VERSION ""

NS_ :

BS_:

BU_: AGSM BCM BSM CADM DMSM DTCM ECM EVCU2 GNMM HCP IPC RFHM SGW TCM
BO_ 258 BRAKE_FD_2: 64 BSM
 SG_ ABSActive : 83|1@0+ (1,0) [0|1] "-" BCM,DTCM,EVCU2,HCP,SGW,TCM
 SG_ AHH_Ready_Status : 123|3@0+ (1,0) [0|6] "" EVCU2
 SG_ Brake_MaxRegen_Ready : 359|2@0+ (1,0) [0|2] "-" EVCU2
 SG_ BrakeBoostPressure : 370|11@0+ (0.1,0) [0|200] "bar" BCM,ECM,EVCU2,IPC,SGW,TCM
 SG_ BrakeBoostStat : 439|4@0+ (1,0) [0|14] "-" EVCU2,SGW
 SG_ BrakeInterventionSts : 103|1@0+ (1,0) [0|1] "-" BCM,DTCM,ECM,EVCU2,HCP,TCM
 SG_ BrakePedalPressure : 386|11@0+ (0.1,0) [0|200] "bar" BCM,ECM,EVCU2,SGW,TCM
 SG_ Brk_Stat : 343|2@0+ (1,0) [0|2] "-" BCM,ECM,IPC,SGW
 SG_ BSM_ESASystemSts : 239|3@0+ (1,0) [0|6] "" BCM
 SG_ BSM_RequesterFunction : 190|3@0+ (1,0) [0|7] "" IPC
 SG_ CRC_BRAKE2 : 447|8@0+ (1,0) [0|255] "-" AGSM,BCM,CADM,DMSM,DTCM,ECM,EVCU2,GNMM,HCP,IPC,RFHM,SGW,TCM
 SG_ ESCActive : 84|1@0+ (1,0) [0|1] "-" BCM,DTCM,EVCU2,SGW,TCM
 SG_ ESP_Sys_Stat : 71|2@0+ (1,0) [0|3] "-" ECM,HCP,TCM
 SG_ HBAActive : 101|1@0+ (1,0) [0|1] "-" BCM
 SG_ HillHolderActive : 174|1@0+ (1,0) [0|1] "-" BCM
 SG_ ImpendingSkid : 205|1@0+ (1,0) [0|1] "-" EVCU2
 SG_ InternalError_BSM : 191|1@0+ (1,0) [0|1] "-" Vector__XXX
 SG_ LatAcceleration_BSM : 19|12@0+ (0.02,-40.96) [-40.96|40.92] "m/s^2" BCM,CADM,DTCM,ECM,EVCU2,HCP,IPC,SGW,TCM
 SG_ LatAccelerationFailSts_BSM : 68|1@0+ (1,0) [0|1] "-" BCM,CADM,DTCM,ECM,HCP,IPC,SGW
 SG_ LongAcceleration_BSM : 35|12@0+ (0.02,-40.96) [-40.96|40.92] "m/s^2" BCM,CADM,DTCM,ECM,EVCU2,HCP,IPC,SGW,TCM
 SG_ LongAccelerationFailSts_BSM : 69|1@0+ (1,0) [0|1] "-" BCM,CADM,DTCM,ECM,EVCU2,HCP,IPC,SGW
 SG_ MessageCounter_BRAKE2 : 435|4@0+ (1,0) [0|15] "-" AGSM,BCM,CADM,DMSM,DTCM,ECM,EVCU2,GNMM,HCP,IPC,RFHM,SGW,TCM
 SG_ MuSplit : 53|2@0+ (1,0) [0|2] "-" Vector__XXX
 SG_ OverSteering : 119|6@0+ (2,0) [0|124] "%" DTCM,EVCU2
 SG_ ParkingGearShiftReq_BSM : 22|3@0+ (1,0) [0|6] "" AGSM,EVCU2,TCM
 SG_ PrefillActive : 86|1@0+ (1,0) [0|1] "-" CADM
 SG_ Slope : 135|8@0+ (1,-100) [-100|154] "%" DTCM
 SG_ UnderSteering : 407|6@0+ (2,0) [0|124] "%" DTCM,EVCU2
 SG_ VehicleSpeedVSOSig : 4|13@0+ (0.0625,0) [0|511.875] "Km/h" AGSM,BCM,CADM,DMSM,DTCM,ECM,EVCU2,GNMM,HCP,IPC,RFHM,SGW,TCM
 SG_ WheelRPM_FL : 279|16@0+ (0.001953125,0) [0|127.9961] "Rev/s" BCM,EVCU2
 SG_ WheelRPM_FR : 295|16@0+ (0.001953125,0) [0|127.9961] "Rev/s" BCM,EVCU2
 SG_ YawRate_BSM : 67|12@0+ (0.08,-163.84) [-163.84|163.68] "deg/s" BCM,CADM,DTCM,SGW
 SG_ YawRateFailSts_BSM : 87|1@0+ (1,0) [0|1] "-" BCM,CADM,DTCM,SGW

BO_ 259 BRAKE_FD_3: 32 BSM
 SG_ CRC__BRAKE3 : 191|8@0+ (1,0) [0|255] "-" BCM,CADM,DTCM,ECM,EVCU2,GNMM,HCP,TCM
 SG_ LatAccelerationOffset_BSM : 127|8@0+ (0.02,-2.56) [-2.56|2.52] "m/s^2" Vector__XXX
 SG_ LHF_FastPulseCounter : 167|8@0+ (1,0) [0|255] "pulse" BCM,CADM,ECM,EVCU2,GNMM,RFHM,SGW
 SG_ LHF_Spin : 23|2@0+ (1,0) [0|3] "-" BCM,CADM,DTCM,ECM,EVCU2,HCP,SGW,TCM
 SG_ LHF_WheelSensorFailSts : 181|1@0+ (1,0) [0|1] "-" BCM,CADM,DTCM,ECM,EVCU2,SGW
 SG_ LHFWheelSpeed : 20|13@0+ (0.0625,0) [0|511.875] "Km/h" BCM,CADM,DTCM,ECM,EVCU2,GNMM,HCP,SGW,TCM
 SG_ LHR_FastPulseCounter : 151|8@0+ (1,0) [0|255] "pulse" BCM,CADM,ECM,EVCU2,GNMM,RFHM,SGW
 SG_ LHR_Spin : 86|2@0+ (1,0) [0|3] "-" BCM,CADM,DTCM,ECM,EVCU2,HCP,SGW,TCM
 SG_ LHR_WheelSensorFailSts : 87|1@0+ (1,0) [0|1] "-" BCM,CADM,DTCM,ECM,EVCU2,SGW
 SG_ LHRWheelSpeed : 4|13@0+ (0.0625,0) [0|511.875] "Km/h" BCM,CADM,DTCM,ECM,EVCU2,GNMM,HCP,SGW,TCM
 SG_ LongAccelerationOffset_BSM : 119|8@0+ (0.02,-2.56) [-2.56|2.52] "m/s^2" Vector__XXX
 SG_ LwsAngleOffset_BSM : 81|10@0+ (0.1,-51.1) [-51.1|51.1] "°" GNMM
 SG_ MessageCounter_BRAKE3 : 179|4@0+ (1,0) [0|15] "-" BCM,CADM,DTCM,ECM,EVCU2,GNMM,HCP,TCM
 SG_ RHF_FastPulseCounter : 175|8@0+ (1,0) [0|255] "pulse" BCM,CADM,ECM,EVCU2,GNMM,RFHM,SGW
 SG_ RHF_Spin : 7|2@0+ (1,0) [0|3] "-" BCM,CADM,DTCM,ECM,EVCU2,HCP,SGW,TCM
 SG_ RHF_WheelSensorFailSts : 182|1@0+ (1,0) [0|1] "-" BCM,CADM,DTCM,ECM,EVCU2,SGW
 SG_ RHFWheelSpeed : 52|13@0+ (0.0625,0) [0|511.875] "Km/h" BCM,CADM,DTCM,ECM,EVCU2,GNMM,HCP,SGW,TCM
 SG_ RHR_FastPulseCounter : 159|8@0+ (1,0) [0|255] "pulse" BCM,CADM,ECM,EVCU2,GNMM,RFHM,SGW
 SG_ RHR_Spin : 102|2@0+ (1,0) [0|3] "-" BCM,CADM,DTCM,ECM,EVCU2,HCP,SGW,TCM
 SG_ RHR_WheelSensorFailSts : 103|1@0+ (1,0) [0|1] "-" BCM,CADM,DTCM,ECM,EVCU2,SGW
 SG_ RHRWheelSpeed : 68|13@0+ (0.0625,0) [0|511.875] "Km/h" BCM,CADM,DTCM,ECM,EVCU2,GNMM,HCP,SGW,TCM

BO_ 609 BRAKE_FD_4: 32 BSM
 SG_ ASRActive : 90|1@0+ (1,0) [0|1] "-" BCM,DTCM,ECM,EVCU2,SGW,TCM
 SG_ BSM_LnchAbrtSts : 33|2@0+ (1,0) [0|2] "-" ECM,IPC,TCM
 SG_ BSM_LnchCtrl_SftBtn_SelectSts : 0|1@0+ (1,0) [0|1] "-" SGW
 SG_ BSM_LnchMode : 55|3@0+ (1,0) [0|6] "-" BCM,DTCM,ECM,IPC,TCM
 SG_ ClampForce : 88|9@0+ (0.1,-0.1) [0|51] "KN" BCM,SGW
 SG_ CODE_CLR_BSM : 160|1@0+ (1,0) [0|1] "-" ECM
 SG_ CRC_BRAKE4 : 191|8@0+ (1,0) [0|255] "-" BCM,CADM,ECM,EVCU2,HCP,IPC,TCM
 SG_ EPB_HMI_Management : 148|5@0+ (1,0) [0|31] "-" IPC,SGW
 SG_ EPBAutoAppSts : 127|1@0+ (1,0) [0|1] "-" Vector__XXX
 SG_ EPBMaintenanceSts : 128|1@0+ (1,0) [0|1] "-" SGW
 SG_ EPBSts : 115|4@0+ (1,0) [0|14] "-" BCM,CADM,DTCM,ECM,EVCU2,IPC,SGW,TCM
 SG_ EPBSwitchPosition : 119|2@0+ (1,0) [0|3] "-" BCM
 SG_ EPBWarningLampReq : 174|2@0+ (1,0) [0|0] "-" BCM,IPC,SGW
 SG_ ESC_OFF_Hrd_Sft_Button_sts : 151|3@0+ (1,0) [0|6] "-" BCM,SGW
 SG_ ESCSysEmsMlfAtv : 159|1@0+ (1,0) [0|0] "-" Vector__XXX
 SG_ LaunchRPMsetting_BSM : 63|6@0+ (100,1000) [1000|7300] "rpm" SGW
 SG_ LnchCtrl_DisPopupSts : 52|4@0+ (1,0) [0|14] "-" IPC
 SG_ MessageCounter_BRAKE4 : 179|4@0+ (1,0) [0|15] "-" BCM,CADM,ECM,EVCU2,HCP,IPC,TCM
 SG_ MIL_OnRq_BSM : 172|1@0+ (1,0) [0|1] "-" ECM,SGW
 SG_ MSRActive : 92|1@0+ (1,0) [0|1] "-" BCM,EVCU2
 SG_ RedLampReq : 131|2@0+ (1,0) [0|3] "-" IPC
 SG_ REPRGD_PFC_CLR_BSM : 175|1@0+ (1,0) [0|1] "-" ECM
 SG_ TravelDistance : 87|8@0+ (1,0) [0|255] "m" ECM,EVCU2,IPC,SGW

BO_ 1155 BRAKE_FD_5: 32 BSM
 SG_ ABSFailSts : 87|1@0+ (1,0) [0|1] "-" BCM,ECM,EVCU2,IPC,SGW
 SG_ ACCEngaged : 92|1@0+ (1,0) [0|1] "-" DTCM,ECM,EVCU2,SGW,TCM
 SG_ BSM_THA_Brk_Resp : 15|2@0+ (1,0) [0|3] "-" BCM
 SG_ BSMSysSts : 89|2@0+ (1,0) [0|3] "-" SGW
 SG_ CMMIntervention : 86|1@0+ (1,0) [0|1] "-" Vector__XXX
 SG_ CRC_BRAKE5 : 191|8@0+ (1,0) [0|255] "-" BCM,DTCM,ECM,EVCU2,IPC,TCM
 SG_ EBDFailSts : 84|1@0+ (1,0) [0|1] "-" BCM,IPC,SGW
 SG_ ERMActive : 111|1@0+ (1,0) [0|1] "-" BCM,DTCM
 SG_ ESCFailSts : 83|1@0+ (1,0) [0|1] "-" BCM,ECM,EVCU2,IPC,SGW
 SG_ ESCIntervention : 82|1@0+ (1,0) [0|1] "-" BCM,DTCM,EVCU2,IPC
 SG_ Function2Sts : 94|1@0+ (1,0) [0|1] "-" BCM,DTCM,EVCU2,IPC,SGW,TCM
 SG_ FunctionFailSts : 81|1@0+ (1,0) [0|1] "-" Vector__XXX
 SG_ FunctionIntervention : 80|1@0+ (1,0) [0|1] "-" DTCM
 SG_ FunctionSts : 95|1@0+ (1,0) [0|1] "-" BCM,DTCM,EVCU2,IPC
 SG_ HDCUserFdBck : 124|2@0+ (1,0) [0|3] "-" BCM
 SG_ HillHolderFailSts : 7|1@0+ (1,0) [0|1] "-" SGW
 SG_ LnchCtrl_UserFdBck : 1|2@0+ (1,0) [0|2] "-" BCM
 SG_ MessageCounter_BRAKE5 : 179|4@0+ (1,0) [0|15] "-" BCM,DTCM,ECM,EVCU2,IPC,TCM
 SG_ RollsModeAct : 91|1@0+ (1,0) [0|1] "-" DTCM,ECM,EVCU2
 SG_ TSCActive : 110|1@0+ (1,0) [0|1] "-" BCM

BO_ 205 BRAKE_FD_6: 64 BSM
 SG_ Cmnd_TotBrkFrict_AxleTorq : 126|15@0+ (2,0) [0|65532] "Nm" EVCU2
 SG_ CRC_BRAKE_FD_6 : 447|8@0+ (1,0) [0|255] "-" ECM,EVCU2
 SG_ DriverReq_AxleTrq_Enabled_BSM : 175|4@0+ (1,0) [0|15] "" ECM,EVCU2
 SG_ DriverRequested_AxleTrq_BSM : 159|16@0+ (2,-65534) [-65534|65536] "Nm" DTCM,ECM,EVCU2
 SG_ DrvrIntd_TotalBrk_AxleTorq : 142|15@0+ (2,0) [0|65532] "Nm" BCM,EVCU2
 SG_ FrontAxle_Max_Rq_BSM : 55|1@0+ (1,0) [0|1] "" EVCU2
 SG_ FrontAxle_Min_Rq_BSM : 54|1@0+ (1,0) [0|1] "" EVCU2
 SG_ FrontAxle_Rq_BSM : 63|16@0+ (2,-65534) [-65534|65536] "Nm" EVCU2
 SG_ MessageCounter_BRAKE_FD_6 : 435|4@0+ (1,0) [0|15] "-" ECM,EVCU2
 SG_ OPD_Hold_Status : 49|2@0+ (1,0) [0|3] "" EVCU2
 SG_ RearAxle_Max_Rq_BSM : 53|1@0+ (1,0) [0|1] "" EVCU2
 SG_ RearAxle_Min_Rq_BSM : 52|1@0+ (1,0) [0|1] "" EVCU2
 SG_ RearAxle_Rq_BSM : 79|16@0+ (2,-65534) [-65534|65536] "Nm" EVCU2
 SG_ Regen_AxleTorque_Req : 110|15@0+ (2,0) [0|65532] "Nm" EVCU2
 SG_ TotalAxle_Max_Rq_BSM : 51|1@0+ (1,0) [0|1] "" DTCM,ECM,TCM
 SG_ TotalAxle_Min_Rq_BSM : 50|1@0+ (1,0) [0|1] "" ECM,TCM
 SG_ TotalAxle_Rq_BSM : 95|16@0+ (2,-65534) [-65534|65536] "Nm" DTCM,ECM,SGW,TCM
 SG_ WED_MODE_RQ : 47|2@0+ (1,0) [0|3] "" EVCU2

BO_ 514 BRAKE_FD_7: 32 BSM
 SG_ AEB_Type_Brk : 67|4@0+ (1,0) [0|14] "-" BCM,CADM
 SG_ Brake_OpStat_Prim : 82|3@0+ (1,0) [0|5] "" CADM
 SG_ BrakePdlPosn : 63|8@0+ (0.4,0) [0|100] "%" BCM,ECM,EVCU2,SGW,TCM
 SG_ BrkPdl_Flt : 86|1@0+ (1,0) [0|1] "-" BCM,DTCM,ECM,EVCU2,SGW
 SG_ BrkPdl_Stat : 85|2@0+ (1,0) [0|2] "-" BCM,CADM,DTCM,ECM,EVCU2,RFHM,SGW,TCM
 SG_ BSM_OpStat : 74|3@0+ (1,0) [0|5] "" BCM,CADM
 SG_ BSM_ReadyForESS : 181|2@0+ (1,0) [0|2] "-" BCM,ECM
 SG_ CRC_BRAKE7 : 191|8@0+ (1,0) [0|255] "-" BCM,CADM,DTCM,ECM,EVCU2,HCP,TCM
 SG_ MessageCounter_BRAKE7 : 179|4@0+ (1,0) [0|15] "-" BCM,CADM,DTCM,ECM,EVCU2,HCP,TCM
 SG_ PAM_Brk_Rq_RspSts : 28|2@0+ (1,0) [0|3] "-" BCM,IPC
 SG_ R_DIFF_TRQ_RQ : 40|9@0+ (10,0) [0|5100] "Nm" DTCM,EVCU2
 SG_ Rear_Diff_BSM_RQ : 77|2@0+ (1,0) [0|2] "-" BCM,DTCM,EVCU2
 SG_ TrlrBrkRq : 103|6@0+ (2,0) [0|100] "%" BCM

BO_ 257 BRAKE2_FD_1: 64 BCM
 SG_ CRC_BRAKE2_1 : 447|8@0+ (1,0) [0|255] "-" DTCM
 SG_ Ft_RrAxleCoupling_TrqRq_B2 : 143|8@0+ (12,0) [0|3060] "Nm" DTCM
 SG_ Ft_RrTrqCoupling_ModeRq_B2 : 158|2@0+ (1,0) [0|3] "-" DTCM
 SG_ MessageCounter_BRAKE2_1 : 435|4@0+ (1,0) [0|15] "-" DTCM

BO_ 524 BRAKE2_FD_2: 32 BCM
 SG_ Brake_OpStat_Sec : 53|3@0+ (1,0) [0|5] "" CADM
 SG_ BSM2_OpStat : 50|3@0+ (1,0) [0|5] "" BSM,CADM
 SG_ CRC_BRAKE2_2 : 191|8@0+ (1,0) [0|255] "-" BSM,CADM
 SG_ MessageCounter_BRAKE2_2 : 179|4@0+ (1,0) [0|15] "-" BSM,CADM
 SG_ VehicleStandStillSts_B2 : 47|2@0+ (1,0) [0|2] "" CADM

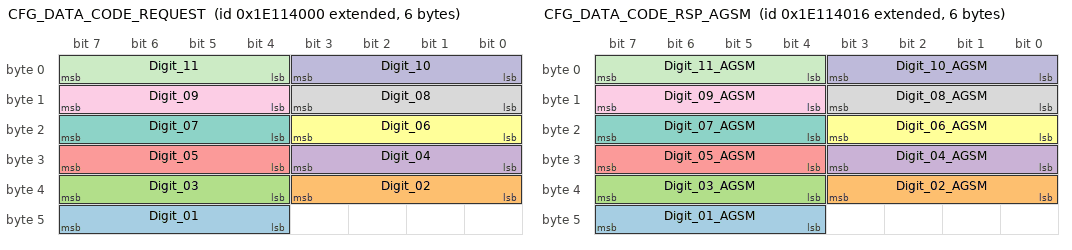
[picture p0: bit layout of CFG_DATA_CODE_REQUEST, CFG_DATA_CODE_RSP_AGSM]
BO_ 2651930624 CFG_DATA_CODE_REQUEST: 6 BCM
 SG_ Digit_01 : 47|4@0+ (1,0) [0|15] "" AGSM,BSM,CADM,DMSM,DTCM,ECM,EVCU2,GNMM,HCP,IPC,RFHM,SGW,TCM
 SG_ Digit_02 : 35|4@0+ (1,0) [0|15] "" AGSM,BSM,CADM,DMSM,DTCM,ECM,EVCU2,GNMM,HCP,IPC,RFHM,SGW,TCM
 SG_ Digit_03 : 39|4@0+ (1,0) [0|15] "" AGSM,BSM,CADM,DMSM,DTCM,ECM,EVCU2,GNMM,HCP,IPC,RFHM,SGW,TCM
 SG_ Digit_04 : 27|4@0+ (1,0) [0|15] "" AGSM,BSM,CADM,DMSM,DTCM,ECM,EVCU2,GNMM,HCP,IPC,RFHM,SGW,TCM
 SG_ Digit_05 : 31|4@0+ (1,0) [0|15] "" AGSM,BSM,CADM,DMSM,DTCM,ECM,EVCU2,GNMM,HCP,IPC,RFHM,SGW,TCM
 SG_ Digit_06 : 19|4@0+ (1,0) [0|15] "" AGSM,BSM,CADM,DMSM,DTCM,ECM,EVCU2,GNMM,HCP,IPC,RFHM,SGW,TCM
 SG_ Digit_07 : 23|4@0+ (1,0) [0|15] "" AGSM,BSM,CADM,DMSM,DTCM,ECM,EVCU2,GNMM,HCP,IPC,RFHM,SGW,TCM
 SG_ Digit_08 : 11|4@0+ (1,0) [0|15] "" AGSM,BSM,CADM,DMSM,DTCM,ECM,EVCU2,GNMM,HCP,IPC,RFHM,SGW,TCM
 SG_ Digit_09 : 15|4@0+ (1,0) [0|15] "" AGSM,BSM,CADM,DMSM,DTCM,ECM,EVCU2,GNMM,HCP,IPC,RFHM,SGW,TCM
 SG_ Digit_10 : 3|4@0+ (1,0) [0|15] "" AGSM,BSM,CADM,DMSM,DTCM,ECM,EVCU2,GNMM,HCP,IPC,RFHM,SGW,TCM
 SG_ Digit_11 : 7|4@0+ (1,0) [0|15] "" AGSM,BSM,CADM,DMSM,DTCM,ECM,EVCU2,GNMM,HCP,IPC,RFHM,SGW,TCM

BO_ 2651930646 CFG_DATA_CODE_RSP_AGSM: 6 AGSM
 SG_ Digit_01_AGSM : 47|4@0+ (1,0) [0|15] "-" BCM
 SG_ Digit_02_AGSM : 35|4@0+ (1,0) [0|15] "-" BCM
 SG_ Digit_03_AGSM : 39|4@0+ (1,0) [0|15] "-" BCM
 SG_ Digit_04_AGSM : 27|4@0+ (1,0) [0|15] "-" BCM
 SG_ Digit_05_AGSM : 31|4@0+ (1,0) [0|15] "-" BCM
 SG_ Digit_06_AGSM : 19|4@0+ (1,0) [0|15] "-" BCM
 SG_ Digit_07_AGSM : 23|4@0+ (1,0) [0|15] "-" BCM
 SG_ Digit_08_AGSM : 11|4@0+ (1,0) [0|15] "-" BCM
 SG_ Digit_09_AGSM : 15|4@0+ (1,0) [0|15] "-" BCM
 SG_ Digit_10_AGSM : 3|4@0+ (1,0) [0|15] "-" BCM
 SG_ Digit_11_AGSM : 7|4@0+ (1,0) [0|15] "-" BCM

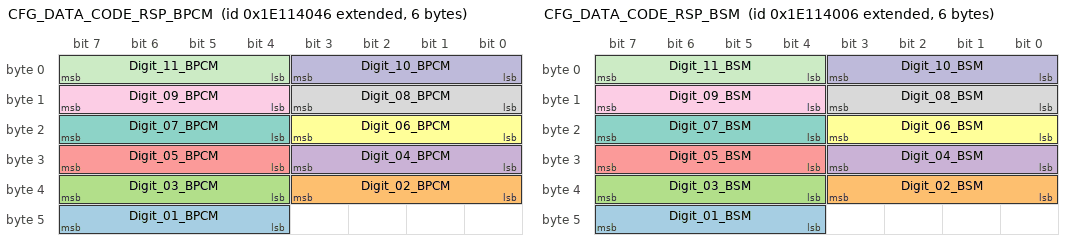
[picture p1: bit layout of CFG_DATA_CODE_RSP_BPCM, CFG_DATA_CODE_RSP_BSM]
BO_ 2651930694 CFG_DATA_CODE_RSP_BPCM: 6 EVCU2
 SG_ Digit_01_BPCM : 47|4@0+ (1,0) [0|15] "-" BCM
 SG_ Digit_02_BPCM : 35|4@0+ (1,0) [0|15] "-" BCM
 SG_ Digit_03_BPCM : 39|4@0+ (1,0) [0|15] "-" BCM
 SG_ Digit_04_BPCM : 27|4@0+ (1,0) [0|15] "-" BCM
 SG_ Digit_05_BPCM : 31|4@0+ (1,0) [0|15] "-" BCM
 SG_ Digit_06_BPCM : 19|4@0+ (1,0) [0|15] "-" BCM
 SG_ Digit_07_BPCM : 23|4@0+ (1,0) [0|15] "-" BCM
 SG_ Digit_08_BPCM : 11|4@0+ (1,0) [0|15] "-" BCM
 SG_ Digit_09_BPCM : 15|4@0+ (1,0) [0|15] "-" BCM
 SG_ Digit_10_BPCM : 3|4@0+ (1,0) [0|15] "-" BCM
 SG_ Digit_11_BPCM : 7|4@0+ (1,0) [0|15] "-" BCM

BO_ 2651930630 CFG_DATA_CODE_RSP_BSM: 6 BSM
 SG_ Digit_01_BSM : 47|4@0+ (1,0) [0|15] "-" BCM
 SG_ Digit_02_BSM : 35|4@0+ (1,0) [0|15] "-" BCM
 SG_ Digit_03_BSM : 39|4@0+ (1,0) [0|15] "-" BCM
 SG_ Digit_04_BSM : 27|4@0+ (1,0) [0|15] "-" BCM
 SG_ Digit_05_BSM : 31|4@0+ (1,0) [0|15] "-" BCM
 SG_ Digit_06_BSM : 19|4@0+ (1,0) [0|15] "-" BCM
 SG_ Digit_07_BSM : 23|4@0+ (1,0) [0|15] "-" BCM
 SG_ Digit_08_BSM : 11|4@0+ (1,0) [0|15] "-" BCM
 SG_ Digit_09_BSM : 15|4@0+ (1,0) [0|15] "-" BCM
 SG_ Digit_10_BSM : 3|4@0+ (1,0) [0|15] "-" BCM
 SG_ Digit_11_BSM : 7|4@0+ (1,0) [0|15] "-" BCM

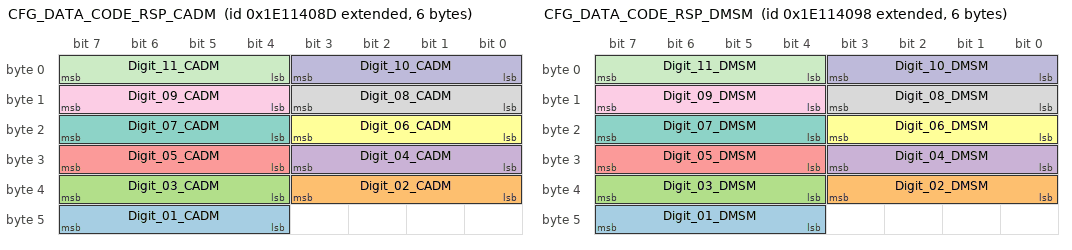
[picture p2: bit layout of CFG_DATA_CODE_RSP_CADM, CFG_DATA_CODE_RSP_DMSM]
BO_ 2651930765 CFG_DATA_CODE_RSP_CADM: 6 CADM
 SG_ Digit_01_CADM : 47|4@0+ (1,0) [0|15] "-" BCM
 SG_ Digit_02_CADM : 35|4@0+ (1,0) [0|15] "-" BCM
 SG_ Digit_03_CADM : 39|4@0+ (1,0) [0|15] "-" BCM
 SG_ Digit_04_CADM : 27|4@0+ (1,0) [0|15] "-" BCM
 SG_ Digit_05_CADM : 31|4@0+ (1,0) [0|15] "-" BCM
 SG_ Digit_06_CADM : 19|4@0+ (1,0) [0|15] "-" BCM
 SG_ Digit_07_CADM : 23|4@0+ (1,0) [0|15] "-" BCM
 SG_ Digit_08_CADM : 11|4@0+ (1,0) [0|15] "-" BCM
 SG_ Digit_09_CADM : 15|4@0+ (1,0) [0|15] "-" BCM
 SG_ Digit_10_CADM : 3|4@0+ (1,0) [0|15] "-" BCM
 SG_ Digit_11_CADM : 7|4@0+ (1,0) [0|15] "-" BCM

BO_ 2651930776 CFG_DATA_CODE_RSP_DMSM: 6 DMSM
 SG_ Digit_01_DMSM : 47|4@0+ (1,0) [0|15] "-" BCM
 SG_ Digit_02_DMSM : 35|4@0+ (1,0) [0|15] "-" BCM
 SG_ Digit_03_DMSM : 39|4@0+ (1,0) [0|15] "-" BCM
 SG_ Digit_04_DMSM : 27|4@0+ (1,0) [0|15] "-" BCM
 SG_ Digit_05_DMSM : 31|4@0+ (1,0) [0|15] "-" BCM
 SG_ Digit_06_DMSM : 19|4@0+ (1,0) [0|15] "-" BCM
 SG_ Digit_07_DMSM : 23|4@0+ (1,0) [0|15] "-" BCM
 SG_ Digit_08_DMSM : 11|4@0+ (1,0) [0|15] "-" BCM
 SG_ Digit_09_DMSM : 15|4@0+ (1,0) [0|15] "-" BCM
 SG_ Digit_10_DMSM : 3|4@0+ (1,0) [0|15] "-" BCM
 SG_ Digit_11_DMSM : 7|4@0+ (1,0) [0|15] "-" BCM

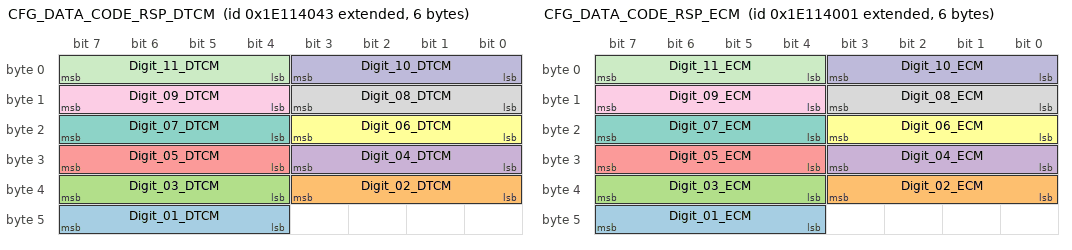
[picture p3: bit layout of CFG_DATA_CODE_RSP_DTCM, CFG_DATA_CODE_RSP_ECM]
BO_ 2651930691 CFG_DATA_CODE_RSP_DTCM: 6 DTCM
 SG_ Digit_01_DTCM : 47|4@0+ (1,0) [0|15] "-" BCM
 SG_ Digit_02_DTCM : 35|4@0+ (1,0) [0|15] "-" BCM
 SG_ Digit_03_DTCM : 39|4@0+ (1,0) [0|15] "-" BCM
 SG_ Digit_04_DTCM : 27|4@0+ (1,0) [0|15] "-" BCM
 SG_ Digit_05_DTCM : 31|4@0+ (1,0) [0|15] "-" BCM
 SG_ Digit_06_DTCM : 19|4@0+ (1,0) [0|15] "-" BCM
 SG_ Digit_07_DTCM : 23|4@0+ (1,0) [0|15] "-" BCM
 SG_ Digit_08_DTCM : 11|4@0+ (1,0) [0|15] "-" BCM
 SG_ Digit_09_DTCM : 15|4@0+ (1,0) [0|15] "-" BCM
 SG_ Digit_10_DTCM : 3|4@0+ (1,0) [0|15] "-" BCM
 SG_ Digit_11_DTCM : 7|4@0+ (1,0) [0|15] "-" BCM

BO_ 2651930625 CFG_DATA_CODE_RSP_ECM: 6 ECM
 SG_ Digit_01_ECM : 47|4@0+ (1,0) [0|15] "-" BCM
 SG_ Digit_02_ECM : 35|4@0+ (1,0) [0|15] "-" BCM
 SG_ Digit_03_ECM : 39|4@0+ (1,0) [0|15] "-" BCM
 SG_ Digit_04_ECM : 27|4@0+ (1,0) [0|15] "-" BCM
 SG_ Digit_05_ECM : 31|4@0+ (1,0) [0|15] "-" BCM
 SG_ Digit_06_ECM : 19|4@0+ (1,0) [0|15] "-" BCM
 SG_ Digit_07_ECM : 23|4@0+ (1,0) [0|15] "-" BCM
 SG_ Digit_08_ECM : 11|4@0+ (1,0) [0|15] "-" BCM
 SG_ Digit_09_ECM : 15|4@0+ (1,0) [0|15] "-" BCM
 SG_ Digit_10_ECM : 3|4@0+ (1,0) [0|15] "-" BCM
 SG_ Digit_11_ECM : 7|4@0+ (1,0) [0|15] "-" BCM

BO_TX_BU_ 2651930694 : EVCU2,HCP;
CM_ SG_ 258 ABSActive "This signal is set to Active when the ABS functionality is active.";
CM_ SG_ 258 AHH_Ready_Status "AHH_Ready_Status";
CM_ SG_ 258 Brake_MaxRegen_Ready "maximum Brake regen ready";
CM_ SG_ 258 BrakeBoostPressure "Pressure Information from Brake Booster Pressure Sensor";
CM_ SG_ 258 BrakeBoostStat "eBoost System Status INIT, eBOOST, PUSH-THROUGH, SNA";
CM_ SG_ 258 BrakeInterventionSts "This signal is ?active? when the brake intervention is due to BSM events and ?not active? when the brake intervention is due to the driver";
CM_ SG_ 258 BrakePedalPressure "Pressure Information from Brake Pedal Simulator Pressure Sensor";
CM_ SG_ 258 Brk_Stat "Brake state";
CM_ SG_ 258 BSM_ESASystemSts "Brake System ESA Status";
CM_ SG_ 258 BSM_RequesterFunction "BSM Requester function";
CM_ SG_ 258 CRC_BRAKE2 "CRC according to SAE J1850 standard at each frame transmission.";
CM_ SG_ 258 ESCActive "This signal is set to Active when the brake intervention by ESC is active.";
CM_ SG_ 258 ESP_Sys_Stat "0";
CM_ SG_ 258 HBAActive "0";
CM_ SG_ 258 HillHolderActive "0";
CM_ SG_ 258 ImpendingSkid "Impending Skid; impending skid false = [0], impending skid true = [1]";
CM_ SG_ 258 InternalError_BSM "This signal indicates if an internal error has been processed";
CM_ SG_ 258 LatAcceleration_BSM "This signal indicates the Lateral Acceleration Value";
CM_ SG_ 258 LatAccelerationFailSts_BSM "This signal indicates the status of Lateral Acceleration Signal";
CM_ SG_ 258 LongAcceleration_BSM "This signal indicates the Longitudinal Acceleration Value";
CM_ SG_ 258 LongAccelerationFailSts_BSM "This signal indicates the status of Longitudinal acceleration signal";
CM_ SG_ 258 MessageCounter_BRAKE2 "This signal is a counter used for safety checks strategies. This counter is incremented of 1 (one) unit at each frame transmission.";
CM_ SG_ 258 MuSplit "0";
CM_ SG_ 258 OverSteering "0";
CM_ SG_ 258 ParkingGearShiftReq_BSM "CVPAM Request to autonomously shift gears";
CM_ SG_ 258 PrefillActive "This signal indicates the prefill function status.";
CM_ SG_ 258 Slope "Slope value detected by BSM";
CM_ SG_ 258 UnderSteering "0";
CM_ SG_ 258 VehicleSpeedVSOSig "It is the average vehicle speed calculated.";
CM_ SG_ 258 WheelRPM_FL "Wheel RPM front left";
CM_ SG_ 258 WheelRPM_FR "Wheel RPM front right";
CM_ SG_ 258 YawRate_BSM "This signal indicates the Yaw Rate Value";
CM_ SG_ 258 YawRateFailSts_BSM "This signal indicates the Status of Yaw Rate Signal";
CM_ SG_ 259 CRC__BRAKE3 "CRC according to SAE J1850 standard at each frame transmission.";
CM_ SG_ 259 LatAccelerationOffset_BSM "LatAccelerationOffset_BSM";
CM_ SG_ 259 LHF_FastPulseCounter "This signal is the left front wheel pulse counter.";
CM_ SG_ 259 LHF_Spin "This signal indicates the left hand front wheel status";
CM_ SG_ 259 LHF_WheelSensorFailSts "This signal indicates the fail status of LHF sensor";
CM_ SG_ 259 LHFWheelSpeed "This is the value of the left front wheel speed";
CM_ SG_ 259 LHR_FastPulseCounter "This signal is the left rear wheel pulse counter.";
CM_ SG_ 259 LHR_Spin "This signal indicates the left hand rear wheel status";
CM_ SG_ 259 LHR_WheelSensorFailSts "This signal indicates the fail status of LHR sensor";
CM_ SG_ 259 LHRWheelSpeed "This is the value of the left rear wheel speed";
CM_ SG_ 259 LongAccelerationOffset_BSM "LongAccelerationOffset_BSM";
CM_ SG_ 259 LwsAngleOffset_BSM "LwsAngleOffset_BSM";
CM_ SG_ 259 MessageCounter_BRAKE3 "This signal is a counter used for safety checks strategies. This counter is incremented of 1 (one) unit at each frame transmission.";
CM_ SG_ 259 RHF_FastPulseCounter "This signal is the right front wheel pulse counter.";
CM_ SG_ 259 RHF_Spin "This signal indicates the right hand front wheel status";
CM_ SG_ 259 RHF_WheelSensorFailSts "This signal indicates the fail status of RHF sensor";
CM_ SG_ 259 RHFWheelSpeed "This is the value of the right front wheel speed";
CM_ SG_ 259 RHR_FastPulseCounter "This signal is the right rear wheel pulse counter.";
CM_ SG_ 259 RHR_Spin "This signal indicates the right hand rear wheel status";
CM_ SG_ 259 RHR_WheelSensorFailSts "This signal indicates the fail status of RHR sensor";
CM_ SG_ 259 RHRWheelSpeed "This is the value of the right rear wheel speed";
CM_ SG_ 609 ASRActive "This signal is set to Active when the intervention by ASR is Active";
CM_ SG_ 609 BSM_LnchAbrtSts "Launch Control Abort Status";
CM_ SG_ 609 BSM_LnchCtrl_SftBtn_SelectSts "Soft button launch selected; Launch selected = [1]";
CM_ SG_ 609 BSM_LnchMode "Launch Control Status";
CM_ SG_ 609 ClampForce "This signal is used to give information about the EPB Clamp Force";
CM_ SG_ 609 CODE_CLR_BSM "Clear emission related faults";
CM_ SG_ 609 CRC_BRAKE4 "CRC according to SAE J1850 standard at each frame transmission.";
CM_ SG_ 609 EPB_HMI_Management "Management IPC/VP pop-up";
CM_ SG_ 609 EPBAutoAppSts "Status of AutoApply Functionality";
CM_ SG_ 609 EPBMaintenanceSts "Status of Maintenance Functionality";
CM_ SG_ 609 EPBSts "0";
CM_ SG_ 609 EPBSwitchPosition "This signal is used to give information about the postition of the EPB switch";
CM_ SG_ 609 EPBWarningLampReq "EPB warning (fault) lamp active request";
CM_ SG_ 609 ESC_OFF_Hrd_Sft_Button_sts "ESC hard button status";
CM_ SG_ 609 ESCSysEmsMlfAtv "ESC emissions related malfunction active";
CM_ SG_ 609 LaunchRPMsetting_BSM "BSM  Launch RPM setting";
CM_ SG_ 609 LnchCtrl_DisPopupSts "Launch Control Display Popup Status";
CM_ SG_ 609 MessageCounter_BRAKE4 "This signal is a counter used for safety checks strategies. This counter is incremented of 1 (one) unit at each frame transmission.";
CM_ SG_ 609 MIL_OnRq_BSM "MIL switch on request";
CM_ SG_ 609 MSRActive "0";
CM_ SG_ 609 RedLampReq "This signal is used to request the EPB RED Indication";
CM_ SG_ 609 REPRGD_PFC_CLR_BSM "Set readiness to \"incomplete\"";
CM_ SG_ 609 TravelDistance "This signal indicates the travel distance value.";
CM_ SG_ 1155 ABSFailSts "0";
CM_ SG_ 1155 ACCEngaged "ACC is engaged";
CM_ SG_ 1155 BSM_THA_Brk_Resp "BSM braking status for trailer hitch assist";
CM_ SG_ 1155 BSMSysSts "This signal is used by BSM to indicate its mode";
CM_ SG_ 1155 CMMIntervention "0";
CM_ SG_ 1155 CRC_BRAKE5 "CRC according to SAE J1850 standard at each frame transmission.";
CM_ SG_ 1155 EBDFailSts "0";
CM_ SG_ 1155 ERMActive "This signal is set to \"active\" when Electronic Roll Mitigation functionality is acting.";
CM_ SG_ 1155 ESCFailSts "0";
CM_ SG_ 1155 ESCIntervention "0";
CM_ SG_ 1155 Function2Sts "Indicates the partial off status of the ESC/TCS system. [0]: Not_Active - Indicates that the ESC/TCS system is enabled, [1]: Active - Indicates that the ESC/TCS engine management is disabled";
CM_ SG_ 1155 FunctionFailSts "This signal indicates the health status of the traction control system. [0]: Fail_Not_Present, [1]: Fail_Present";
CM_ SG_ 1155 FunctionIntervention "This signal indicates the BSM is actively controlling the vehicle through either engine torque management or brake pressure modulation.";
CM_ SG_ 1155 FunctionSts "Indicates the full off status of the ESC/TCS system. [0]: Not_Active - Indicates that the ESC/TCS system is enabled, [1]: Active - Indicates that the ESC/TCS system is completely disabled";
CM_ SG_ 1155 HDCUserFdBck "This signal is used by BSM drive the feedback to the driver command";
CM_ SG_ 1155 HillHolderFailSts "Hill Holder function fail status";
CM_ SG_ 1155 LnchCtrl_UserFdBck "Launch Comtrol Hardn Button LED status";
CM_ SG_ 1155 MessageCounter_BRAKE5 "This signal is a counter used for safety checks strategies. This counter is incremented of 1 (one) unit at each frame transmission.";
CM_ SG_ 1155 RollsModeAct "This signal indicates when the brake system module is in the Rolls Test mode.";
CM_ SG_ 1155 TSCActive "This signal is set to \"active\" when Trailer Sway Control functionality is acting";
CM_ SG_ 205 Cmnd_TotBrkFrict_AxleTorq "Commanded Total Brake Friction torque in Axle domain";
CM_ SG_ 205 CRC_BRAKE_FD_6 "CRC according to SAE J1850 standard at each frame transmission.";
CM_ SG_ 205 DriverReq_AxleTrq_Enabled_BSM "It indicates the request to enable virtual driver torque interface for BSM driver functions";
CM_ SG_ 205 DriverRequested_AxleTrq_BSM "Virtual driver torque request from BSM";
CM_ SG_ 205 DrvrIntd_TotalBrk_AxleTorq "Driver Simulated Brake Torque, Regenerative B raking and Friction Braking";
CM_ SG_ 205 FrontAxle_Max_Rq_BSM "Front axle traction torque max limit flag. Active = [1]";
CM_ SG_ 205 FrontAxle_Min_Rq_BSM "Front axle traction torque min limit flag. Active = [1]";
CM_ SG_ 205 FrontAxle_Rq_BSM "Front axle traction control torque request";
CM_ SG_ 205 MessageCounter_BRAKE_FD_6 "This signal is a counter used for safety checks strategies. This counter is incremented of 1 (one) unit at each frame transmission.";
CM_ SG_ 205 OPD_Hold_Status "Hold status from the brake controller in One Pedal Drive";
CM_ SG_ 205 RearAxle_Max_Rq_BSM "Rear axle traction torque max limit  flag. Active = [1]";
CM_ SG_ 205 RearAxle_Min_Rq_BSM "Rear axle traction torque min limit  flag. Active = [1]";
CM_ SG_ 205 RearAxle_Rq_BSM "Rear axle traction control torque request";
CM_ SG_ 205 Regen_AxleTorque_Req "Regenerative Braking Torque request in Axle domain";
CM_ SG_ 205 TotalAxle_Max_Rq_BSM "Combined axle traction torque max limit flag. Active = [1]";
CM_ SG_ 205 TotalAxle_Min_Rq_BSM "Combined axle traction torque min limit flag. Active = [1]";
CM_ SG_ 205 TotalAxle_Rq_BSM "Combined axle traction torque request";
CM_ SG_ 205 WED_MODE_RQ "WED Requested Center Differential State";
CM_ SG_ 514 AEB_Type_Brk "AEB type brake signal";
CM_ SG_ 514 Brake_OpStat_Prim "Capability of the Braking system to perform deceleration and/or stability control as reported by primary actuator";
CM_ SG_ 514 BrakePdlPosn "Brake pedal travel sensor 0-100% (0 = upstop)";
CM_ SG_ 514 BrkPdl_Flt "Brake Pedal Fault is active, 1=Faulted";
CM_ SG_ 514 BrkPdl_Stat "Brake pedal state";
CM_ SG_ 514 BSM_OpStat "Capability of the primary brake control module to provide deceleration and/or stability control";
CM_ SG_ 514 BSM_ReadyForESS "BSM Stop Start Ready status";
CM_ SG_ 514 CRC_BRAKE7 "CRC according to SAE J1850 standard at each frame transmission.";
CM_ SG_ 514 MessageCounter_BRAKE7 "This signal is a counter used for safety checks strategies. This counter is incremented of 1 (one) unit at each frame transmission.";
CM_ SG_ 514 PAM_Brk_Rq_RspSts "PAM Brake Request Response Status made by the BSM for Park Assist with Stop.";
CM_ SG_ 514 R_DIFF_TRQ_RQ "Desired Torque for Rear Diff.";
CM_ SG_ 514 Rear_Diff_BSM_RQ "ESP Requested Rear Differential State";
CM_ SG_ 514 TrlrBrkRq "Trailer brake request percentage";
CM_ SG_ 257 CRC_BRAKE2_1 "CRC according to SAE J1850 standard at each frame transmission.";
CM_ SG_ 257 Ft_RrAxleCoupling_TrqRq_B2 "Desired Torque for Center Diff";
CM_ SG_ 257 Ft_RrTrqCoupling_ModeRq_B2 "ESP Requested Center Differential State";
CM_ SG_ 257 MessageCounter_BRAKE2_1 "This signal is a counter used for safety checks strategies. This counter is incremented of 1 (one) unit at each frame transmission.";
CM_ SG_ 524 Brake_OpStat_Sec "Capability of the Braking system to perform deceleration and/or stability control as reported by the secondary actuator.";
CM_ SG_ 524 BSM2_OpStat "Capability of the secondary brake control module to provide deceleration and/or stability control";
CM_ SG_ 524 CRC_BRAKE2_2 "CRC according to SAE J1850 standard at each frame transmission.";
CM_ SG_ 524 MessageCounter_BRAKE2_2 "This signal is a counter used for safety checks strategies. This counter is incremented of 1 (one) unit at each frame transmission.";
CM_ SG_ 524 VehicleStandStillSts_B2 "VehicleStandStillSts_B2";

BA_DEF_ SG_ "GenSigStartValue" INT 0 2147483647;
BA_DEF_ SG_ "GenSigInactiveValue" INT 0 2147483647;
BA_DEF_ SG_ "GenSigSendType" ENUM "NotUsed","OnWrite","OnWriteWithRepetition","OnChange","OnChangeWithRepetition","IfActive","IfActiveWithRepetition","NoSigSendType";
BA_DEF_ SG_ "SystemSignalLongSymbol" STRING ;
BA_DEF_ SG_ "GenSigTimeoutTime_AGSM" INT 0 65535;
BA_DEF_ SG_ "GenSigTimeoutTime_BCM" INT 0 65535;
BA_DEF_ SG_ "GenSigTimeoutTime_BSM" INT 0 65535;
BA_DEF_ SG_ "GenSigTimeoutTime_CADM" INT 0 65535;
BA_DEF_ SG_ "GenSigTimeoutTime_DMSM" INT 0 65535;
BA_DEF_ SG_ "GenSigTimeoutTime_DTCM" INT 0 65535;
BA_DEF_ SG_ "GenSigTimeoutTime_ECM" INT 0 65535;
BA_DEF_ SG_ "GenSigTimeoutTime_EVCU2" INT 0 65535;
BA_DEF_ SG_ "GenSigTimeoutTime_GNMM" INT 0 65535;
BA_DEF_ SG_ "GenSigTimeoutTime_HCP" INT 0 65535;
BA_DEF_ SG_ "GenSigTimeoutTime_IPC" INT 0 65535;
BA_DEF_ SG_ "GenSigTimeoutTime_RFHM" INT 0 65535;
BA_DEF_ SG_ "GenSigTimeoutTime_SGW" INT 0 65535;
BA_DEF_ SG_ "GenSigTimeoutTime_TCM" INT 0 65535;
BA_DEF_ BO_ "DiagRequest" ENUM "No","Yes";
BA_DEF_ BO_ "Type" ENUM "P","C","PE","COC","PE_Cntrl","E","E_Cntrl","OC","S","BAF","DC","EM","MM","ISO-TP","-";
BA_DEF_ BO_ "DiagResponse" ENUM "No","Yes";
BA_DEF_ BO_ "NmMessage" ENUM "No","Yes";
BA_DEF_ BO_ "GenMsgSendType" ENUM "Cyclic","NotUsed","NotUsed","NotUsed","NotUsed","NotUsed","NotUsed","NotUsed","NoMsgSendType";
BA_DEF_ BO_ "GenMsgNrOfRepetition" INT 0 255;
BA_DEF_ BO_ "GenMsgILSupport" ENUM "No","Yes";
BA_DEF_ BO_ "GenMsgStartDelayTime" INT 0 65535;
BA_DEF_ BO_ "GenMsgCycleTimeFast" INT 0 65535;
BA_DEF_ BO_ "GenMsgCycleTime" INT 0 65535;
BA_DEF_ BO_ "GenMsgDelayTime" INT 0 65535;
BA_DEF_ BO_ "NmAsrMessage" ENUM "No","Yes";
BA_DEF_ BO_ "DiagState" ENUM "No","Yes";
BA_DEF_ BO_ "DiagConnection" HEX 0 65535;
BA_DEF_ BO_ "VFrameFormat" ENUM "StandardCAN","ExtendedCAN","reserved","reserved","reserved","reserved","reserved","reserved","reserved","reserved","reserved","reserved","reserved","reserved","StandardCAN_FD","ExtendedCAN_FD";
BA_DEF_ BO_ "CANFD_BRS" ENUM "0","1";
BA_DEF_DEF_ "DiagRequest" "No";
BA_DEF_DEF_ "Type" "-";
BA_DEF_DEF_ "DiagResponse" "No";
BA_DEF_DEF_ "NmMessage" "No";
BA_DEF_DEF_ "GenMsgSendType" "NoMsgSendType";
BA_DEF_DEF_ "GenMsgNrOfRepetition" 0;
BA_DEF_DEF_ "GenMsgILSupport" "No";
BA_DEF_DEF_ "GenMsgStartDelayTime" 0;
BA_DEF_DEF_ "GenMsgCycleTimeFast" 0;
BA_DEF_DEF_ "GenMsgCycleTime" 0;
BA_DEF_DEF_ "GenMsgDelayTime" 0;
BA_DEF_DEF_ "NmAsrMessage" "No";
BA_DEF_DEF_ "DiagState" "No";
BA_DEF_DEF_ "DiagConnection" 0;
BA_DEF_DEF_ "VFrameFormat" "StandardCAN_FD";
BA_DEF_DEF_ "CANFD_BRS" "0";
BA_DEF_DEF_ "GenSigStartValue" 0;
BA_DEF_DEF_ "GenSigInactiveValue" 0;
BA_DEF_DEF_ "GenSigSendType" "NoSigSendType";
BA_DEF_DEF_ "SystemSignalLongSymbol" "";
BA_DEF_DEF_ "GenSigTimeoutTime_AGSM" 2500;
BA_DEF_DEF_ "GenSigTimeoutTime_BCM" 2500;
BA_DEF_DEF_ "GenSigTimeoutTime_BSM" 2500;
BA_DEF_DEF_ "GenSigTimeoutTime_CADM" 2500;
BA_DEF_DEF_ "GenSigTimeoutTime_DMSM" 2500;
BA_DEF_DEF_ "GenSigTimeoutTime_DTCM" 2500;
BA_DEF_DEF_ "GenSigTimeoutTime_ECM" 2500;
BA_DEF_DEF_ "GenSigTimeoutTime_EVCU2" 2500;
BA_DEF_DEF_ "GenSigTimeoutTime_GNMM" 2500;
BA_DEF_DEF_ "GenSigTimeoutTime_HCP" 2500;
BA_DEF_DEF_ "GenSigTimeoutTime_IPC" 2500;
BA_DEF_DEF_ "GenSigTimeoutTime_RFHM" 2500;
BA_DEF_DEF_ "GenSigTimeoutTime_SGW" 2500;
BA_DEF_DEF_ "GenSigTimeoutTime_TCM" 2500;
BA_ "Type" BO_ 258 1;
BA_ "GenMsgSendType" BO_ 258 0;
BA_ "GenMsgILSupport" BO_ 258 1;
BA_ "GenMsgCycleTime" BO_ 258 10;
BA_ "CANFD_BRS" BO_ 258 1;
BA_ "Type" BO_ 259 1;
BA_ "GenMsgSendType" BO_ 259 0;
BA_ "GenMsgILSupport" BO_ 259 1;
BA_ "GenMsgCycleTime" BO_ 259 10;
BA_ "CANFD_BRS" BO_ 259 1;
BA_ "Type" BO_ 609 3;
BA_ "GenMsgSendType" BO_ 609 0;
BA_ "GenMsgNrOfRepetition" BO_ 609 2;
BA_ "GenMsgILSupport" BO_ 609 1;
BA_ "GenMsgCycleTimeFast" BO_ 609 20;
BA_ "GenMsgCycleTime" BO_ 609 100;
BA_ "CANFD_BRS" BO_ 609 1;
BA_ "Type" BO_ 1155 3;
BA_ "GenMsgSendType" BO_ 1155 0;
BA_ "GenMsgNrOfRepetition" BO_ 1155 2;
BA_ "GenMsgILSupport" BO_ 1155 1;
BA_ "GenMsgCycleTimeFast" BO_ 1155 20;
BA_ "GenMsgCycleTime" BO_ 1155 500;
BA_ "GenMsgDelayTime" BO_ 1155 20;
BA_ "CANFD_BRS" BO_ 1155 1;
BA_ "Type" BO_ 205 1;
BA_ "GenMsgSendType" BO_ 205 0;
BA_ "GenMsgILSupport" BO_ 205 1;
BA_ "GenMsgCycleTime" BO_ 205 10;
BA_ "CANFD_BRS" BO_ 205 1;
BA_ "Type" BO_ 514 1;
BA_ "GenMsgSendType" BO_ 514 0;
BA_ "GenMsgILSupport" BO_ 514 1;
BA_ "GenMsgCycleTime" BO_ 514 20;
BA_ "CANFD_BRS" BO_ 514 1;
BA_ "Type" BO_ 257 1;
BA_ "GenMsgSendType" BO_ 257 0;
BA_ "GenMsgILSupport" BO_ 257 1;
BA_ "GenMsgCycleTime" BO_ 257 10;
BA_ "CANFD_BRS" BO_ 257 1;
BA_ "Type" BO_ 524 1;
BA_ "GenMsgSendType" BO_ 524 0;
BA_ "GenMsgILSupport" BO_ 524 1;
BA_ "GenMsgCycleTime" BO_ 524 20;
BA_ "CANFD_BRS" BO_ 524 1;
BA_ "Type" BO_ 2651930624 8;
BA_ "GenMsgILSupport" BO_ 2651930624 1;
BA_ "GenMsgDelayTime" BO_ 2651930624 10;
BA_ "VFrameFormat" BO_ 2651930624 15;
BA_ "CANFD_BRS" BO_ 2651930624 1;
BA_ "Type" BO_ 2651930646 11;
BA_ "GenMsgILSupport" BO_ 2651930646 1;
BA_ "VFrameFormat" BO_ 2651930646 15;
BA_ "CANFD_BRS" BO_ 2651930646 1;
BA_ "Type" BO_ 2651930694 11;
BA_ "GenMsgILSupport" BO_ 2651930694 1;
BA_ "VFrameFormat" BO_ 2651930694 15;
BA_ "CANFD_BRS" BO_ 2651930694 1;
BA_ "Type" BO_ 2651930630 11;
BA_ "GenMsgILSupport" BO_ 2651930630 1;
BA_ "VFrameFormat" BO_ 2651930630 15;
BA_ "CANFD_BRS" BO_ 2651930630 1;
BA_ "Type" BO_ 2651930765 11;
BA_ "GenMsgILSupport" BO_ 2651930765 1;
BA_ "VFrameFormat" BO_ 2651930765 15;
BA_ "CANFD_BRS" BO_ 2651930765 1;
BA_ "Type" BO_ 2651930776 11;
BA_ "GenMsgILSupport" BO_ 2651930776 1;
BA_ "VFrameFormat" BO_ 2651930776 15;
BA_ "CANFD_BRS" BO_ 2651930776 1;
BA_ "Type" BO_ 2651930691 11;
BA_ "GenMsgILSupport" BO_ 2651930691 1;
BA_ "VFrameFormat" BO_ 2651930691 15;
BA_ "CANFD_BRS" BO_ 2651930691 1;
BA_ "Type" BO_ 2651930625 11;
BA_ "GenMsgILSupport" BO_ 2651930625 1;
BA_ "VFrameFormat" BO_ 2651930625 15;
BA_ "CANFD_BRS" BO_ 2651930625 1;
BA_ "GenSigTimeoutTime_AGSM" SG_ 258 ABSActive 0;
BA_ "GenSigTimeoutTime_BSM" SG_ 258 ABSActive 0;
BA_ "GenSigTimeoutTime_CADM" SG_ 258 ABSActive 0;
BA_ "GenSigTimeoutTime_DMSM" SG_ 258 ABSActive 0;
BA_ "GenSigTimeoutTime_ECM" SG_ 258 ABSActive 0;
BA_ "GenSigTimeoutTime_GNMM" SG_ 258 ABSActive 0;
BA_ "GenSigTimeoutTime_IPC" SG_ 258 ABSActive 0;
BA_ "GenSigTimeoutTime_RFHM" SG_ 258 ABSActive 0;
BA_ "GenSigTimeoutTime_AGSM" SG_ 258 AHH_Ready_Status 0;
BA_ "GenSigTimeoutTime_BCM" SG_ 258 AHH_Ready_Status 0;
BA_ "GenSigTimeoutTime_BSM" SG_ 258 AHH_Ready_Status 0;
BA_ "GenSigTimeoutTime_CADM" SG_ 258 AHH_Ready_Status 0;
BA_ "GenSigTimeoutTime_DMSM" SG_ 258 AHH_Ready_Status 0;
BA_ "GenSigTimeoutTime_DTCM" SG_ 258 AHH_Ready_Status 0;
BA_ "GenSigTimeoutTime_ECM" SG_ 258 AHH_Ready_Status 0;
BA_ "GenSigTimeoutTime_GNMM" SG_ 258 AHH_Ready_Status 0;
BA_ "GenSigTimeoutTime_HCP" SG_ 258 AHH_Ready_Status 0;
BA_ "GenSigTimeoutTime_IPC" SG_ 258 AHH_Ready_Status 0;
BA_ "GenSigTimeoutTime_RFHM" SG_ 258 AHH_Ready_Status 0;
BA_ "GenSigTimeoutTime_SGW" SG_ 258 AHH_Ready_Status 0;
BA_ "GenSigTimeoutTime_TCM" SG_ 258 AHH_Ready_Status 0;
BA_ "GenSigTimeoutTime_AGSM" SG_ 258 Brake_MaxRegen_Ready 0;
BA_ "GenSigTimeoutTime_BCM" SG_ 258 Brake_MaxRegen_Ready 0;
BA_ "GenSigTimeoutTime_BSM" SG_ 258 Brake_MaxRegen_Ready 0;
BA_ "GenSigTimeoutTime_CADM" SG_ 258 Brake_MaxRegen_Ready 0;
BA_ "GenSigTimeoutTime_DMSM" SG_ 258 Brake_MaxRegen_Ready 0;
BA_ "GenSigTimeoutTime_DTCM" SG_ 258 Brake_MaxRegen_Ready 0;
BA_ "GenSigTimeoutTime_ECM" SG_ 258 Brake_MaxRegen_Ready 0;
BA_ "GenSigTimeoutTime_GNMM" SG_ 258 Brake_MaxRegen_Ready 0;
BA_ "GenSigTimeoutTime_HCP" SG_ 258 Brake_MaxRegen_Ready 0;
BA_ "GenSigTimeoutTime_IPC" SG_ 258 Brake_MaxRegen_Ready 0;
BA_ "GenSigTimeoutTime_RFHM" SG_ 258 Brake_MaxRegen_Ready 0;
BA_ "GenSigTimeoutTime_SGW" SG_ 258 Brake_MaxRegen_Ready 0;
BA_ "GenSigTimeoutTime_TCM" SG_ 258 Brake_MaxRegen_Ready 0;
BA_ "GenSigStartValue" SG_ 258 BrakeBoostPressure 2047;
BA_ "GenSigTimeoutTime_AGSM" SG_ 258 BrakeBoostPressure 0;
BA_ "GenSigTimeoutTime_BSM" SG_ 258 BrakeBoostPressure 0;
BA_ "GenSigTimeoutTime_CADM" SG_ 258 BrakeBoostPressure 0;
BA_ "GenSigTimeoutTime_DMSM" SG_ 258 BrakeBoostPressure 0;
BA_ "GenSigTimeoutTime_DTCM" SG_ 258 BrakeBoostPressure 0;
BA_ "GenSigTimeoutTime_GNMM" SG_ 258 BrakeBoostPressure 0;
BA_ "GenSigTimeoutTime_HCP" SG_ 258 BrakeBoostPressure 0;
BA_ "GenSigTimeoutTime_RFHM" SG_ 258 BrakeBoostPressure 0;
BA_ "GenSigTimeoutTime_AGSM" SG_ 258 BrakeBoostStat 0;
BA_ "GenSigTimeoutTime_BCM" SG_ 258 BrakeBoostStat 0;
BA_ "GenSigTimeoutTime_BSM" SG_ 258 BrakeBoostStat 0;
BA_ "GenSigTimeoutTime_CADM" SG_ 258 BrakeBoostStat 0;
BA_ "GenSigTimeoutTime_DMSM" SG_ 258 BrakeBoostStat 0;
BA_ "GenSigTimeoutTime_DTCM" SG_ 258 BrakeBoostStat 0;
BA_ "GenSigTimeoutTime_ECM" SG_ 258 BrakeBoostStat 0;
BA_ "GenSigTimeoutTime_GNMM" SG_ 258 BrakeBoostStat 0;
BA_ "GenSigTimeoutTime_HCP" SG_ 258 BrakeBoostStat 0;
BA_ "GenSigTimeoutTime_IPC" SG_ 258 BrakeBoostStat 0;
BA_ "GenSigTimeoutTime_RFHM" SG_ 258 BrakeBoostStat 0;
BA_ "GenSigTimeoutTime_TCM" SG_ 258 BrakeBoostStat 0;
BA_ "GenSigTimeoutTime_AGSM" SG_ 258 BrakeInterventionSts 0;
BA_ "GenSigTimeoutTime_BSM" SG_ 258 BrakeInterventionSts 0;
BA_ "GenSigTimeoutTime_CADM" SG_ 258 BrakeInterventionSts 0;
BA_ "GenSigTimeoutTime_DMSM" SG_ 258 BrakeInterventionSts 0;
BA_ "GenSigTimeoutTime_GNMM" SG_ 258 BrakeInterventionSts 0;
BA_ "GenSigTimeoutTime_IPC" SG_ 258 BrakeInterventionSts 0;
BA_ "GenSigTimeoutTime_RFHM" SG_ 258 BrakeInterventionSts 0;
BA_ "GenSigTimeoutTime_SGW" SG_ 258 BrakeInterventionSts 0;
BA_ "GenSigStartValue" SG_ 258 BrakePedalPressure 2047;
BA_ "GenSigTimeoutTime_AGSM" SG_ 258 BrakePedalPressure 0;
BA_ "GenSigTimeoutTime_BSM" SG_ 258 BrakePedalPressure 0;
BA_ "GenSigTimeoutTime_CADM" SG_ 258 BrakePedalPressure 0;
BA_ "GenSigTimeoutTime_DMSM" SG_ 258 BrakePedalPressure 0;
BA_ "GenSigTimeoutTime_DTCM" SG_ 258 BrakePedalPressure 0;
BA_ "GenSigTimeoutTime_GNMM" SG_ 258 BrakePedalPressure 0;
BA_ "GenSigTimeoutTime_HCP" SG_ 258 BrakePedalPressure 0;
BA_ "GenSigTimeoutTime_IPC" SG_ 258 BrakePedalPressure 0;
BA_ "GenSigTimeoutTime_RFHM" SG_ 258 BrakePedalPressure 0;
BA_ "GenSigTimeoutTime_AGSM" SG_ 258 Brk_Stat 0;
BA_ "GenSigTimeoutTime_BSM" SG_ 258 Brk_Stat 0;
BA_ "GenSigTimeoutTime_CADM" SG_ 258 Brk_Stat 0;
BA_ "GenSigTimeoutTime_DMSM" SG_ 258 Brk_Stat 0;
BA_ "GenSigTimeoutTime_DTCM" SG_ 258 Brk_Stat 0;
BA_ "GenSigTimeoutTime_EVCU2" SG_ 258 Brk_Stat 0;
BA_ "GenSigTimeoutTime_GNMM" SG_ 258 Brk_Stat 0;
BA_ "GenSigTimeoutTime_HCP" SG_ 258 Brk_Stat 0;
BA_ "GenSigTimeoutTime_RFHM" SG_ 258 Brk_Stat 0;
BA_ "GenSigTimeoutTime_TCM" SG_ 258 Brk_Stat 0;
BA_ "GenSigTimeoutTime_AGSM" SG_ 258 BSM_ESASystemSts 0;
BA_ "GenSigTimeoutTime_BSM" SG_ 258 BSM_ESASystemSts 0;
BA_ "GenSigTimeoutTime_CADM" SG_ 258 BSM_ESASystemSts 0;
BA_ "GenSigTimeoutTime_DMSM" SG_ 258 BSM_ESASystemSts 0;
BA_ "GenSigTimeoutTime_DTCM" SG_ 258 BSM_ESASystemSts 0;
BA_ "GenSigTimeoutTime_ECM" SG_ 258 BSM_ESASystemSts 0;
BA_ "GenSigTimeoutTime_EVCU2" SG_ 258 BSM_ESASystemSts 0;
BA_ "GenSigTimeoutTime_GNMM" SG_ 258 BSM_ESASystemSts 0;
BA_ "GenSigTimeoutTime_HCP" SG_ 258 BSM_ESASystemSts 0;
BA_ "GenSigTimeoutTime_IPC" SG_ 258 BSM_ESASystemSts 0;
BA_ "GenSigTimeoutTime_RFHM" SG_ 258 BSM_ESASystemSts 0;
BA_ "GenSigTimeoutTime_SGW" SG_ 258 BSM_ESASystemSts 0;
BA_ "GenSigTimeoutTime_TCM" SG_ 258 BSM_ESASystemSts 0;
BA_ "GenSigTimeoutTime_AGSM" SG_ 258 BSM_RequesterFunction 0;
BA_ "GenSigTimeoutTime_BCM" SG_ 258 BSM_RequesterFunction 0;
BA_ "GenSigTimeoutTime_BSM" SG_ 258 BSM_RequesterFunction 0;
BA_ "GenSigTimeoutTime_CADM" SG_ 258 BSM_RequesterFunction 0;
BA_ "GenSigTimeoutTime_DMSM" SG_ 258 BSM_RequesterFunction 0;
BA_ "GenSigTimeoutTime_DTCM" SG_ 258 BSM_RequesterFunction 0;
BA_ "GenSigTimeoutTime_ECM" SG_ 258 BSM_RequesterFunction 0;
BA_ "GenSigTimeoutTime_EVCU2" SG_ 258 BSM_RequesterFunction 0;
BA_ "GenSigTimeoutTime_GNMM" SG_ 258 BSM_RequesterFunction 0;
BA_ "GenSigTimeoutTime_HCP" SG_ 258 BSM_RequesterFunction 0;
BA_ "GenSigTimeoutTime_RFHM" SG_ 258 BSM_RequesterFunction 0;
BA_ "GenSigTimeoutTime_SGW" SG_ 258 BSM_RequesterFunction 0;
BA_ "GenSigTimeoutTime_TCM" SG_ 258 BSM_RequesterFunction 0;
BA_ "GenSigTimeoutTime_BSM" SG_ 258 CRC_BRAKE2 0;
BA_ "GenSigTimeoutTime_AGSM" SG_ 258 ESCActive 0;
BA_ "GenSigTimeoutTime_BSM" SG_ 258 ESCActive 0;
BA_ "GenSigTimeoutTime_CADM" SG_ 258 ESCActive 0;
BA_ "GenSigTimeoutTime_DMSM" SG_ 258 ESCActive 0;
BA_ "GenSigTimeoutTime_ECM" SG_ 258 ESCActive 0;
BA_ "GenSigTimeoutTime_GNMM" SG_ 258 ESCActive 0;
BA_ "GenSigTimeoutTime_HCP" SG_ 258 ESCActive 0;
BA_ "GenSigTimeoutTime_IPC" SG_ 258 ESCActive 0;
BA_ "GenSigTimeoutTime_RFHM" SG_ 258 ESCActive 0;
BA_ "GenSigStartValue" SG_ 258 ESP_Sys_Stat 1;
BA_ "GenSigTimeoutTime_AGSM" SG_ 258 ESP_Sys_Stat 0;
BA_ "GenSigTimeoutTime_BCM" SG_ 258 ESP_Sys_Stat 0;
BA_ "GenSigTimeoutTime_BSM" SG_ 258 ESP_Sys_Stat 0;
BA_ "GenSigTimeoutTime_CADM" SG_ 258 ESP_Sys_Stat 0;
BA_ "GenSigTimeoutTime_DMSM" SG_ 258 ESP_Sys_Stat 0;
BA_ "GenSigTimeoutTime_DTCM" SG_ 258 ESP_Sys_Stat 0;
BA_ "GenSigTimeoutTime_EVCU2" SG_ 258 ESP_Sys_Stat 0;
BA_ "GenSigTimeoutTime_GNMM" SG_ 258 ESP_Sys_Stat 0;
BA_ "GenSigTimeoutTime_IPC" SG_ 258 ESP_Sys_Stat 0;
BA_ "GenSigTimeoutTime_RFHM" SG_ 258 ESP_Sys_Stat 0;
BA_ "GenSigTimeoutTime_SGW" SG_ 258 ESP_Sys_Stat 0;
BA_ "GenSigTimeoutTime_AGSM" SG_ 258 HBAActive 0;
BA_ "GenSigTimeoutTime_BSM" SG_ 258 HBAActive 0;
BA_ "GenSigTimeoutTime_CADM" SG_ 258 HBAActive 0;
BA_ "GenSigTimeoutTime_DMSM" SG_ 258 HBAActive 0;
BA_ "GenSigTimeoutTime_DTCM" SG_ 258 HBAActive 0;
BA_ "GenSigTimeoutTime_ECM" SG_ 258 HBAActive 0;
BA_ "GenSigTimeoutTime_EVCU2" SG_ 258 HBAActive 0;
BA_ "GenSigTimeoutTime_GNMM" SG_ 258 HBAActive 0;
BA_ "GenSigTimeoutTime_HCP" SG_ 258 HBAActive 0;
BA_ "GenSigTimeoutTime_IPC" SG_ 258 HBAActive 0;
BA_ "GenSigTimeoutTime_RFHM" SG_ 258 HBAActive 0;
BA_ "GenSigTimeoutTime_SGW" SG_ 258 HBAActive 0;
BA_ "GenSigTimeoutTime_TCM" SG_ 258 HBAActive 0;
BA_ "GenSigTimeoutTime_AGSM" SG_ 258 HillHolderActive 0;
BA_ "GenSigTimeoutTime_BSM" SG_ 258 HillHolderActive 0;
BA_ "GenSigTimeoutTime_CADM" SG_ 258 HillHolderActive 0;
BA_ "GenSigTimeoutTime_DMSM" SG_ 258 HillHolderActive 0;
BA_ "GenSigTimeoutTime_DTCM" SG_ 258 HillHolderActive 0;
BA_ "GenSigTimeoutTime_ECM" SG_ 258 HillHolderActive 0;
BA_ "GenSigTimeoutTime_EVCU2" SG_ 258 HillHolderActive 0;
BA_ "GenSigTimeoutTime_GNMM" SG_ 258 HillHolderActive 0;
BA_ "GenSigTimeoutTime_HCP" SG_ 258 HillHolderActive 0;
BA_ "GenSigTimeoutTime_IPC" SG_ 258 HillHolderActive 0;
BA_ "GenSigTimeoutTime_RFHM" SG_ 258 HillHolderActive 0;
BA_ "GenSigTimeoutTime_SGW" SG_ 258 HillHolderActive 0;
BA_ "GenSigTimeoutTime_TCM" SG_ 258 HillHolderActive 0;
BA_ "GenSigTimeoutTime_AGSM" SG_ 258 ImpendingSkid 0;
BA_ "GenSigTimeoutTime_BCM" SG_ 258 ImpendingSkid 0;
BA_ "GenSigTimeoutTime_BSM" SG_ 258 ImpendingSkid 0;
BA_ "GenSigTimeoutTime_CADM" SG_ 258 ImpendingSkid 0;
BA_ "GenSigTimeoutTime_DMSM" SG_ 258 ImpendingSkid 0;
BA_ "GenSigTimeoutTime_DTCM" SG_ 258 ImpendingSkid 0;
BA_ "GenSigTimeoutTime_ECM" SG_ 258 ImpendingSkid 0;
BA_ "GenSigTimeoutTime_GNMM" SG_ 258 ImpendingSkid 0;
BA_ "GenSigTimeoutTime_HCP" SG_ 258 ImpendingSkid 0;
BA_ "GenSigTimeoutTime_IPC" SG_ 258 ImpendingSkid 0;
BA_ "GenSigTimeoutTime_RFHM" SG_ 258 ImpendingSkid 0;
BA_ "GenSigTimeoutTime_SGW" SG_ 258 ImpendingSkid 0;
BA_ "GenSigTimeoutTime_TCM" SG_ 258 ImpendingSkid 0;
BA_ "GenSigTimeoutTime_AGSM" SG_ 258 InternalError_BSM 0;
BA_ "GenSigTimeoutTime_BCM" SG_ 258 InternalError_BSM 0;
BA_ "GenSigTimeoutTime_BSM" SG_ 258 InternalError_BSM 0;
BA_ "GenSigTimeoutTime_CADM" SG_ 258 InternalError_BSM 0;
BA_ "GenSigTimeoutTime_DMSM" SG_ 258 InternalError_BSM 0;
BA_ "GenSigTimeoutTime_DTCM" SG_ 258 InternalError_BSM 0;
BA_ "GenSigTimeoutTime_ECM" SG_ 258 InternalError_BSM 0;
BA_ "GenSigTimeoutTime_EVCU2" SG_ 258 InternalError_BSM 0;
BA_ "GenSigTimeoutTime_GNMM" SG_ 258 InternalError_BSM 0;
BA_ "GenSigTimeoutTime_HCP" SG_ 258 InternalError_BSM 0;
BA_ "GenSigTimeoutTime_IPC" SG_ 258 InternalError_BSM 0;
BA_ "GenSigTimeoutTime_RFHM" SG_ 258 InternalError_BSM 0;
BA_ "GenSigTimeoutTime_SGW" SG_ 258 InternalError_BSM 0;
BA_ "GenSigTimeoutTime_TCM" SG_ 258 InternalError_BSM 0;
BA_ "GenSigStartValue" SG_ 258 LatAcceleration_BSM 4095;
BA_ "GenSigTimeoutTime_AGSM" SG_ 258 LatAcceleration_BSM 0;
BA_ "GenSigTimeoutTime_BSM" SG_ 258 LatAcceleration_BSM 0;
BA_ "GenSigTimeoutTime_DMSM" SG_ 258 LatAcceleration_BSM 0;
BA_ "GenSigTimeoutTime_GNMM" SG_ 258 LatAcceleration_BSM 0;
BA_ "GenSigTimeoutTime_RFHM" SG_ 258 LatAcceleration_BSM 0;
BA_ "GenSigTimeoutTime_AGSM" SG_ 258 LatAccelerationFailSts_BSM 0;
BA_ "GenSigTimeoutTime_BSM" SG_ 258 LatAccelerationFailSts_BSM 0;
BA_ "GenSigTimeoutTime_DMSM" SG_ 258 LatAccelerationFailSts_BSM 0;
BA_ "GenSigTimeoutTime_EVCU2" SG_ 258 LatAccelerationFailSts_BSM 0;
BA_ "GenSigTimeoutTime_GNMM" SG_ 258 LatAccelerationFailSts_BSM 0;
BA_ "GenSigTimeoutTime_RFHM" SG_ 258 LatAccelerationFailSts_BSM 0;
BA_ "GenSigTimeoutTime_TCM" SG_ 258 LatAccelerationFailSts_BSM 0;
BA_ "GenSigStartValue" SG_ 258 LongAcceleration_BSM 4095;
BA_ "GenSigTimeoutTime_AGSM" SG_ 258 LongAcceleration_BSM 0;
BA_ "GenSigTimeoutTime_BSM" SG_ 258 LongAcceleration_BSM 0;
BA_ "GenSigTimeoutTime_DMSM" SG_ 258 LongAcceleration_BSM 0;
BA_ "GenSigTimeoutTime_GNMM" SG_ 258 LongAcceleration_BSM 0;
BA_ "GenSigTimeoutTime_RFHM" SG_ 258 LongAcceleration_BSM 0;
BA_ "GenSigTimeoutTime_AGSM" SG_ 258 LongAccelerationFailSts_BSM 0;
BA_ "GenSigTimeoutTime_BSM" SG_ 258 LongAccelerationFailSts_BSM 0;
BA_ "GenSigTimeoutTime_DMSM" SG_ 258 LongAccelerationFailSts_BSM 0;
BA_ "GenSigTimeoutTime_GNMM" SG_ 258 LongAccelerationFailSts_BSM 0;
BA_ "GenSigTimeoutTime_RFHM" SG_ 258 LongAccelerationFailSts_BSM 0;
BA_ "GenSigTimeoutTime_TCM" SG_ 258 LongAccelerationFailSts_BSM 0;
BA_ "GenSigTimeoutTime_BSM" SG_ 258 MessageCounter_BRAKE2 0;
BA_ "GenSigStartValue" SG_ 258 MuSplit 3;
BA_ "GenSigTimeoutTime_AGSM" SG_ 258 MuSplit 0;
BA_ "GenSigTimeoutTime_BCM" SG_ 258 MuSplit 0;
BA_ "GenSigTimeoutTime_BSM" SG_ 258 MuSplit 0;
BA_ "GenSigTimeoutTime_CADM" SG_ 258 MuSplit 0;
BA_ "GenSigTimeoutTime_DMSM" SG_ 258 MuSplit 0;
BA_ "GenSigTimeoutTime_DTCM" SG_ 258 MuSplit 0;
BA_ "GenSigTimeoutTime_ECM" SG_ 258 MuSplit 0;
BA_ "GenSigTimeoutTime_EVCU2" SG_ 258 MuSplit 0;
BA_ "GenSigTimeoutTime_GNMM" SG_ 258 MuSplit 0;
BA_ "GenSigTimeoutTime_HCP" SG_ 258 MuSplit 0;
BA_ "GenSigTimeoutTime_IPC" SG_ 258 MuSplit 0;
BA_ "GenSigTimeoutTime_RFHM" SG_ 258 MuSplit 0;
BA_ "GenSigTimeoutTime_SGW" SG_ 258 MuSplit 0;
BA_ "GenSigTimeoutTime_TCM" SG_ 258 MuSplit 0;
BA_ "GenSigStartValue" SG_ 258 OverSteering 63;
BA_ "GenSigTimeoutTime_AGSM" SG_ 258 OverSteering 0;
BA_ "GenSigTimeoutTime_BCM" SG_ 258 OverSteering 0;
BA_ "GenSigTimeoutTime_BSM" SG_ 258 OverSteering 0;
BA_ "GenSigTimeoutTime_CADM" SG_ 258 OverSteering 0;
BA_ "GenSigTimeoutTime_DMSM" SG_ 258 OverSteering 0;
BA_ "GenSigTimeoutTime_ECM" SG_ 258 OverSteering 0;
BA_ "GenSigTimeoutTime_GNMM" SG_ 258 OverSteering 0;
BA_ "GenSigTimeoutTime_HCP" SG_ 258 OverSteering 0;
BA_ "GenSigTimeoutTime_IPC" SG_ 258 OverSteering 0;
BA_ "GenSigTimeoutTime_RFHM" SG_ 258 OverSteering 0;
BA_ "GenSigTimeoutTime_SGW" SG_ 258 OverSteering 0;
BA_ "GenSigTimeoutTime_TCM" SG_ 258 OverSteering 0;
BA_ "GenSigTimeoutTime_BCM" SG_ 258 ParkingGearShiftReq_BSM 0;
BA_ "GenSigTimeoutTime_BSM" SG_ 258 ParkingGearShiftReq_BSM 0;
BA_ "GenSigTimeoutTime_CADM" SG_ 258 ParkingGearShiftReq_BSM 0;
BA_ "GenSigTimeoutTime_DMSM" SG_ 258 ParkingGearShiftReq_BSM 0;
BA_ "GenSigTimeoutTime_DTCM" SG_ 258 ParkingGearShiftReq_BSM 0;
BA_ "GenSigTimeoutTime_ECM" SG_ 258 ParkingGearShiftReq_BSM 0;
BA_ "GenSigTimeoutTime_GNMM" SG_ 258 ParkingGearShiftReq_BSM 0;
BA_ "GenSigTimeoutTime_HCP" SG_ 258 ParkingGearShiftReq_BSM 0;
BA_ "GenSigTimeoutTime_IPC" SG_ 258 ParkingGearShiftReq_BSM 0;
BA_ "GenSigTimeoutTime_RFHM" SG_ 258 ParkingGearShiftReq_BSM 0;
BA_ "GenSigTimeoutTime_SGW" SG_ 258 ParkingGearShiftReq_BSM 0;
BA_ "GenSigTimeoutTime_AGSM" SG_ 258 PrefillActive 0;
BA_ "GenSigTimeoutTime_BCM" SG_ 258 PrefillActive 0;
BA_ "GenSigTimeoutTime_BSM" SG_ 258 PrefillActive 0;
BA_ "GenSigTimeoutTime_DMSM" SG_ 258 PrefillActive 0;
BA_ "GenSigTimeoutTime_DTCM" SG_ 258 PrefillActive 0;
BA_ "GenSigTimeoutTime_ECM" SG_ 258 PrefillActive 0;
BA_ "GenSigTimeoutTime_EVCU2" SG_ 258 PrefillActive 0;
BA_ "GenSigTimeoutTime_GNMM" SG_ 258 PrefillActive 0;
BA_ "GenSigTimeoutTime_HCP" SG_ 258 PrefillActive 0;
BA_ "GenSigTimeoutTime_IPC" SG_ 258 PrefillActive 0;
BA_ "GenSigTimeoutTime_RFHM" SG_ 258 PrefillActive 0;
BA_ "GenSigTimeoutTime_SGW" SG_ 258 PrefillActive 0;
BA_ "GenSigTimeoutTime_TCM" SG_ 258 PrefillActive 0;
BA_ "GenSigTimeoutTime_AGSM" SG_ 258 Slope 0;
BA_ "GenSigTimeoutTime_BCM" SG_ 258 Slope 0;
BA_ "GenSigTimeoutTime_BSM" SG_ 258 Slope 0;
BA_ "GenSigTimeoutTime_CADM" SG_ 258 Slope 0;
BA_ "GenSigTimeoutTime_DMSM" SG_ 258 Slope 0;
BA_ "GenSigTimeoutTime_ECM" SG_ 258 Slope 0;
BA_ "GenSigTimeoutTime_EVCU2" SG_ 258 Slope 0;
BA_ "GenSigTimeoutTime_GNMM" SG_ 258 Slope 0;
BA_ "GenSigTimeoutTime_HCP" SG_ 258 Slope 0;
BA_ "GenSigTimeoutTime_IPC" SG_ 258 Slope 0;
BA_ "GenSigTimeoutTime_RFHM" SG_ 258 Slope 0;
BA_ "GenSigTimeoutTime_SGW" SG_ 258 Slope 0;
BA_ "GenSigTimeoutTime_TCM" SG_ 258 Slope 0;
BA_ "GenSigStartValue" SG_ 258 UnderSteering 63;
BA_ "GenSigTimeoutTime_AGSM" SG_ 258 UnderSteering 0;
BA_ "GenSigTimeoutTime_BCM" SG_ 258 UnderSteering 0;
BA_ "GenSigTimeoutTime_BSM" SG_ 258 UnderSteering 0;
BA_ "GenSigTimeoutTime_CADM" SG_ 258 UnderSteering 0;
BA_ "GenSigTimeoutTime_DMSM" SG_ 258 UnderSteering 0;
BA_ "GenSigTimeoutTime_ECM" SG_ 258 UnderSteering 0;
BA_ "GenSigTimeoutTime_GNMM" SG_ 258 UnderSteering 0;
BA_ "GenSigTimeoutTime_HCP" SG_ 258 UnderSteering 0;
BA_ "GenSigTimeoutTime_IPC" SG_ 258 UnderSteering 0;
BA_ "GenSigTimeoutTime_RFHM" SG_ 258 UnderSteering 0;
BA_ "GenSigTimeoutTime_SGW" SG_ 258 UnderSteering 0;
BA_ "GenSigTimeoutTime_TCM" SG_ 258 UnderSteering 0;
BA_ "GenSigTimeoutTime_BSM" SG_ 258 VehicleSpeedVSOSig 0;
BA_ "GenSigStartValue" SG_ 258 WheelRPM_FL 65535;
BA_ "GenSigTimeoutTime_AGSM" SG_ 258 WheelRPM_FL 0;
BA_ "GenSigTimeoutTime_BSM" SG_ 258 WheelRPM_FL 0;
BA_ "GenSigTimeoutTime_CADM" SG_ 258 WheelRPM_FL 0;
BA_ "GenSigTimeoutTime_DMSM" SG_ 258 WheelRPM_FL 0;
BA_ "GenSigTimeoutTime_DTCM" SG_ 258 WheelRPM_FL 0;
BA_ "GenSigTimeoutTime_ECM" SG_ 258 WheelRPM_FL 0;
BA_ "GenSigTimeoutTime_GNMM" SG_ 258 WheelRPM_FL 0;
BA_ "GenSigTimeoutTime_HCP" SG_ 258 WheelRPM_FL 0;
BA_ "GenSigTimeoutTime_IPC" SG_ 258 WheelRPM_FL 0;
BA_ "GenSigTimeoutTime_RFHM" SG_ 258 WheelRPM_FL 0;
BA_ "GenSigTimeoutTime_SGW" SG_ 258 WheelRPM_FL 0;
BA_ "GenSigTimeoutTime_TCM" SG_ 258 WheelRPM_FL 0;
BA_ "GenSigStartValue" SG_ 258 WheelRPM_FR 65535;
BA_ "GenSigTimeoutTime_AGSM" SG_ 258 WheelRPM_FR 0;
BA_ "GenSigTimeoutTime_BSM" SG_ 258 WheelRPM_FR 0;
BA_ "GenSigTimeoutTime_CADM" SG_ 258 WheelRPM_FR 0;
BA_ "GenSigTimeoutTime_DMSM" SG_ 258 WheelRPM_FR 0;
BA_ "GenSigTimeoutTime_DTCM" SG_ 258 WheelRPM_FR 0;
BA_ "GenSigTimeoutTime_ECM" SG_ 258 WheelRPM_FR 0;
BA_ "GenSigTimeoutTime_GNMM" SG_ 258 WheelRPM_FR 0;
BA_ "GenSigTimeoutTime_HCP" SG_ 258 WheelRPM_FR 0;
BA_ "GenSigTimeoutTime_IPC" SG_ 258 WheelRPM_FR 0;
BA_ "GenSigTimeoutTime_RFHM" SG_ 258 WheelRPM_FR 0;
BA_ "GenSigTimeoutTime_SGW" SG_ 258 WheelRPM_FR 0;
BA_ "GenSigTimeoutTime_TCM" SG_ 258 WheelRPM_FR 0;
BA_ "GenSigStartValue" SG_ 258 YawRate_BSM 4095;
BA_ "GenSigTimeoutTime_AGSM" SG_ 258 YawRate_BSM 0;
BA_ "GenSigTimeoutTime_BSM" SG_ 258 YawRate_BSM 0;
BA_ "GenSigTimeoutTime_DMSM" SG_ 258 YawRate_BSM 0;
BA_ "GenSigTimeoutTime_ECM" SG_ 258 YawRate_BSM 0;
BA_ "GenSigTimeoutTime_EVCU2" SG_ 258 YawRate_BSM 0;
BA_ "GenSigTimeoutTime_GNMM" SG_ 258 YawRate_BSM 0;
BA_ "GenSigTimeoutTime_HCP" SG_ 258 YawRate_BSM 0;
BA_ "GenSigTimeoutTime_IPC" SG_ 258 YawRate_BSM 0;
BA_ "GenSigTimeoutTime_RFHM" SG_ 258 YawRate_BSM 0;
BA_ "GenSigTimeoutTime_TCM" SG_ 258 YawRate_BSM 0;
BA_ "GenSigTimeoutTime_AGSM" SG_ 258 YawRateFailSts_BSM 0;
BA_ "GenSigTimeoutTime_BSM" SG_ 258 YawRateFailSts_BSM 0;
BA_ "GenSigTimeoutTime_DMSM" SG_ 258 YawRateFailSts_BSM 0;
BA_ "GenSigTimeoutTime_ECM" SG_ 258 YawRateFailSts_BSM 0;
BA_ "GenSigTimeoutTime_EVCU2" SG_ 258 YawRateFailSts_BSM 0;
BA_ "GenSigTimeoutTime_GNMM" SG_ 258 YawRateFailSts_BSM 0;
BA_ "GenSigTimeoutTime_HCP" SG_ 258 YawRateFailSts_BSM 0;
BA_ "GenSigTimeoutTime_IPC" SG_ 258 YawRateFailSts_BSM 0;
BA_ "GenSigTimeoutTime_RFHM" SG_ 258 YawRateFailSts_BSM 0;
BA_ "GenSigTimeoutTime_TCM" SG_ 258 YawRateFailSts_BSM 0;
BA_ "GenSigTimeoutTime_AGSM" SG_ 259 CRC__BRAKE3 0;
BA_ "GenSigTimeoutTime_BSM" SG_ 259 CRC__BRAKE3 0;
BA_ "GenSigTimeoutTime_DMSM" SG_ 259 CRC__BRAKE3 0;
BA_ "GenSigTimeoutTime_IPC" SG_ 259 CRC__BRAKE3 0;
BA_ "GenSigTimeoutTime_RFHM" SG_ 259 CRC__BRAKE3 0;
BA_ "GenSigTimeoutTime_SGW" SG_ 259 CRC__BRAKE3 0;
BA_ "GenSigStartValue" SG_ 259 LatAccelerationOffset_BSM 255;
BA_ "GenSigTimeoutTime_AGSM" SG_ 259 LatAccelerationOffset_BSM 0;
BA_ "GenSigTimeoutTime_BCM" SG_ 259 LatAccelerationOffset_BSM 0;
BA_ "GenSigTimeoutTime_BSM" SG_ 259 LatAccelerationOffset_BSM 0;
BA_ "GenSigTimeoutTime_CADM" SG_ 259 LatAccelerationOffset_BSM 0;
BA_ "GenSigTimeoutTime_DMSM" SG_ 259 LatAccelerationOffset_BSM 0;
BA_ "GenSigTimeoutTime_DTCM" SG_ 259 LatAccelerationOffset_BSM 0;
BA_ "GenSigTimeoutTime_ECM" SG_ 259 LatAccelerationOffset_BSM 0;
BA_ "GenSigTimeoutTime_EVCU2" SG_ 259 LatAccelerationOffset_BSM 0;
BA_ "GenSigTimeoutTime_GNMM" SG_ 259 LatAccelerationOffset_BSM 0;
BA_ "GenSigTimeoutTime_HCP" SG_ 259 LatAccelerationOffset_BSM 0;
BA_ "GenSigTimeoutTime_IPC" SG_ 259 LatAccelerationOffset_BSM 0;
BA_ "GenSigTimeoutTime_RFHM" SG_ 259 LatAccelerationOffset_BSM 0;
BA_ "GenSigTimeoutTime_SGW" SG_ 259 LatAccelerationOffset_BSM 0;
BA_ "GenSigTimeoutTime_TCM" SG_ 259 LatAccelerationOffset_BSM 0;
BA_ "GenSigTimeoutTime_AGSM" SG_ 259 LHF_FastPulseCounter 0;
BA_ "GenSigTimeoutTime_BSM" SG_ 259 LHF_FastPulseCounter 0;
BA_ "GenSigTimeoutTime_DMSM" SG_ 259 LHF_FastPulseCounter 0;
BA_ "GenSigTimeoutTime_DTCM" SG_ 259 LHF_FastPulseCounter 0;
BA_ "GenSigTimeoutTime_HCP" SG_ 259 LHF_FastPulseCounter 0;
BA_ "GenSigTimeoutTime_IPC" SG_ 259 LHF_FastPulseCounter 0;
BA_ "GenSigTimeoutTime_TCM" SG_ 259 LHF_FastPulseCounter 0;
BA_ "GenSigTimeoutTime_AGSM" SG_ 259 LHF_Spin 0;
BA_ "GenSigTimeoutTime_BSM" SG_ 259 LHF_Spin 0;
BA_ "GenSigTimeoutTime_DMSM" SG_ 259 LHF_Spin 0;
BA_ "GenSigTimeoutTime_GNMM" SG_ 259 LHF_Spin 0;
BA_ "GenSigTimeoutTime_IPC" SG_ 259 LHF_Spin 0;
BA_ "GenSigTimeoutTime_RFHM" SG_ 259 LHF_Spin 0;
BA_ "GenSigTimeoutTime_AGSM" SG_ 259 LHF_WheelSensorFailSts 0;
BA_ "GenSigTimeoutTime_BSM" SG_ 259 LHF_WheelSensorFailSts 0;
BA_ "GenSigTimeoutTime_DMSM" SG_ 259 LHF_WheelSensorFailSts 0;
BA_ "GenSigTimeoutTime_GNMM" SG_ 259 LHF_WheelSensorFailSts 0;
BA_ "GenSigTimeoutTime_HCP" SG_ 259 LHF_WheelSensorFailSts 0;
BA_ "GenSigTimeoutTime_IPC" SG_ 259 LHF_WheelSensorFailSts 0;
BA_ "GenSigTimeoutTime_RFHM" SG_ 259 LHF_WheelSensorFailSts 0;
BA_ "GenSigTimeoutTime_TCM" SG_ 259 LHF_WheelSensorFailSts 0;
BA_ "GenSigTimeoutTime_AGSM" SG_ 259 LHFWheelSpeed 0;
BA_ "GenSigTimeoutTime_BSM" SG_ 259 LHFWheelSpeed 0;
BA_ "GenSigTimeoutTime_DMSM" SG_ 259 LHFWheelSpeed 0;
BA_ "GenSigTimeoutTime_IPC" SG_ 259 LHFWheelSpeed 0;
BA_ "GenSigTimeoutTime_RFHM" SG_ 259 LHFWheelSpeed 0;
BA_ "GenSigTimeoutTime_AGSM" SG_ 259 LHR_FastPulseCounter 0;
BA_ "GenSigTimeoutTime_BSM" SG_ 259 LHR_FastPulseCounter 0;
BA_ "GenSigTimeoutTime_DMSM" SG_ 259 LHR_FastPulseCounter 0;
BA_ "GenSigTimeoutTime_DTCM" SG_ 259 LHR_FastPulseCounter 0;
BA_ "GenSigTimeoutTime_HCP" SG_ 259 LHR_FastPulseCounter 0;
BA_ "GenSigTimeoutTime_IPC" SG_ 259 LHR_FastPulseCounter 0;
BA_ "GenSigTimeoutTime_TCM" SG_ 259 LHR_FastPulseCounter 0;
BA_ "GenSigTimeoutTime_AGSM" SG_ 259 LHR_Spin 0;
BA_ "GenSigTimeoutTime_BSM" SG_ 259 LHR_Spin 0;
BA_ "GenSigTimeoutTime_DMSM" SG_ 259 LHR_Spin 0;
BA_ "GenSigTimeoutTime_GNMM" SG_ 259 LHR_Spin 0;
BA_ "GenSigTimeoutTime_IPC" SG_ 259 LHR_Spin 0;
BA_ "GenSigTimeoutTime_RFHM" SG_ 259 LHR_Spin 0;
BA_ "GenSigTimeoutTime_AGSM" SG_ 259 LHR_WheelSensorFailSts 0;
BA_ "GenSigTimeoutTime_BSM" SG_ 259 LHR_WheelSensorFailSts 0;
BA_ "GenSigTimeoutTime_DMSM" SG_ 259 LHR_WheelSensorFailSts 0;
BA_ "GenSigTimeoutTime_GNMM" SG_ 259 LHR_WheelSensorFailSts 0;
BA_ "GenSigTimeoutTime_HCP" SG_ 259 LHR_WheelSensorFailSts 0;
BA_ "GenSigTimeoutTime_IPC" SG_ 259 LHR_WheelSensorFailSts 0;
BA_ "GenSigTimeoutTime_RFHM" SG_ 259 LHR_WheelSensorFailSts 0;
BA_ "GenSigTimeoutTime_TCM" SG_ 259 LHR_WheelSensorFailSts 0;
BA_ "GenSigTimeoutTime_AGSM" SG_ 259 LHRWheelSpeed 0;
BA_ "GenSigTimeoutTime_BSM" SG_ 259 LHRWheelSpeed 0;
BA_ "GenSigTimeoutTime_DMSM" SG_ 259 LHRWheelSpeed 0;
BA_ "GenSigTimeoutTime_IPC" SG_ 259 LHRWheelSpeed 0;
BA_ "GenSigTimeoutTime_RFHM" SG_ 259 LHRWheelSpeed 0;
BA_ "GenSigStartValue" SG_ 259 LongAccelerationOffset_BSM 255;
BA_ "GenSigTimeoutTime_AGSM" SG_ 259 LongAccelerationOffset_BSM 0;
BA_ "GenSigTimeoutTime_BCM" SG_ 259 LongAccelerationOffset_BSM 0;
BA_ "GenSigTimeoutTime_BSM" SG_ 259 LongAccelerationOffset_BSM 0;
BA_ "GenSigTimeoutTime_CADM" SG_ 259 LongAccelerationOffset_BSM 0;
BA_ "GenSigTimeoutTime_DMSM" SG_ 259 LongAccelerationOffset_BSM 0;
BA_ "GenSigTimeoutTime_DTCM" SG_ 259 LongAccelerationOffset_BSM 0;
BA_ "GenSigTimeoutTime_ECM" SG_ 259 LongAccelerationOffset_BSM 0;
BA_ "GenSigTimeoutTime_EVCU2" SG_ 259 LongAccelerationOffset_BSM 0;
BA_ "GenSigTimeoutTime_GNMM" SG_ 259 LongAccelerationOffset_BSM 0;
BA_ "GenSigTimeoutTime_HCP" SG_ 259 LongAccelerationOffset_BSM 0;
BA_ "GenSigTimeoutTime_IPC" SG_ 259 LongAccelerationOffset_BSM 0;
BA_ "GenSigTimeoutTime_RFHM" SG_ 259 LongAccelerationOffset_BSM 0;
BA_ "GenSigTimeoutTime_SGW" SG_ 259 LongAccelerationOffset_BSM 0;
BA_ "GenSigTimeoutTime_TCM" SG_ 259 LongAccelerationOffset_BSM 0;
BA_ "GenSigStartValue" SG_ 259 LwsAngleOffset_BSM 1023;
BA_ "GenSigTimeoutTime_AGSM" SG_ 259 LwsAngleOffset_BSM 0;
BA_ "GenSigTimeoutTime_BCM" SG_ 259 LwsAngleOffset_BSM 0;
BA_ "GenSigTimeoutTime_BSM" SG_ 259 LwsAngleOffset_BSM 0;
BA_ "GenSigTimeoutTime_CADM" SG_ 259 LwsAngleOffset_BSM 0;
BA_ "GenSigTimeoutTime_DMSM" SG_ 259 LwsAngleOffset_BSM 0;
BA_ "GenSigTimeoutTime_DTCM" SG_ 259 LwsAngleOffset_BSM 0;
BA_ "GenSigTimeoutTime_ECM" SG_ 259 LwsAngleOffset_BSM 0;
BA_ "GenSigTimeoutTime_EVCU2" SG_ 259 LwsAngleOffset_BSM 0;
BA_ "GenSigTimeoutTime_HCP" SG_ 259 LwsAngleOffset_BSM 0;
BA_ "GenSigTimeoutTime_IPC" SG_ 259 LwsAngleOffset_BSM 0;
BA_ "GenSigTimeoutTime_RFHM" SG_ 259 LwsAngleOffset_BSM 0;
BA_ "GenSigTimeoutTime_SGW" SG_ 259 LwsAngleOffset_BSM 0;
BA_ "GenSigTimeoutTime_TCM" SG_ 259 LwsAngleOffset_BSM 0;
BA_ "GenSigTimeoutTime_AGSM" SG_ 259 MessageCounter_BRAKE3 0;
BA_ "GenSigTimeoutTime_BSM" SG_ 259 MessageCounter_BRAKE3 0;
BA_ "GenSigTimeoutTime_DMSM" SG_ 259 MessageCounter_BRAKE3 0;
BA_ "GenSigTimeoutTime_IPC" SG_ 259 MessageCounter_BRAKE3 0;
BA_ "GenSigTimeoutTime_RFHM" SG_ 259 MessageCounter_BRAKE3 0;
BA_ "GenSigTimeoutTime_SGW" SG_ 259 MessageCounter_BRAKE3 0;
BA_ "GenSigTimeoutTime_AGSM" SG_ 259 RHF_FastPulseCounter 0;
BA_ "GenSigTimeoutTime_BSM" SG_ 259 RHF_FastPulseCounter 0;
BA_ "GenSigTimeoutTime_DMSM" SG_ 259 RHF_FastPulseCounter 0;
BA_ "GenSigTimeoutTime_DTCM" SG_ 259 RHF_FastPulseCounter 0;
BA_ "GenSigTimeoutTime_HCP" SG_ 259 RHF_FastPulseCounter 0;
BA_ "GenSigTimeoutTime_IPC" SG_ 259 RHF_FastPulseCounter 0;
BA_ "GenSigTimeoutTime_TCM" SG_ 259 RHF_FastPulseCounter 0;
BA_ "GenSigTimeoutTime_AGSM" SG_ 259 RHF_Spin 0;
BA_ "GenSigTimeoutTime_BSM" SG_ 259 RHF_Spin 0;
BA_ "GenSigTimeoutTime_DMSM" SG_ 259 RHF_Spin 0;
BA_ "GenSigTimeoutTime_GNMM" SG_ 259 RHF_Spin 0;
BA_ "GenSigTimeoutTime_IPC" SG_ 259 RHF_Spin 0;
BA_ "GenSigTimeoutTime_RFHM" SG_ 259 RHF_Spin 0;
BA_ "GenSigTimeoutTime_AGSM" SG_ 259 RHF_WheelSensorFailSts 0;
BA_ "GenSigTimeoutTime_BSM" SG_ 259 RHF_WheelSensorFailSts 0;
BA_ "GenSigTimeoutTime_DMSM" SG_ 259 RHF_WheelSensorFailSts 0;
BA_ "GenSigTimeoutTime_GNMM" SG_ 259 RHF_WheelSensorFailSts 0;
BA_ "GenSigTimeoutTime_HCP" SG_ 259 RHF_WheelSensorFailSts 0;
BA_ "GenSigTimeoutTime_IPC" SG_ 259 RHF_WheelSensorFailSts 0;
BA_ "GenSigTimeoutTime_RFHM" SG_ 259 RHF_WheelSensorFailSts 0;
BA_ "GenSigTimeoutTime_TCM" SG_ 259 RHF_WheelSensorFailSts 0;
BA_ "GenSigTimeoutTime_AGSM" SG_ 259 RHFWheelSpeed 0;
BA_ "GenSigTimeoutTime_BSM" SG_ 259 RHFWheelSpeed 0;
BA_ "GenSigTimeoutTime_DMSM" SG_ 259 RHFWheelSpeed 0;
BA_ "GenSigTimeoutTime_IPC" SG_ 259 RHFWheelSpeed 0;
BA_ "GenSigTimeoutTime_RFHM" SG_ 259 RHFWheelSpeed 0;
BA_ "GenSigTimeoutTime_AGSM" SG_ 259 RHR_FastPulseCounter 0;
BA_ "GenSigTimeoutTime_BSM" SG_ 259 RHR_FastPulseCounter 0;
BA_ "GenSigTimeoutTime_DMSM" SG_ 259 RHR_FastPulseCounter 0;
BA_ "GenSigTimeoutTime_DTCM" SG_ 259 RHR_FastPulseCounter 0;
BA_ "GenSigTimeoutTime_HCP" SG_ 259 RHR_FastPulseCounter 0;
BA_ "GenSigTimeoutTime_IPC" SG_ 259 RHR_FastPulseCounter 0;
BA_ "GenSigTimeoutTime_TCM" SG_ 259 RHR_FastPulseCounter 0;
BA_ "GenSigTimeoutTime_AGSM" SG_ 259 RHR_Spin 0;
BA_ "GenSigTimeoutTime_BSM" SG_ 259 RHR_Spin 0;
BA_ "GenSigTimeoutTime_DMSM" SG_ 259 RHR_Spin 0;
BA_ "GenSigTimeoutTime_GNMM" SG_ 259 RHR_Spin 0;
BA_ "GenSigTimeoutTime_IPC" SG_ 259 RHR_Spin 0;
BA_ "GenSigTimeoutTime_RFHM" SG_ 259 RHR_Spin 0;
BA_ "GenSigTimeoutTime_AGSM" SG_ 259 RHR_WheelSensorFailSts 0;
BA_ "GenSigTimeoutTime_BSM" SG_ 259 RHR_WheelSensorFailSts 0;
BA_ "GenSigTimeoutTime_DMSM" SG_ 259 RHR_WheelSensorFailSts 0;
BA_ "GenSigTimeoutTime_GNMM" SG_ 259 RHR_WheelSensorFailSts 0;
BA_ "GenSigTimeoutTime_HCP" SG_ 259 RHR_WheelSensorFailSts 0;
BA_ "GenSigTimeoutTime_IPC" SG_ 259 RHR_WheelSensorFailSts 0;
BA_ "GenSigTimeoutTime_RFHM" SG_ 259 RHR_WheelSensorFailSts 0;
BA_ "GenSigTimeoutTime_TCM" SG_ 259 RHR_WheelSensorFailSts 0;
BA_ "GenSigTimeoutTime_AGSM" SG_ 259 RHRWheelSpeed 0;
BA_ "GenSigTimeoutTime_BSM" SG_ 259 RHRWheelSpeed 0;
BA_ "GenSigTimeoutTime_DMSM" SG_ 259 RHRWheelSpeed 0;
BA_ "GenSigTimeoutTime_IPC" SG_ 259 RHRWheelSpeed 0;
BA_ "GenSigTimeoutTime_RFHM" SG_ 259 RHRWheelSpeed 0;
BA_ "GenSigSendType" SG_ 609 ASRActive 3;
BA_ "GenSigTimeoutTime_AGSM" SG_ 609 ASRActive 0;
BA_ "GenSigTimeoutTime_BSM" SG_ 609 ASRActive 0;
BA_ "GenSigTimeoutTime_CADM" SG_ 609 ASRActive 0;
BA_ "GenSigTimeoutTime_DMSM" SG_ 609 ASRActive 0;
BA_ "GenSigTimeoutTime_GNMM" SG_ 609 ASRActive 0;
BA_ "GenSigTimeoutTime_HCP" SG_ 609 ASRActive 0;
BA_ "GenSigTimeoutTime_IPC" SG_ 609 ASRActive 0;
BA_ "GenSigTimeoutTime_RFHM" SG_ 609 ASRActive 0;
BA_ "GenSigTimeoutTime_AGSM" SG_ 609 BSM_LnchAbrtSts 0;
BA_ "GenSigTimeoutTime_BCM" SG_ 609 BSM_LnchAbrtSts 0;
BA_ "GenSigTimeoutTime_BSM" SG_ 609 BSM_LnchAbrtSts 0;
BA_ "GenSigTimeoutTime_CADM" SG_ 609 BSM_LnchAbrtSts 0;
BA_ "GenSigTimeoutTime_DMSM" SG_ 609 BSM_LnchAbrtSts 0;
BA_ "GenSigTimeoutTime_DTCM" SG_ 609 BSM_LnchAbrtSts 0;
BA_ "GenSigTimeoutTime_EVCU2" SG_ 609 BSM_LnchAbrtSts 0;
BA_ "GenSigTimeoutTime_GNMM" SG_ 609 BSM_LnchAbrtSts 0;
BA_ "GenSigTimeoutTime_HCP" SG_ 609 BSM_LnchAbrtSts 0;
BA_ "GenSigTimeoutTime_RFHM" SG_ 609 BSM_LnchAbrtSts 0;
BA_ "GenSigTimeoutTime_SGW" SG_ 609 BSM_LnchAbrtSts 0;
BA_ "GenSigTimeoutTime_AGSM" SG_ 609 BSM_LnchCtrl_SftBtn_SelectSts 0;
BA_ "GenSigTimeoutTime_BCM" SG_ 609 BSM_LnchCtrl_SftBtn_SelectSts 0;
BA_ "GenSigTimeoutTime_BSM" SG_ 609 BSM_LnchCtrl_SftBtn_SelectSts 0;
BA_ "GenSigTimeoutTime_CADM" SG_ 609 BSM_LnchCtrl_SftBtn_SelectSts 0;
BA_ "GenSigTimeoutTime_DMSM" SG_ 609 BSM_LnchCtrl_SftBtn_SelectSts 0;
BA_ "GenSigTimeoutTime_DTCM" SG_ 609 BSM_LnchCtrl_SftBtn_SelectSts 0;
BA_ "GenSigTimeoutTime_ECM" SG_ 609 BSM_LnchCtrl_SftBtn_SelectSts 0;
BA_ "GenSigTimeoutTime_EVCU2" SG_ 609 BSM_LnchCtrl_SftBtn_SelectSts 0;
BA_ "GenSigTimeoutTime_GNMM" SG_ 609 BSM_LnchCtrl_SftBtn_SelectSts 0;
BA_ "GenSigTimeoutTime_HCP" SG_ 609 BSM_LnchCtrl_SftBtn_SelectSts 0;
BA_ "GenSigTimeoutTime_IPC" SG_ 609 BSM_LnchCtrl_SftBtn_SelectSts 0;
BA_ "GenSigTimeoutTime_RFHM" SG_ 609 BSM_LnchCtrl_SftBtn_SelectSts 0;
BA_ "GenSigTimeoutTime_TCM" SG_ 609 BSM_LnchCtrl_SftBtn_SelectSts 0;
BA_ "GenSigTimeoutTime_AGSM" SG_ 609 BSM_LnchMode 0;
BA_ "GenSigTimeoutTime_BSM" SG_ 609 BSM_LnchMode 0;
BA_ "GenSigTimeoutTime_CADM" SG_ 609 BSM_LnchMode 0;
BA_ "GenSigTimeoutTime_DMSM" SG_ 609 BSM_LnchMode 0;
BA_ "GenSigTimeoutTime_EVCU2" SG_ 609 BSM_LnchMode 0;
BA_ "GenSigTimeoutTime_GNMM" SG_ 609 BSM_LnchMode 0;
BA_ "GenSigTimeoutTime_HCP" SG_ 609 BSM_LnchMode 0;
BA_ "GenSigTimeoutTime_RFHM" SG_ 609 BSM_LnchMode 0;
BA_ "GenSigTimeoutTime_SGW" SG_ 609 BSM_LnchMode 0;
BA_ "GenSigTimeoutTime_AGSM" SG_ 609 ClampForce 0;
BA_ "GenSigTimeoutTime_BSM" SG_ 609 ClampForce 0;
BA_ "GenSigTimeoutTime_CADM" SG_ 609 ClampForce 0;
BA_ "GenSigTimeoutTime_DMSM" SG_ 609 ClampForce 0;
BA_ "GenSigTimeoutTime_DTCM" SG_ 609 ClampForce 0;
BA_ "GenSigTimeoutTime_ECM" SG_ 609 ClampForce 0;
BA_ "GenSigTimeoutTime_EVCU2" SG_ 609 ClampForce 0;
BA_ "GenSigTimeoutTime_GNMM" SG_ 609 ClampForce 0;
BA_ "GenSigTimeoutTime_HCP" SG_ 609 ClampForce 0;
BA_ "GenSigTimeoutTime_IPC" SG_ 609 ClampForce 0;
BA_ "GenSigTimeoutTime_RFHM" SG_ 609 ClampForce 0;
BA_ "GenSigTimeoutTime_TCM" SG_ 609 ClampForce 0;
BA_ "GenSigTimeoutTime_AGSM" SG_ 609 CODE_CLR_BSM 0;
BA_ "GenSigTimeoutTime_BCM" SG_ 609 CODE_CLR_BSM 0;
BA_ "GenSigTimeoutTime_BSM" SG_ 609 CODE_CLR_BSM 0;
BA_ "GenSigTimeoutTime_CADM" SG_ 609 CODE_CLR_BSM 0;
BA_ "GenSigTimeoutTime_DMSM" SG_ 609 CODE_CLR_BSM 0;
BA_ "GenSigTimeoutTime_DTCM" SG_ 609 CODE_CLR_BSM 0;
BA_ "GenSigTimeoutTime_EVCU2" SG_ 609 CODE_CLR_BSM 0;
BA_ "GenSigTimeoutTime_GNMM" SG_ 609 CODE_CLR_BSM 0;
BA_ "GenSigTimeoutTime_HCP" SG_ 609 CODE_CLR_BSM 0;
BA_ "GenSigTimeoutTime_IPC" SG_ 609 CODE_CLR_BSM 0;
BA_ "GenSigTimeoutTime_RFHM" SG_ 609 CODE_CLR_BSM 0;
BA_ "GenSigTimeoutTime_SGW" SG_ 609 CODE_CLR_BSM 0;
BA_ "GenSigTimeoutTime_TCM" SG_ 609 CODE_CLR_BSM 0;
BA_ "GenSigTimeoutTime_AGSM" SG_ 609 CRC_BRAKE4 0;
BA_ "GenSigTimeoutTime_BSM" SG_ 609 CRC_BRAKE4 0;
BA_ "GenSigTimeoutTime_DMSM" SG_ 609 CRC_BRAKE4 0;
BA_ "GenSigTimeoutTime_DTCM" SG_ 609 CRC_BRAKE4 0;
BA_ "GenSigTimeoutTime_GNMM" SG_ 609 CRC_BRAKE4 0;
BA_ "GenSigTimeoutTime_RFHM" SG_ 609 CRC_BRAKE4 0;
BA_ "GenSigTimeoutTime_SGW" SG_ 609 CRC_BRAKE4 0;
BA_ "GenSigTimeoutTime_AGSM" SG_ 609 EPB_HMI_Management 0;
BA_ "GenSigTimeoutTime_BCM" SG_ 609 EPB_HMI_Management 0;
BA_ "GenSigTimeoutTime_BSM" SG_ 609 EPB_HMI_Management 0;
BA_ "GenSigTimeoutTime_CADM" SG_ 609 EPB_HMI_Management 0;
BA_ "GenSigTimeoutTime_DMSM" SG_ 609 EPB_HMI_Management 0;
BA_ "GenSigTimeoutTime_DTCM" SG_ 609 EPB_HMI_Management 0;
BA_ "GenSigTimeoutTime_ECM" SG_ 609 EPB_HMI_Management 0;
BA_ "GenSigTimeoutTime_EVCU2" SG_ 609 EPB_HMI_Management 0;
BA_ "GenSigTimeoutTime_GNMM" SG_ 609 EPB_HMI_Management 0;
BA_ "GenSigTimeoutTime_HCP" SG_ 609 EPB_HMI_Management 0;
BA_ "GenSigTimeoutTime_RFHM" SG_ 609 EPB_HMI_Management 0;
BA_ "GenSigTimeoutTime_TCM" SG_ 609 EPB_HMI_Management 0;
BA_ "GenSigStartValue" SG_ 609 EPBAutoAppSts 1;
BA_ "GenSigTimeoutTime_AGSM" SG_ 609 EPBAutoAppSts 0;
BA_ "GenSigTimeoutTime_BCM" SG_ 609 EPBAutoAppSts 0;
BA_ "GenSigTimeoutTime_BSM" SG_ 609 EPBAutoAppSts 0;
BA_ "GenSigTimeoutTime_CADM" SG_ 609 EPBAutoAppSts 0;
BA_ "GenSigTimeoutTime_DMSM" SG_ 609 EPBAutoAppSts 0;
BA_ "GenSigTimeoutTime_DTCM" SG_ 609 EPBAutoAppSts 0;
BA_ "GenSigTimeoutTime_ECM" SG_ 609 EPBAutoAppSts 0;
BA_ "GenSigTimeoutTime_EVCU2" SG_ 609 EPBAutoAppSts 0;
BA_ "GenSigTimeoutTime_GNMM" SG_ 609 EPBAutoAppSts 0;
BA_ "GenSigTimeoutTime_HCP" SG_ 609 EPBAutoAppSts 0;
BA_ "GenSigTimeoutTime_IPC" SG_ 609 EPBAutoAppSts 0;
BA_ "GenSigTimeoutTime_RFHM" SG_ 609 EPBAutoAppSts 0;
BA_ "GenSigTimeoutTime_SGW" SG_ 609 EPBAutoAppSts 0;
BA_ "GenSigTimeoutTime_TCM" SG_ 609 EPBAutoAppSts 0;
BA_ "GenSigTimeoutTime_AGSM" SG_ 609 EPBMaintenanceSts 0;
BA_ "GenSigTimeoutTime_BCM" SG_ 609 EPBMaintenanceSts 0;
BA_ "GenSigTimeoutTime_BSM" SG_ 609 EPBMaintenanceSts 0;
BA_ "GenSigTimeoutTime_CADM" SG_ 609 EPBMaintenanceSts 0;
BA_ "GenSigTimeoutTime_DMSM" SG_ 609 EPBMaintenanceSts 0;
BA_ "GenSigTimeoutTime_DTCM" SG_ 609 EPBMaintenanceSts 0;
BA_ "GenSigTimeoutTime_ECM" SG_ 609 EPBMaintenanceSts 0;
BA_ "GenSigTimeoutTime_EVCU2" SG_ 609 EPBMaintenanceSts 0;
BA_ "GenSigTimeoutTime_GNMM" SG_ 609 EPBMaintenanceSts 0;
BA_ "GenSigTimeoutTime_HCP" SG_ 609 EPBMaintenanceSts 0;
BA_ "GenSigTimeoutTime_IPC" SG_ 609 EPBMaintenanceSts 0;
BA_ "GenSigTimeoutTime_RFHM" SG_ 609 EPBMaintenanceSts 0;
BA_ "GenSigTimeoutTime_TCM" SG_ 609 EPBMaintenanceSts 0;
BA_ "GenSigSendType" SG_ 609 EPBSts 3;
BA_ "GenSigTimeoutTime_AGSM" SG_ 609 EPBSts 0;
BA_ "GenSigTimeoutTime_BSM" SG_ 609 EPBSts 0;
BA_ "GenSigTimeoutTime_DMSM" SG_ 609 EPBSts 0;
BA_ "GenSigTimeoutTime_GNMM" SG_ 609 EPBSts 0;
BA_ "GenSigTimeoutTime_HCP" SG_ 609 EPBSts 0;
BA_ "GenSigTimeoutTime_RFHM" SG_ 609 EPBSts 0;
BA_ "GenSigTimeoutTime_AGSM" SG_ 609 EPBSwitchPosition 0;
BA_ "GenSigTimeoutTime_BSM" SG_ 609 EPBSwitchPosition 0;
BA_ "GenSigTimeoutTime_CADM" SG_ 609 EPBSwitchPosition 0;
BA_ "GenSigTimeoutTime_DMSM" SG_ 609 EPBSwitchPosition 0;
BA_ "GenSigTimeoutTime_DTCM" SG_ 609 EPBSwitchPosition 0;
BA_ "GenSigTimeoutTime_ECM" SG_ 609 EPBSwitchPosition 0;
BA_ "GenSigTimeoutTime_EVCU2" SG_ 609 EPBSwitchPosition 0;
BA_ "GenSigTimeoutTime_GNMM" SG_ 609 EPBSwitchPosition 0;
BA_ "GenSigTimeoutTime_HCP" SG_ 609 EPBSwitchPosition 0;
BA_ "GenSigTimeoutTime_IPC" SG_ 609 EPBSwitchPosition 0;
BA_ "GenSigTimeoutTime_RFHM" SG_ 609 EPBSwitchPosition 0;
BA_ "GenSigTimeoutTime_SGW" SG_ 609 EPBSwitchPosition 0;
BA_ "GenSigTimeoutTime_TCM" SG_ 609 EPBSwitchPosition 0;
BA_ "GenSigTimeoutTime_AGSM" SG_ 609 EPBWarningLampReq 0;
BA_ "GenSigTimeoutTime_BSM" SG_ 609 EPBWarningLampReq 0;
BA_ "GenSigTimeoutTime_CADM" SG_ 609 EPBWarningLampReq 0;
BA_ "GenSigTimeoutTime_DMSM" SG_ 609 EPBWarningLampReq 0;
BA_ "GenSigTimeoutTime_DTCM" SG_ 609 EPBWarningLampReq 0;
BA_ "GenSigTimeoutTime_ECM" SG_ 609 EPBWarningLampReq 0;
BA_ "GenSigTimeoutTime_EVCU2" SG_ 609 EPBWarningLampReq 0;
BA_ "GenSigTimeoutTime_GNMM" SG_ 609 EPBWarningLampReq 0;
BA_ "GenSigTimeoutTime_HCP" SG_ 609 EPBWarningLampReq 0;
BA_ "GenSigTimeoutTime_RFHM" SG_ 609 EPBWarningLampReq 0;
BA_ "GenSigTimeoutTime_TCM" SG_ 609 EPBWarningLampReq 0;
BA_ "GenSigTimeoutTime_AGSM" SG_ 609 ESC_OFF_Hrd_Sft_Button_sts 0;
BA_ "GenSigTimeoutTime_BSM" SG_ 609 ESC_OFF_Hrd_Sft_Button_sts 0;
BA_ "GenSigTimeoutTime_CADM" SG_ 609 ESC_OFF_Hrd_Sft_Button_sts 0;
BA_ "GenSigTimeoutTime_DMSM" SG_ 609 ESC_OFF_Hrd_Sft_Button_sts 0;
BA_ "GenSigTimeoutTime_DTCM" SG_ 609 ESC_OFF_Hrd_Sft_Button_sts 0;
BA_ "GenSigTimeoutTime_ECM" SG_ 609 ESC_OFF_Hrd_Sft_Button_sts 0;
BA_ "GenSigTimeoutTime_EVCU2" SG_ 609 ESC_OFF_Hrd_Sft_Button_sts 0;
BA_ "GenSigTimeoutTime_GNMM" SG_ 609 ESC_OFF_Hrd_Sft_Button_sts 0;
BA_ "GenSigTimeoutTime_HCP" SG_ 609 ESC_OFF_Hrd_Sft_Button_sts 0;
BA_ "GenSigTimeoutTime_IPC" SG_ 609 ESC_OFF_Hrd_Sft_Button_sts 0;
BA_ "GenSigTimeoutTime_RFHM" SG_ 609 ESC_OFF_Hrd_Sft_Button_sts 0;
BA_ "GenSigTimeoutTime_TCM" SG_ 609 ESC_OFF_Hrd_Sft_Button_sts 0;
BA_ "GenSigTimeoutTime_AGSM" SG_ 609 ESCSysEmsMlfAtv 0;
BA_ "GenSigTimeoutTime_BCM" SG_ 609 ESCSysEmsMlfAtv 0;
BA_ "GenSigTimeoutTime_BSM" SG_ 609 ESCSysEmsMlfAtv 0;
BA_ "GenSigTimeoutTime_CADM" SG_ 609 ESCSysEmsMlfAtv 0;
BA_ "GenSigTimeoutTime_DMSM" SG_ 609 ESCSysEmsMlfAtv 0;
BA_ "GenSigTimeoutTime_DTCM" SG_ 609 ESCSysEmsMlfAtv 0;
BA_ "GenSigTimeoutTime_ECM" SG_ 609 ESCSysEmsMlfAtv 0;
BA_ "GenSigTimeoutTime_EVCU2" SG_ 609 ESCSysEmsMlfAtv 0;
BA_ "GenSigTimeoutTime_GNMM" SG_ 609 ESCSysEmsMlfAtv 0;
BA_ "GenSigTimeoutTime_HCP" SG_ 609 ESCSysEmsMlfAtv 0;
BA_ "GenSigTimeoutTime_IPC" SG_ 609 ESCSysEmsMlfAtv 0;
BA_ "GenSigTimeoutTime_RFHM" SG_ 609 ESCSysEmsMlfAtv 0;
BA_ "GenSigTimeoutTime_SGW" SG_ 609 ESCSysEmsMlfAtv 0;
BA_ "GenSigTimeoutTime_TCM" SG_ 609 ESCSysEmsMlfAtv 0;
BA_ "GenSigTimeoutTime_AGSM" SG_ 609 LaunchRPMsetting_BSM 0;
BA_ "GenSigTimeoutTime_BCM" SG_ 609 LaunchRPMsetting_BSM 0;
BA_ "GenSigTimeoutTime_BSM" SG_ 609 LaunchRPMsetting_BSM 0;
BA_ "GenSigTimeoutTime_CADM" SG_ 609 LaunchRPMsetting_BSM 0;
BA_ "GenSigTimeoutTime_DMSM" SG_ 609 LaunchRPMsetting_BSM 0;
BA_ "GenSigTimeoutTime_DTCM" SG_ 609 LaunchRPMsetting_BSM 0;
BA_ "GenSigTimeoutTime_ECM" SG_ 609 LaunchRPMsetting_BSM 0;
BA_ "GenSigTimeoutTime_EVCU2" SG_ 609 LaunchRPMsetting_BSM 0;
BA_ "GenSigTimeoutTime_GNMM" SG_ 609 LaunchRPMsetting_BSM 0;
BA_ "GenSigTimeoutTime_HCP" SG_ 609 LaunchRPMsetting_BSM 0;
BA_ "GenSigTimeoutTime_IPC" SG_ 609 LaunchRPMsetting_BSM 0;
BA_ "GenSigTimeoutTime_RFHM" SG_ 609 LaunchRPMsetting_BSM 0;
BA_ "GenSigTimeoutTime_TCM" SG_ 609 LaunchRPMsetting_BSM 0;
BA_ "GenSigTimeoutTime_AGSM" SG_ 609 LnchCtrl_DisPopupSts 0;
BA_ "GenSigTimeoutTime_BCM" SG_ 609 LnchCtrl_DisPopupSts 0;
BA_ "GenSigTimeoutTime_BSM" SG_ 609 LnchCtrl_DisPopupSts 0;
BA_ "GenSigTimeoutTime_CADM" SG_ 609 LnchCtrl_DisPopupSts 0;
BA_ "GenSigTimeoutTime_DMSM" SG_ 609 LnchCtrl_DisPopupSts 0;
BA_ "GenSigTimeoutTime_DTCM" SG_ 609 LnchCtrl_DisPopupSts 0;
BA_ "GenSigTimeoutTime_ECM" SG_ 609 LnchCtrl_DisPopupSts 0;
BA_ "GenSigTimeoutTime_EVCU2" SG_ 609 LnchCtrl_DisPopupSts 0;
BA_ "GenSigTimeoutTime_GNMM" SG_ 609 LnchCtrl_DisPopupSts 0;
BA_ "GenSigTimeoutTime_HCP" SG_ 609 LnchCtrl_DisPopupSts 0;
BA_ "GenSigTimeoutTime_RFHM" SG_ 609 LnchCtrl_DisPopupSts 0;
BA_ "GenSigTimeoutTime_SGW" SG_ 609 LnchCtrl_DisPopupSts 0;
BA_ "GenSigTimeoutTime_TCM" SG_ 609 LnchCtrl_DisPopupSts 0;
BA_ "GenSigTimeoutTime_AGSM" SG_ 609 MessageCounter_BRAKE4 0;
BA_ "GenSigTimeoutTime_BSM" SG_ 609 MessageCounter_BRAKE4 0;
BA_ "GenSigTimeoutTime_DMSM" SG_ 609 MessageCounter_BRAKE4 0;
BA_ "GenSigTimeoutTime_DTCM" SG_ 609 MessageCounter_BRAKE4 0;
BA_ "GenSigTimeoutTime_GNMM" SG_ 609 MessageCounter_BRAKE4 0;
BA_ "GenSigTimeoutTime_RFHM" SG_ 609 MessageCounter_BRAKE4 0;
BA_ "GenSigTimeoutTime_SGW" SG_ 609 MessageCounter_BRAKE4 0;
BA_ "GenSigSendType" SG_ 609 MIL_OnRq_BSM 3;
BA_ "GenSigTimeoutTime_AGSM" SG_ 609 MIL_OnRq_BSM 0;
BA_ "GenSigTimeoutTime_BCM" SG_ 609 MIL_OnRq_BSM 0;
BA_ "GenSigTimeoutTime_BSM" SG_ 609 MIL_OnRq_BSM 0;
BA_ "GenSigTimeoutTime_CADM" SG_ 609 MIL_OnRq_BSM 0;
BA_ "GenSigTimeoutTime_DMSM" SG_ 609 MIL_OnRq_BSM 0;
BA_ "GenSigTimeoutTime_DTCM" SG_ 609 MIL_OnRq_BSM 0;
BA_ "GenSigTimeoutTime_EVCU2" SG_ 609 MIL_OnRq_BSM 0;
BA_ "GenSigTimeoutTime_GNMM" SG_ 609 MIL_OnRq_BSM 0;
BA_ "GenSigTimeoutTime_HCP" SG_ 609 MIL_OnRq_BSM 0;
BA_ "GenSigTimeoutTime_IPC" SG_ 609 MIL_OnRq_BSM 0;
BA_ "GenSigTimeoutTime_RFHM" SG_ 609 MIL_OnRq_BSM 0;
BA_ "GenSigTimeoutTime_TCM" SG_ 609 MIL_OnRq_BSM 0;
BA_ "GenSigSendType" SG_ 609 MSRActive 3;
BA_ "GenSigTimeoutTime_AGSM" SG_ 609 MSRActive 0;
BA_ "GenSigTimeoutTime_BSM" SG_ 609 MSRActive 0;
BA_ "GenSigTimeoutTime_CADM" SG_ 609 MSRActive 0;
BA_ "GenSigTimeoutTime_DMSM" SG_ 609 MSRActive 0;
BA_ "GenSigTimeoutTime_DTCM" SG_ 609 MSRActive 0;
BA_ "GenSigTimeoutTime_ECM" SG_ 609 MSRActive 0;
BA_ "GenSigTimeoutTime_GNMM" SG_ 609 MSRActive 0;
BA_ "GenSigTimeoutTime_HCP" SG_ 609 MSRActive 0;
BA_ "GenSigTimeoutTime_IPC" SG_ 609 MSRActive 0;
BA_ "GenSigTimeoutTime_RFHM" SG_ 609 MSRActive 0;
BA_ "GenSigTimeoutTime_SGW" SG_ 609 MSRActive 0;
BA_ "GenSigTimeoutTime_TCM" SG_ 609 MSRActive 0;
BA_ "GenSigTimeoutTime_AGSM" SG_ 609 RedLampReq 0;
BA_ "GenSigTimeoutTime_BCM" SG_ 609 RedLampReq 0;
BA_ "GenSigTimeoutTime_BSM" SG_ 609 RedLampReq 0;
BA_ "GenSigTimeoutTime_CADM" SG_ 609 RedLampReq 0;
BA_ "GenSigTimeoutTime_DMSM" SG_ 609 RedLampReq 0;
BA_ "GenSigTimeoutTime_DTCM" SG_ 609 RedLampReq 0;
BA_ "GenSigTimeoutTime_ECM" SG_ 609 RedLampReq 0;
BA_ "GenSigTimeoutTime_EVCU2" SG_ 609 RedLampReq 0;
BA_ "GenSigTimeoutTime_GNMM" SG_ 609 RedLampReq 0;
BA_ "GenSigTimeoutTime_HCP" SG_ 609 RedLampReq 0;
BA_ "GenSigTimeoutTime_RFHM" SG_ 609 RedLampReq 0;
BA_ "GenSigTimeoutTime_SGW" SG_ 609 RedLampReq 0;
BA_ "GenSigTimeoutTime_TCM" SG_ 609 RedLampReq 0;
BA_ "GenSigTimeoutTime_AGSM" SG_ 609 REPRGD_PFC_CLR_BSM 0;
BA_ "GenSigTimeoutTime_BCM" SG_ 609 REPRGD_PFC_CLR_BSM 0;
BA_ "GenSigTimeoutTime_BSM" SG_ 609 REPRGD_PFC_CLR_BSM 0;
BA_ "GenSigTimeoutTime_CADM" SG_ 609 REPRGD_PFC_CLR_BSM 0;
BA_ "GenSigTimeoutTime_DMSM" SG_ 609 REPRGD_PFC_CLR_BSM 0;
BA_ "GenSigTimeoutTime_DTCM" SG_ 609 REPRGD_PFC_CLR_BSM 0;
BA_ "GenSigTimeoutTime_EVCU2" SG_ 609 REPRGD_PFC_CLR_BSM 0;
BA_ "GenSigTimeoutTime_GNMM" SG_ 609 REPRGD_PFC_CLR_BSM 0;
BA_ "GenSigTimeoutTime_HCP" SG_ 609 REPRGD_PFC_CLR_BSM 0;
BA_ "GenSigTimeoutTime_IPC" SG_ 609 REPRGD_PFC_CLR_BSM 0;
BA_ "GenSigTimeoutTime_RFHM" SG_ 609 REPRGD_PFC_CLR_BSM 0;
BA_ "GenSigTimeoutTime_SGW" SG_ 609 REPRGD_PFC_CLR_BSM 0;
BA_ "GenSigTimeoutTime_TCM" SG_ 609 REPRGD_PFC_CLR_BSM 0;
BA_ "GenSigTimeoutTime_AGSM" SG_ 609 TravelDistance 0;
BA_ "GenSigTimeoutTime_BCM" SG_ 609 TravelDistance 0;
BA_ "GenSigTimeoutTime_BSM" SG_ 609 TravelDistance 0;
BA_ "GenSigTimeoutTime_CADM" SG_ 609 TravelDistance 0;
BA_ "GenSigTimeoutTime_DMSM" SG_ 609 TravelDistance 0;
BA_ "GenSigTimeoutTime_DTCM" SG_ 609 TravelDistance 0;
BA_ "GenSigTimeoutTime_GNMM" SG_ 609 TravelDistance 0;
BA_ "GenSigTimeoutTime_HCP" SG_ 609 TravelDistance 0;
BA_ "GenSigTimeoutTime_RFHM" SG_ 609 TravelDistance 0;
BA_ "GenSigTimeoutTime_TCM" SG_ 609 TravelDistance 0;
BA_ "GenSigSendType" SG_ 1155 ABSFailSts 3;
BA_ "GenSigTimeoutTime_AGSM" SG_ 1155 ABSFailSts 0;
BA_ "GenSigTimeoutTime_BSM" SG_ 1155 ABSFailSts 0;
BA_ "GenSigTimeoutTime_CADM" SG_ 1155 ABSFailSts 0;
BA_ "GenSigTimeoutTime_DMSM" SG_ 1155 ABSFailSts 0;
BA_ "GenSigTimeoutTime_DTCM" SG_ 1155 ABSFailSts 0;
BA_ "GenSigTimeoutTime_GNMM" SG_ 1155 ABSFailSts 0;
BA_ "GenSigTimeoutTime_HCP" SG_ 1155 ABSFailSts 0;
BA_ "GenSigTimeoutTime_RFHM" SG_ 1155 ABSFailSts 0;
BA_ "GenSigTimeoutTime_TCM" SG_ 1155 ABSFailSts 0;
BA_ "GenSigSendType" SG_ 1155 ACCEngaged 3;
BA_ "GenSigTimeoutTime_AGSM" SG_ 1155 ACCEngaged 0;
BA_ "GenSigTimeoutTime_BCM" SG_ 1155 ACCEngaged 0;
BA_ "GenSigTimeoutTime_BSM" SG_ 1155 ACCEngaged 0;
BA_ "GenSigTimeoutTime_CADM" SG_ 1155 ACCEngaged 0;
BA_ "GenSigTimeoutTime_DMSM" SG_ 1155 ACCEngaged 0;
BA_ "GenSigTimeoutTime_GNMM" SG_ 1155 ACCEngaged 0;
BA_ "GenSigTimeoutTime_HCP" SG_ 1155 ACCEngaged 0;
BA_ "GenSigTimeoutTime_IPC" SG_ 1155 ACCEngaged 0;
BA_ "GenSigTimeoutTime_RFHM" SG_ 1155 ACCEngaged 0;
BA_ "GenSigSendType" SG_ 1155 BSM_THA_Brk_Resp 4;
BA_ "GenSigTimeoutTime_AGSM" SG_ 1155 BSM_THA_Brk_Resp 0;
BA_ "GenSigTimeoutTime_BSM" SG_ 1155 BSM_THA_Brk_Resp 0;
BA_ "GenSigTimeoutTime_CADM" SG_ 1155 BSM_THA_Brk_Resp 0;
BA_ "GenSigTimeoutTime_DMSM" SG_ 1155 BSM_THA_Brk_Resp 0;
BA_ "GenSigTimeoutTime_DTCM" SG_ 1155 BSM_THA_Brk_Resp 0;
BA_ "GenSigTimeoutTime_ECM" SG_ 1155 BSM_THA_Brk_Resp 0;
BA_ "GenSigTimeoutTime_EVCU2" SG_ 1155 BSM_THA_Brk_Resp 0;
BA_ "GenSigTimeoutTime_GNMM" SG_ 1155 BSM_THA_Brk_Resp 0;
BA_ "GenSigTimeoutTime_HCP" SG_ 1155 BSM_THA_Brk_Resp 0;
BA_ "GenSigTimeoutTime_IPC" SG_ 1155 BSM_THA_Brk_Resp 0;
BA_ "GenSigTimeoutTime_RFHM" SG_ 1155 BSM_THA_Brk_Resp 0;
BA_ "GenSigTimeoutTime_SGW" SG_ 1155 BSM_THA_Brk_Resp 0;
BA_ "GenSigTimeoutTime_TCM" SG_ 1155 BSM_THA_Brk_Resp 0;
BA_ "GenSigSendType" SG_ 1155 BSMSysSts 3;
BA_ "GenSigTimeoutTime_AGSM" SG_ 1155 BSMSysSts 0;
BA_ "GenSigTimeoutTime_BCM" SG_ 1155 BSMSysSts 0;
BA_ "GenSigTimeoutTime_BSM" SG_ 1155 BSMSysSts 0;
BA_ "GenSigTimeoutTime_CADM" SG_ 1155 BSMSysSts 0;
BA_ "GenSigTimeoutTime_DMSM" SG_ 1155 BSMSysSts 0;
BA_ "GenSigTimeoutTime_DTCM" SG_ 1155 BSMSysSts 0;
BA_ "GenSigTimeoutTime_ECM" SG_ 1155 BSMSysSts 0;
BA_ "GenSigTimeoutTime_EVCU2" SG_ 1155 BSMSysSts 0;
BA_ "GenSigTimeoutTime_GNMM" SG_ 1155 BSMSysSts 0;
BA_ "GenSigTimeoutTime_HCP" SG_ 1155 BSMSysSts 0;
BA_ "GenSigTimeoutTime_IPC" SG_ 1155 BSMSysSts 0;
BA_ "GenSigTimeoutTime_RFHM" SG_ 1155 BSMSysSts 0;
BA_ "GenSigTimeoutTime_TCM" SG_ 1155 BSMSysSts 0;
BA_ "GenSigSendType" SG_ 1155 CMMIntervention 3;
BA_ "GenSigTimeoutTime_AGSM" SG_ 1155 CMMIntervention 0;
BA_ "GenSigTimeoutTime_BCM" SG_ 1155 CMMIntervention 0;
BA_ "GenSigTimeoutTime_BSM" SG_ 1155 CMMIntervention 0;
BA_ "GenSigTimeoutTime_CADM" SG_ 1155 CMMIntervention 0;
BA_ "GenSigTimeoutTime_DMSM" SG_ 1155 CMMIntervention 0;
BA_ "GenSigTimeoutTime_DTCM" SG_ 1155 CMMIntervention 0;
BA_ "GenSigTimeoutTime_ECM" SG_ 1155 CMMIntervention 0;
BA_ "GenSigTimeoutTime_EVCU2" SG_ 1155 CMMIntervention 0;
BA_ "GenSigTimeoutTime_GNMM" SG_ 1155 CMMIntervention 0;
BA_ "GenSigTimeoutTime_HCP" SG_ 1155 CMMIntervention 0;
BA_ "GenSigTimeoutTime_IPC" SG_ 1155 CMMIntervention 0;
BA_ "GenSigTimeoutTime_RFHM" SG_ 1155 CMMIntervention 0;
BA_ "GenSigTimeoutTime_SGW" SG_ 1155 CMMIntervention 0;
BA_ "GenSigTimeoutTime_TCM" SG_ 1155 CMMIntervention 0;
BA_ "GenSigTimeoutTime_AGSM" SG_ 1155 CRC_BRAKE5 0;
BA_ "GenSigTimeoutTime_BSM" SG_ 1155 CRC_BRAKE5 0;
BA_ "GenSigTimeoutTime_CADM" SG_ 1155 CRC_BRAKE5 0;
BA_ "GenSigTimeoutTime_DMSM" SG_ 1155 CRC_BRAKE5 0;
BA_ "GenSigTimeoutTime_GNMM" SG_ 1155 CRC_BRAKE5 0;
BA_ "GenSigTimeoutTime_HCP" SG_ 1155 CRC_BRAKE5 0;
BA_ "GenSigTimeoutTime_RFHM" SG_ 1155 CRC_BRAKE5 0;
BA_ "GenSigTimeoutTime_SGW" SG_ 1155 CRC_BRAKE5 0;
BA_ "GenSigSendType" SG_ 1155 EBDFailSts 3;
BA_ "GenSigTimeoutTime_AGSM" SG_ 1155 EBDFailSts 0;
BA_ "GenSigTimeoutTime_BSM" SG_ 1155 EBDFailSts 0;
BA_ "GenSigTimeoutTime_CADM" SG_ 1155 EBDFailSts 0;
BA_ "GenSigTimeoutTime_DMSM" SG_ 1155 EBDFailSts 0;
BA_ "GenSigTimeoutTime_DTCM" SG_ 1155 EBDFailSts 0;
BA_ "GenSigTimeoutTime_ECM" SG_ 1155 EBDFailSts 0;
BA_ "GenSigTimeoutTime_EVCU2" SG_ 1155 EBDFailSts 0;
BA_ "GenSigTimeoutTime_GNMM" SG_ 1155 EBDFailSts 0;
BA_ "GenSigTimeoutTime_HCP" SG_ 1155 EBDFailSts 0;
BA_ "GenSigTimeoutTime_RFHM" SG_ 1155 EBDFailSts 0;
BA_ "GenSigTimeoutTime_TCM" SG_ 1155 EBDFailSts 0;
BA_ "GenSigSendType" SG_ 1155 ERMActive 3;
BA_ "GenSigTimeoutTime_AGSM" SG_ 1155 ERMActive 0;
BA_ "GenSigTimeoutTime_BSM" SG_ 1155 ERMActive 0;
BA_ "GenSigTimeoutTime_CADM" SG_ 1155 ERMActive 0;
BA_ "GenSigTimeoutTime_DMSM" SG_ 1155 ERMActive 0;
BA_ "GenSigTimeoutTime_ECM" SG_ 1155 ERMActive 0;
BA_ "GenSigTimeoutTime_EVCU2" SG_ 1155 ERMActive 0;
BA_ "GenSigTimeoutTime_GNMM" SG_ 1155 ERMActive 0;
BA_ "GenSigTimeoutTime_HCP" SG_ 1155 ERMActive 0;
BA_ "GenSigTimeoutTime_IPC" SG_ 1155 ERMActive 0;
BA_ "GenSigTimeoutTime_RFHM" SG_ 1155 ERMActive 0;
BA_ "GenSigTimeoutTime_SGW" SG_ 1155 ERMActive 0;
BA_ "GenSigTimeoutTime_TCM" SG_ 1155 ERMActive 0;
BA_ "GenSigSendType" SG_ 1155 ESCFailSts 3;
BA_ "GenSigTimeoutTime_AGSM" SG_ 1155 ESCFailSts 0;
BA_ "GenSigTimeoutTime_BSM" SG_ 1155 ESCFailSts 0;
BA_ "GenSigTimeoutTime_CADM" SG_ 1155 ESCFailSts 0;
BA_ "GenSigTimeoutTime_DMSM" SG_ 1155 ESCFailSts 0;
BA_ "GenSigTimeoutTime_DTCM" SG_ 1155 ESCFailSts 0;
BA_ "GenSigTimeoutTime_GNMM" SG_ 1155 ESCFailSts 0;
BA_ "GenSigTimeoutTime_HCP" SG_ 1155 ESCFailSts 0;
BA_ "GenSigTimeoutTime_RFHM" SG_ 1155 ESCFailSts 0;
BA_ "GenSigTimeoutTime_TCM" SG_ 1155 ESCFailSts 0;
BA_ "GenSigSendType" SG_ 1155 ESCIntervention 3;
BA_ "GenSigTimeoutTime_AGSM" SG_ 1155 ESCIntervention 0;
BA_ "GenSigTimeoutTime_BSM" SG_ 1155 ESCIntervention 0;
BA_ "GenSigTimeoutTime_CADM" SG_ 1155 ESCIntervention 0;
BA_ "GenSigTimeoutTime_DMSM" SG_ 1155 ESCIntervention 0;
BA_ "GenSigTimeoutTime_ECM" SG_ 1155 ESCIntervention 0;
BA_ "GenSigTimeoutTime_GNMM" SG_ 1155 ESCIntervention 0;
BA_ "GenSigTimeoutTime_HCP" SG_ 1155 ESCIntervention 0;
BA_ "GenSigTimeoutTime_RFHM" SG_ 1155 ESCIntervention 0;
BA_ "GenSigTimeoutTime_SGW" SG_ 1155 ESCIntervention 0;
BA_ "GenSigTimeoutTime_TCM" SG_ 1155 ESCIntervention 0;
BA_ "GenSigSendType" SG_ 1155 Function2Sts 3;
BA_ "GenSigTimeoutTime_AGSM" SG_ 1155 Function2Sts 0;
BA_ "GenSigTimeoutTime_BSM" SG_ 1155 Function2Sts 0;
BA_ "GenSigTimeoutTime_CADM" SG_ 1155 Function2Sts 0;
BA_ "GenSigTimeoutTime_DMSM" SG_ 1155 Function2Sts 0;
BA_ "GenSigTimeoutTime_ECM" SG_ 1155 Function2Sts 0;
BA_ "GenSigTimeoutTime_GNMM" SG_ 1155 Function2Sts 0;
BA_ "GenSigTimeoutTime_HCP" SG_ 1155 Function2Sts 0;
BA_ "GenSigTimeoutTime_RFHM" SG_ 1155 Function2Sts 0;
BA_ "GenSigSendType" SG_ 1155 FunctionFailSts 3;
BA_ "GenSigTimeoutTime_AGSM" SG_ 1155 FunctionFailSts 0;
BA_ "GenSigTimeoutTime_BCM" SG_ 1155 FunctionFailSts 0;
BA_ "GenSigTimeoutTime_BSM" SG_ 1155 FunctionFailSts 0;
BA_ "GenSigTimeoutTime_CADM" SG_ 1155 FunctionFailSts 0;
BA_ "GenSigTimeoutTime_DMSM" SG_ 1155 FunctionFailSts 0;
BA_ "GenSigTimeoutTime_DTCM" SG_ 1155 FunctionFailSts 0;
BA_ "GenSigTimeoutTime_ECM" SG_ 1155 FunctionFailSts 0;
BA_ "GenSigTimeoutTime_EVCU2" SG_ 1155 FunctionFailSts 0;
BA_ "GenSigTimeoutTime_GNMM" SG_ 1155 FunctionFailSts 0;
BA_ "GenSigTimeoutTime_HCP" SG_ 1155 FunctionFailSts 0;
BA_ "GenSigTimeoutTime_IPC" SG_ 1155 FunctionFailSts 0;
BA_ "GenSigTimeoutTime_RFHM" SG_ 1155 FunctionFailSts 0;
BA_ "GenSigTimeoutTime_SGW" SG_ 1155 FunctionFailSts 0;
BA_ "GenSigTimeoutTime_TCM" SG_ 1155 FunctionFailSts 0;
BA_ "GenSigSendType" SG_ 1155 FunctionIntervention 3;
BA_ "GenSigTimeoutTime_AGSM" SG_ 1155 FunctionIntervention 0;
BA_ "GenSigTimeoutTime_BCM" SG_ 1155 FunctionIntervention 0;
BA_ "GenSigTimeoutTime_BSM" SG_ 1155 FunctionIntervention 0;
BA_ "GenSigTimeoutTime_CADM" SG_ 1155 FunctionIntervention 0;
BA_ "GenSigTimeoutTime_DMSM" SG_ 1155 FunctionIntervention 0;
BA_ "GenSigTimeoutTime_ECM" SG_ 1155 FunctionIntervention 0;
BA_ "GenSigTimeoutTime_EVCU2" SG_ 1155 FunctionIntervention 0;
BA_ "GenSigTimeoutTime_GNMM" SG_ 1155 FunctionIntervention 0;
BA_ "GenSigTimeoutTime_HCP" SG_ 1155 FunctionIntervention 0;
BA_ "GenSigTimeoutTime_IPC" SG_ 1155 FunctionIntervention 0;
BA_ "GenSigTimeoutTime_RFHM" SG_ 1155 FunctionIntervention 0;
BA_ "GenSigTimeoutTime_SGW" SG_ 1155 FunctionIntervention 0;
BA_ "GenSigTimeoutTime_TCM" SG_ 1155 FunctionIntervention 0;
BA_ "GenSigSendType" SG_ 1155 FunctionSts 3;
BA_ "GenSigTimeoutTime_AGSM" SG_ 1155 FunctionSts 0;
BA_ "GenSigTimeoutTime_BSM" SG_ 1155 FunctionSts 0;
BA_ "GenSigTimeoutTime_CADM" SG_ 1155 FunctionSts 0;
BA_ "GenSigTimeoutTime_DMSM" SG_ 1155 FunctionSts 0;
BA_ "GenSigTimeoutTime_ECM" SG_ 1155 FunctionSts 0;
BA_ "GenSigTimeoutTime_GNMM" SG_ 1155 FunctionSts 0;
BA_ "GenSigTimeoutTime_HCP" SG_ 1155 FunctionSts 0;
BA_ "GenSigTimeoutTime_RFHM" SG_ 1155 FunctionSts 0;
BA_ "GenSigTimeoutTime_SGW" SG_ 1155 FunctionSts 0;
BA_ "GenSigTimeoutTime_TCM" SG_ 1155 FunctionSts 0;
BA_ "GenSigStartValue" SG_ 1155 HDCUserFdBck 1;
BA_ "GenSigSendType" SG_ 1155 HDCUserFdBck 3;
BA_ "GenSigTimeoutTime_AGSM" SG_ 1155 HDCUserFdBck 0;
BA_ "GenSigTimeoutTime_BSM" SG_ 1155 HDCUserFdBck 0;
BA_ "GenSigTimeoutTime_CADM" SG_ 1155 HDCUserFdBck 0;
BA_ "GenSigTimeoutTime_DMSM" SG_ 1155 HDCUserFdBck 0;
BA_ "GenSigTimeoutTime_DTCM" SG_ 1155 HDCUserFdBck 0;
BA_ "GenSigTimeoutTime_ECM" SG_ 1155 HDCUserFdBck 0;
BA_ "GenSigTimeoutTime_EVCU2" SG_ 1155 HDCUserFdBck 0;
BA_ "GenSigTimeoutTime_GNMM" SG_ 1155 HDCUserFdBck 0;
BA_ "GenSigTimeoutTime_HCP" SG_ 1155 HDCUserFdBck 0;
BA_ "GenSigTimeoutTime_IPC" SG_ 1155 HDCUserFdBck 0;
BA_ "GenSigTimeoutTime_RFHM" SG_ 1155 HDCUserFdBck 0;
BA_ "GenSigTimeoutTime_SGW" SG_ 1155 HDCUserFdBck 0;
BA_ "GenSigTimeoutTime_TCM" SG_ 1155 HDCUserFdBck 0;
BA_ "GenSigSendType" SG_ 1155 HillHolderFailSts 3;
BA_ "GenSigTimeoutTime_AGSM" SG_ 1155 HillHolderFailSts 0;
BA_ "GenSigTimeoutTime_BCM" SG_ 1155 HillHolderFailSts 0;
BA_ "GenSigTimeoutTime_BSM" SG_ 1155 HillHolderFailSts 0;
BA_ "GenSigTimeoutTime_CADM" SG_ 1155 HillHolderFailSts 0;
BA_ "GenSigTimeoutTime_DMSM" SG_ 1155 HillHolderFailSts 0;
BA_ "GenSigTimeoutTime_DTCM" SG_ 1155 HillHolderFailSts 0;
BA_ "GenSigTimeoutTime_ECM" SG_ 1155 HillHolderFailSts 0;
BA_ "GenSigTimeoutTime_EVCU2" SG_ 1155 HillHolderFailSts 0;
BA_ "GenSigTimeoutTime_GNMM" SG_ 1155 HillHolderFailSts 0;
BA_ "GenSigTimeoutTime_HCP" SG_ 1155 HillHolderFailSts 0;
BA_ "GenSigTimeoutTime_IPC" SG_ 1155 HillHolderFailSts 0;
BA_ "GenSigTimeoutTime_RFHM" SG_ 1155 HillHolderFailSts 0;
BA_ "GenSigTimeoutTime_TCM" SG_ 1155 HillHolderFailSts 0;
BA_ "GenSigSendType" SG_ 1155 LnchCtrl_UserFdBck 3;
BA_ "GenSigTimeoutTime_AGSM" SG_ 1155 LnchCtrl_UserFdBck 0;
BA_ "GenSigTimeoutTime_BSM" SG_ 1155 LnchCtrl_UserFdBck 0;
BA_ "GenSigTimeoutTime_CADM" SG_ 1155 LnchCtrl_UserFdBck 0;
BA_ "GenSigTimeoutTime_DMSM" SG_ 1155 LnchCtrl_UserFdBck 0;
BA_ "GenSigTimeoutTime_DTCM" SG_ 1155 LnchCtrl_UserFdBck 0;
BA_ "GenSigTimeoutTime_ECM" SG_ 1155 LnchCtrl_UserFdBck 0;
BA_ "GenSigTimeoutTime_EVCU2" SG_ 1155 LnchCtrl_UserFdBck 0;
BA_ "GenSigTimeoutTime_GNMM" SG_ 1155 LnchCtrl_UserFdBck 0;
BA_ "GenSigTimeoutTime_HCP" SG_ 1155 LnchCtrl_UserFdBck 0;
BA_ "GenSigTimeoutTime_IPC" SG_ 1155 LnchCtrl_UserFdBck 0;
BA_ "GenSigTimeoutTime_RFHM" SG_ 1155 LnchCtrl_UserFdBck 0;
BA_ "GenSigTimeoutTime_SGW" SG_ 1155 LnchCtrl_UserFdBck 0;
BA_ "GenSigTimeoutTime_TCM" SG_ 1155 LnchCtrl_UserFdBck 0;
BA_ "GenSigTimeoutTime_AGSM" SG_ 1155 MessageCounter_BRAKE5 0;
BA_ "GenSigTimeoutTime_BSM" SG_ 1155 MessageCounter_BRAKE5 0;
BA_ "GenSigTimeoutTime_CADM" SG_ 1155 MessageCounter_BRAKE5 0;
BA_ "GenSigTimeoutTime_DMSM" SG_ 1155 MessageCounter_BRAKE5 0;
BA_ "GenSigTimeoutTime_GNMM" SG_ 1155 MessageCounter_BRAKE5 0;
BA_ "GenSigTimeoutTime_HCP" SG_ 1155 MessageCounter_BRAKE5 0;
BA_ "GenSigTimeoutTime_RFHM" SG_ 1155 MessageCounter_BRAKE5 0;
BA_ "GenSigTimeoutTime_SGW" SG_ 1155 MessageCounter_BRAKE5 0;
BA_ "GenSigSendType" SG_ 1155 RollsModeAct 3;
BA_ "GenSigTimeoutTime_AGSM" SG_ 1155 RollsModeAct 0;
BA_ "GenSigTimeoutTime_BCM" SG_ 1155 RollsModeAct 0;
BA_ "GenSigTimeoutTime_BSM" SG_ 1155 RollsModeAct 0;
BA_ "GenSigTimeoutTime_CADM" SG_ 1155 RollsModeAct 0;
BA_ "GenSigTimeoutTime_DMSM" SG_ 1155 RollsModeAct 0;
BA_ "GenSigTimeoutTime_GNMM" SG_ 1155 RollsModeAct 0;
BA_ "GenSigTimeoutTime_HCP" SG_ 1155 RollsModeAct 0;
BA_ "GenSigTimeoutTime_IPC" SG_ 1155 RollsModeAct 0;
BA_ "GenSigTimeoutTime_RFHM" SG_ 1155 RollsModeAct 0;
BA_ "GenSigTimeoutTime_SGW" SG_ 1155 RollsModeAct 0;
BA_ "GenSigTimeoutTime_TCM" SG_ 1155 RollsModeAct 0;
BA_ "GenSigSendType" SG_ 1155 TSCActive 3;
BA_ "GenSigTimeoutTime_AGSM" SG_ 1155 TSCActive 0;
BA_ "GenSigTimeoutTime_BSM" SG_ 1155 TSCActive 0;
BA_ "GenSigTimeoutTime_CADM" SG_ 1155 TSCActive 0;
BA_ "GenSigTimeoutTime_DMSM" SG_ 1155 TSCActive 0;
BA_ "GenSigTimeoutTime_DTCM" SG_ 1155 TSCActive 0;
BA_ "GenSigTimeoutTime_ECM" SG_ 1155 TSCActive 0;
BA_ "GenSigTimeoutTime_EVCU2" SG_ 1155 TSCActive 0;
BA_ "GenSigTimeoutTime_GNMM" SG_ 1155 TSCActive 0;
BA_ "GenSigTimeoutTime_HCP" SG_ 1155 TSCActive 0;
BA_ "GenSigTimeoutTime_IPC" SG_ 1155 TSCActive 0;
BA_ "GenSigTimeoutTime_RFHM" SG_ 1155 TSCActive 0;
BA_ "GenSigTimeoutTime_SGW" SG_ 1155 TSCActive 0;
BA_ "GenSigTimeoutTime_TCM" SG_ 1155 TSCActive 0;
BA_ "GenSigTimeoutTime_AGSM" SG_ 205 Cmnd_TotBrkFrict_AxleTorq 0;
BA_ "GenSigTimeoutTime_BCM" SG_ 205 Cmnd_TotBrkFrict_AxleTorq 0;
BA_ "GenSigTimeoutTime_BSM" SG_ 205 Cmnd_TotBrkFrict_AxleTorq 0;
BA_ "GenSigTimeoutTime_CADM" SG_ 205 Cmnd_TotBrkFrict_AxleTorq 0;
BA_ "GenSigTimeoutTime_DMSM" SG_ 205 Cmnd_TotBrkFrict_AxleTorq 0;
BA_ "GenSigTimeoutTime_DTCM" SG_ 205 Cmnd_TotBrkFrict_AxleTorq 0;
BA_ "GenSigTimeoutTime_ECM" SG_ 205 Cmnd_TotBrkFrict_AxleTorq 0;
BA_ "GenSigTimeoutTime_GNMM" SG_ 205 Cmnd_TotBrkFrict_AxleTorq 0;
BA_ "GenSigTimeoutTime_HCP" SG_ 205 Cmnd_TotBrkFrict_AxleTorq 0;
BA_ "GenSigTimeoutTime_IPC" SG_ 205 Cmnd_TotBrkFrict_AxleTorq 0;
BA_ "GenSigTimeoutTime_RFHM" SG_ 205 Cmnd_TotBrkFrict_AxleTorq 0;
BA_ "GenSigTimeoutTime_SGW" SG_ 205 Cmnd_TotBrkFrict_AxleTorq 0;
BA_ "GenSigTimeoutTime_TCM" SG_ 205 Cmnd_TotBrkFrict_AxleTorq 0;
BA_ "GenSigTimeoutTime_AGSM" SG_ 205 CRC_BRAKE_FD_6 0;
BA_ "GenSigTimeoutTime_BCM" SG_ 205 CRC_BRAKE_FD_6 0;
BA_ "GenSigTimeoutTime_BSM" SG_ 205 CRC_BRAKE_FD_6 0;
BA_ "GenSigTimeoutTime_CADM" SG_ 205 CRC_BRAKE_FD_6 0;
BA_ "GenSigTimeoutTime_DMSM" SG_ 205 CRC_BRAKE_FD_6 0;
BA_ "GenSigTimeoutTime_DTCM" SG_ 205 CRC_BRAKE_FD_6 0;
BA_ "GenSigTimeoutTime_GNMM" SG_ 205 CRC_BRAKE_FD_6 0;
BA_ "GenSigTimeoutTime_HCP" SG_ 205 CRC_BRAKE_FD_6 0;
BA_ "GenSigTimeoutTime_IPC" SG_ 205 CRC_BRAKE_FD_6 0;
BA_ "GenSigTimeoutTime_RFHM" SG_ 205 CRC_BRAKE_FD_6 0;
BA_ "GenSigTimeoutTime_SGW" SG_ 205 CRC_BRAKE_FD_6 0;
BA_ "GenSigTimeoutTime_TCM" SG_ 205 CRC_BRAKE_FD_6 0;
BA_ "GenSigTimeoutTime_AGSM" SG_ 205 DriverReq_AxleTrq_Enabled_BSM 0;
BA_ "GenSigTimeoutTime_BCM" SG_ 205 DriverReq_AxleTrq_Enabled_BSM 0;
BA_ "GenSigTimeoutTime_BSM" SG_ 205 DriverReq_AxleTrq_Enabled_BSM 0;
BA_ "GenSigTimeoutTime_CADM" SG_ 205 DriverReq_AxleTrq_Enabled_BSM 0;
BA_ "GenSigTimeoutTime_DMSM" SG_ 205 DriverReq_AxleTrq_Enabled_BSM 0;
BA_ "GenSigTimeoutTime_DTCM" SG_ 205 DriverReq_AxleTrq_Enabled_BSM 0;
BA_ "GenSigTimeoutTime_GNMM" SG_ 205 DriverReq_AxleTrq_Enabled_BSM 0;
BA_ "GenSigTimeoutTime_HCP" SG_ 205 DriverReq_AxleTrq_Enabled_BSM 0;
BA_ "GenSigTimeoutTime_IPC" SG_ 205 DriverReq_AxleTrq_Enabled_BSM 0;
BA_ "GenSigTimeoutTime_RFHM" SG_ 205 DriverReq_AxleTrq_Enabled_BSM 0;
BA_ "GenSigTimeoutTime_SGW" SG_ 205 DriverReq_AxleTrq_Enabled_BSM 0;
BA_ "GenSigTimeoutTime_TCM" SG_ 205 DriverReq_AxleTrq_Enabled_BSM 0;
BA_ "GenSigStartValue" SG_ 205 DriverRequested_AxleTrq_BSM 32767;
BA_ "GenSigTimeoutTime_AGSM" SG_ 205 DriverRequested_AxleTrq_BSM 0;
BA_ "GenSigTimeoutTime_BCM" SG_ 205 DriverRequested_AxleTrq_BSM 0;
BA_ "GenSigTimeoutTime_BSM" SG_ 205 DriverRequested_AxleTrq_BSM 0;
BA_ "GenSigTimeoutTime_CADM" SG_ 205 DriverRequested_AxleTrq_BSM 0;
BA_ "GenSigTimeoutTime_DMSM" SG_ 205 DriverRequested_AxleTrq_BSM 0;
BA_ "GenSigTimeoutTime_GNMM" SG_ 205 DriverRequested_AxleTrq_BSM 0;
BA_ "GenSigTimeoutTime_HCP" SG_ 205 DriverRequested_AxleTrq_BSM 0;
BA_ "GenSigTimeoutTime_IPC" SG_ 205 DriverRequested_AxleTrq_BSM 0;
BA_ "GenSigTimeoutTime_RFHM" SG_ 205 DriverRequested_AxleTrq_BSM 0;
BA_ "GenSigTimeoutTime_SGW" SG_ 205 DriverRequested_AxleTrq_BSM 0;
BA_ "GenSigTimeoutTime_TCM" SG_ 205 DriverRequested_AxleTrq_BSM 0;
BA_ "GenSigTimeoutTime_AGSM" SG_ 205 DrvrIntd_TotalBrk_AxleTorq 0;
BA_ "GenSigTimeoutTime_BSM" SG_ 205 DrvrIntd_TotalBrk_AxleTorq 0;
BA_ "GenSigTimeoutTime_CADM" SG_ 205 DrvrIntd_TotalBrk_AxleTorq 0;
BA_ "GenSigTimeoutTime_DMSM" SG_ 205 DrvrIntd_TotalBrk_AxleTorq 0;
BA_ "GenSigTimeoutTime_DTCM" SG_ 205 DrvrIntd_TotalBrk_AxleTorq 0;
BA_ "GenSigTimeoutTime_ECM" SG_ 205 DrvrIntd_TotalBrk_AxleTorq 0;
BA_ "GenSigTimeoutTime_GNMM" SG_ 205 DrvrIntd_TotalBrk_AxleTorq 0;
BA_ "GenSigTimeoutTime_HCP" SG_ 205 DrvrIntd_TotalBrk_AxleTorq 0;
BA_ "GenSigTimeoutTime_IPC" SG_ 205 DrvrIntd_TotalBrk_AxleTorq 0;
BA_ "GenSigTimeoutTime_RFHM" SG_ 205 DrvrIntd_TotalBrk_AxleTorq 0;
BA_ "GenSigTimeoutTime_SGW" SG_ 205 DrvrIntd_TotalBrk_AxleTorq 0;
BA_ "GenSigTimeoutTime_TCM" SG_ 205 DrvrIntd_TotalBrk_AxleTorq 0;
BA_ "GenSigTimeoutTime_AGSM" SG_ 205 FrontAxle_Max_Rq_BSM 0;
BA_ "GenSigTimeoutTime_BCM" SG_ 205 FrontAxle_Max_Rq_BSM 0;
BA_ "GenSigTimeoutTime_BSM" SG_ 205 FrontAxle_Max_Rq_BSM 0;
BA_ "GenSigTimeoutTime_CADM" SG_ 205 FrontAxle_Max_Rq_BSM 0;
BA_ "GenSigTimeoutTime_DMSM" SG_ 205 FrontAxle_Max_Rq_BSM 0;
BA_ "GenSigTimeoutTime_DTCM" SG_ 205 FrontAxle_Max_Rq_BSM 0;
BA_ "GenSigTimeoutTime_ECM" SG_ 205 FrontAxle_Max_Rq_BSM 0;
BA_ "GenSigTimeoutTime_GNMM" SG_ 205 FrontAxle_Max_Rq_BSM 0;
BA_ "GenSigTimeoutTime_HCP" SG_ 205 FrontAxle_Max_Rq_BSM 0;
BA_ "GenSigTimeoutTime_IPC" SG_ 205 FrontAxle_Max_Rq_BSM 0;
BA_ "GenSigTimeoutTime_RFHM" SG_ 205 FrontAxle_Max_Rq_BSM 0;
BA_ "GenSigTimeoutTime_SGW" SG_ 205 FrontAxle_Max_Rq_BSM 0;
BA_ "GenSigTimeoutTime_TCM" SG_ 205 FrontAxle_Max_Rq_BSM 0;
BA_ "GenSigTimeoutTime_AGSM" SG_ 205 FrontAxle_Min_Rq_BSM 0;
BA_ "GenSigTimeoutTime_BCM" SG_ 205 FrontAxle_Min_Rq_BSM 0;
BA_ "GenSigTimeoutTime_BSM" SG_ 205 FrontAxle_Min_Rq_BSM 0;
BA_ "GenSigTimeoutTime_CADM" SG_ 205 FrontAxle_Min_Rq_BSM 0;
BA_ "GenSigTimeoutTime_DMSM" SG_ 205 FrontAxle_Min_Rq_BSM 0;
BA_ "GenSigTimeoutTime_DTCM" SG_ 205 FrontAxle_Min_Rq_BSM 0;
BA_ "GenSigTimeoutTime_ECM" SG_ 205 FrontAxle_Min_Rq_BSM 0;
BA_ "GenSigTimeoutTime_GNMM" SG_ 205 FrontAxle_Min_Rq_BSM 0;
BA_ "GenSigTimeoutTime_HCP" SG_ 205 FrontAxle_Min_Rq_BSM 0;
BA_ "GenSigTimeoutTime_IPC" SG_ 205 FrontAxle_Min_Rq_BSM 0;
BA_ "GenSigTimeoutTime_RFHM" SG_ 205 FrontAxle_Min_Rq_BSM 0;
BA_ "GenSigTimeoutTime_SGW" SG_ 205 FrontAxle_Min_Rq_BSM 0;
BA_ "GenSigTimeoutTime_TCM" SG_ 205 FrontAxle_Min_Rq_BSM 0;
BA_ "GenSigStartValue" SG_ 205 FrontAxle_Rq_BSM 32767;
BA_ "GenSigTimeoutTime_AGSM" SG_ 205 FrontAxle_Rq_BSM 0;
BA_ "GenSigTimeoutTime_BCM" SG_ 205 FrontAxle_Rq_BSM 0;
BA_ "GenSigTimeoutTime_BSM" SG_ 205 FrontAxle_Rq_BSM 0;
BA_ "GenSigTimeoutTime_CADM" SG_ 205 FrontAxle_Rq_BSM 0;
BA_ "GenSigTimeoutTime_DMSM" SG_ 205 FrontAxle_Rq_BSM 0;
BA_ "GenSigTimeoutTime_DTCM" SG_ 205 FrontAxle_Rq_BSM 0;
BA_ "GenSigTimeoutTime_ECM" SG_ 205 FrontAxle_Rq_BSM 0;
BA_ "GenSigTimeoutTime_GNMM" SG_ 205 FrontAxle_Rq_BSM 0;
BA_ "GenSigTimeoutTime_HCP" SG_ 205 FrontAxle_Rq_BSM 0;
BA_ "GenSigTimeoutTime_IPC" SG_ 205 FrontAxle_Rq_BSM 0;
BA_ "GenSigTimeoutTime_RFHM" SG_ 205 FrontAxle_Rq_BSM 0;
BA_ "GenSigTimeoutTime_SGW" SG_ 205 FrontAxle_Rq_BSM 0;
BA_ "GenSigTimeoutTime_TCM" SG_ 205 FrontAxle_Rq_BSM 0;
BA_ "GenSigTimeoutTime_AGSM" SG_ 205 MessageCounter_BRAKE_FD_6 0;
BA_ "GenSigTimeoutTime_BCM" SG_ 205 MessageCounter_BRAKE_FD_6 0;
BA_ "GenSigTimeoutTime_BSM" SG_ 205 MessageCounter_BRAKE_FD_6 0;
BA_ "GenSigTimeoutTime_CADM" SG_ 205 MessageCounter_BRAKE_FD_6 0;
BA_ "GenSigTimeoutTime_DMSM" SG_ 205 MessageCounter_BRAKE_FD_6 0;
BA_ "GenSigTimeoutTime_DTCM" SG_ 205 MessageCounter_BRAKE_FD_6 0;
BA_ "GenSigTimeoutTime_GNMM" SG_ 205 MessageCounter_BRAKE_FD_6 0;
BA_ "GenSigTimeoutTime_HCP" SG_ 205 MessageCounter_BRAKE_FD_6 0;
BA_ "GenSigTimeoutTime_IPC" SG_ 205 MessageCounter_BRAKE_FD_6 0;
BA_ "GenSigTimeoutTime_RFHM" SG_ 205 MessageCounter_BRAKE_FD_6 0;
BA_ "GenSigTimeoutTime_SGW" SG_ 205 MessageCounter_BRAKE_FD_6 0;
BA_ "GenSigTimeoutTime_TCM" SG_ 205 MessageCounter_BRAKE_FD_6 0;
BA_ "GenSigTimeoutTime_AGSM" SG_ 205 OPD_Hold_Status 0;
BA_ "GenSigTimeoutTime_BCM" SG_ 205 OPD_Hold_Status 0;
BA_ "GenSigTimeoutTime_BSM" SG_ 205 OPD_Hold_Status 0;
BA_ "GenSigTimeoutTime_CADM" SG_ 205 OPD_Hold_Status 0;
BA_ "GenSigTimeoutTime_DMSM" SG_ 205 OPD_Hold_Status 0;
BA_ "GenSigTimeoutTime_DTCM" SG_ 205 OPD_Hold_Status 0;
BA_ "GenSigTimeoutTime_ECM" SG_ 205 OPD_Hold_Status 0;
BA_ "GenSigTimeoutTime_GNMM" SG_ 205 OPD_Hold_Status 0;
BA_ "GenSigTimeoutTime_HCP" SG_ 205 OPD_Hold_Status 0;
BA_ "GenSigTimeoutTime_IPC" SG_ 205 OPD_Hold_Status 0;
BA_ "GenSigTimeoutTime_RFHM" SG_ 205 OPD_Hold_Status 0;
BA_ "GenSigTimeoutTime_SGW" SG_ 205 OPD_Hold_Status 0;
BA_ "GenSigTimeoutTime_TCM" SG_ 205 OPD_Hold_Status 0;
BA_ "GenSigTimeoutTime_AGSM" SG_ 205 RearAxle_Max_Rq_BSM 0;
BA_ "GenSigTimeoutTime_BCM" SG_ 205 RearAxle_Max_Rq_BSM 0;
BA_ "GenSigTimeoutTime_BSM" SG_ 205 RearAxle_Max_Rq_BSM 0;
BA_ "GenSigTimeoutTime_CADM" SG_ 205 RearAxle_Max_Rq_BSM 0;
BA_ "GenSigTimeoutTime_DMSM" SG_ 205 RearAxle_Max_Rq_BSM 0;
BA_ "GenSigTimeoutTime_DTCM" SG_ 205 RearAxle_Max_Rq_BSM 0;
BA_ "GenSigTimeoutTime_ECM" SG_ 205 RearAxle_Max_Rq_BSM 0;
BA_ "GenSigTimeoutTime_GNMM" SG_ 205 RearAxle_Max_Rq_BSM 0;
BA_ "GenSigTimeoutTime_HCP" SG_ 205 RearAxle_Max_Rq_BSM 0;
BA_ "GenSigTimeoutTime_IPC" SG_ 205 RearAxle_Max_Rq_BSM 0;
BA_ "GenSigTimeoutTime_RFHM" SG_ 205 RearAxle_Max_Rq_BSM 0;
BA_ "GenSigTimeoutTime_SGW" SG_ 205 RearAxle_Max_Rq_BSM 0;
BA_ "GenSigTimeoutTime_TCM" SG_ 205 RearAxle_Max_Rq_BSM 0;
BA_ "GenSigTimeoutTime_AGSM" SG_ 205 RearAxle_Min_Rq_BSM 0;
BA_ "GenSigTimeoutTime_BCM" SG_ 205 RearAxle_Min_Rq_BSM 0;
BA_ "GenSigTimeoutTime_BSM" SG_ 205 RearAxle_Min_Rq_BSM 0;
BA_ "GenSigTimeoutTime_CADM" SG_ 205 RearAxle_Min_Rq_BSM 0;
BA_ "GenSigTimeoutTime_DMSM" SG_ 205 RearAxle_Min_Rq_BSM 0;
BA_ "GenSigTimeoutTime_DTCM" SG_ 205 RearAxle_Min_Rq_BSM 0;
BA_ "GenSigTimeoutTime_ECM" SG_ 205 RearAxle_Min_Rq_BSM 0;
BA_ "GenSigTimeoutTime_GNMM" SG_ 205 RearAxle_Min_Rq_BSM 0;
BA_ "GenSigTimeoutTime_HCP" SG_ 205 RearAxle_Min_Rq_BSM 0;
BA_ "GenSigTimeoutTime_IPC" SG_ 205 RearAxle_Min_Rq_BSM 0;
BA_ "GenSigTimeoutTime_RFHM" SG_ 205 RearAxle_Min_Rq_BSM 0;
BA_ "GenSigTimeoutTime_SGW" SG_ 205 RearAxle_Min_Rq_BSM 0;
BA_ "GenSigTimeoutTime_TCM" SG_ 205 RearAxle_Min_Rq_BSM 0;
BA_ "GenSigStartValue" SG_ 205 RearAxle_Rq_BSM 32767;
BA_ "GenSigTimeoutTime_AGSM" SG_ 205 RearAxle_Rq_BSM 0;
BA_ "GenSigTimeoutTime_BCM" SG_ 205 RearAxle_Rq_BSM 0;
BA_ "GenSigTimeoutTime_BSM" SG_ 205 RearAxle_Rq_BSM 0;
BA_ "GenSigTimeoutTime_CADM" SG_ 205 RearAxle_Rq_BSM 0;
BA_ "GenSigTimeoutTime_DMSM" SG_ 205 RearAxle_Rq_BSM 0;
BA_ "GenSigTimeoutTime_DTCM" SG_ 205 RearAxle_Rq_BSM 0;
BA_ "GenSigTimeoutTime_ECM" SG_ 205 RearAxle_Rq_BSM 0;
BA_ "GenSigTimeoutTime_GNMM" SG_ 205 RearAxle_Rq_BSM 0;
BA_ "GenSigTimeoutTime_HCP" SG_ 205 RearAxle_Rq_BSM 0;
BA_ "GenSigTimeoutTime_IPC" SG_ 205 RearAxle_Rq_BSM 0;
BA_ "GenSigTimeoutTime_RFHM" SG_ 205 RearAxle_Rq_BSM 0;
BA_ "GenSigTimeoutTime_SGW" SG_ 205 RearAxle_Rq_BSM 0;
BA_ "GenSigTimeoutTime_TCM" SG_ 205 RearAxle_Rq_BSM 0;
BA_ "GenSigTimeoutTime_AGSM" SG_ 205 Regen_AxleTorque_Req 0;
BA_ "GenSigTimeoutTime_BCM" SG_ 205 Regen_AxleTorque_Req 0;
BA_ "GenSigTimeoutTime_BSM" SG_ 205 Regen_AxleTorque_Req 0;
BA_ "GenSigTimeoutTime_CADM" SG_ 205 Regen_AxleTorque_Req 0;
BA_ "GenSigTimeoutTime_DMSM" SG_ 205 Regen_AxleTorque_Req 0;
BA_ "GenSigTimeoutTime_DTCM" SG_ 205 Regen_AxleTorque_Req 0;
BA_ "GenSigTimeoutTime_ECM" SG_ 205 Regen_AxleTorque_Req 0;
BA_ "GenSigTimeoutTime_GNMM" SG_ 205 Regen_AxleTorque_Req 0;
BA_ "GenSigTimeoutTime_HCP" SG_ 205 Regen_AxleTorque_Req 0;
BA_ "GenSigTimeoutTime_IPC" SG_ 205 Regen_AxleTorque_Req 0;
BA_ "GenSigTimeoutTime_RFHM" SG_ 205 Regen_AxleTorque_Req 0;
BA_ "GenSigTimeoutTime_SGW" SG_ 205 Regen_AxleTorque_Req 0;
BA_ "GenSigTimeoutTime_TCM" SG_ 205 Regen_AxleTorque_Req 0;
BA_ "GenSigTimeoutTime_AGSM" SG_ 205 TotalAxle_Max_Rq_BSM 0;
BA_ "GenSigTimeoutTime_BCM" SG_ 205 TotalAxle_Max_Rq_BSM 0;
BA_ "GenSigTimeoutTime_BSM" SG_ 205 TotalAxle_Max_Rq_BSM 0;
BA_ "GenSigTimeoutTime_CADM" SG_ 205 TotalAxle_Max_Rq_BSM 0;
BA_ "GenSigTimeoutTime_DMSM" SG_ 205 TotalAxle_Max_Rq_BSM 0;
BA_ "GenSigTimeoutTime_EVCU2" SG_ 205 TotalAxle_Max_Rq_BSM 0;
BA_ "GenSigTimeoutTime_GNMM" SG_ 205 TotalAxle_Max_Rq_BSM 0;
BA_ "GenSigTimeoutTime_HCP" SG_ 205 TotalAxle_Max_Rq_BSM 0;
BA_ "GenSigTimeoutTime_IPC" SG_ 205 TotalAxle_Max_Rq_BSM 0;
BA_ "GenSigTimeoutTime_RFHM" SG_ 205 TotalAxle_Max_Rq_BSM 0;
BA_ "GenSigTimeoutTime_SGW" SG_ 205 TotalAxle_Max_Rq_BSM 0;
BA_ "GenSigTimeoutTime_AGSM" SG_ 205 TotalAxle_Min_Rq_BSM 0;
BA_ "GenSigTimeoutTime_BCM" SG_ 205 TotalAxle_Min_Rq_BSM 0;
BA_ "GenSigTimeoutTime_BSM" SG_ 205 TotalAxle_Min_Rq_BSM 0;
BA_ "GenSigTimeoutTime_CADM" SG_ 205 TotalAxle_Min_Rq_BSM 0;
BA_ "GenSigTimeoutTime_DMSM" SG_ 205 TotalAxle_Min_Rq_BSM 0;
BA_ "GenSigTimeoutTime_DTCM" SG_ 205 TotalAxle_Min_Rq_BSM 0;
BA_ "GenSigTimeoutTime_EVCU2" SG_ 205 TotalAxle_Min_Rq_BSM 0;
BA_ "GenSigTimeoutTime_GNMM" SG_ 205 TotalAxle_Min_Rq_BSM 0;
BA_ "GenSigTimeoutTime_HCP" SG_ 205 TotalAxle_Min_Rq_BSM 0;
BA_ "GenSigTimeoutTime_IPC" SG_ 205 TotalAxle_Min_Rq_BSM 0;
BA_ "GenSigTimeoutTime_RFHM" SG_ 205 TotalAxle_Min_Rq_BSM 0;
BA_ "GenSigTimeoutTime_SGW" SG_ 205 TotalAxle_Min_Rq_BSM 0;
BA_ "GenSigStartValue" SG_ 205 TotalAxle_Rq_BSM 32767;
BA_ "GenSigTimeoutTime_AGSM" SG_ 205 TotalAxle_Rq_BSM 0;
BA_ "GenSigTimeoutTime_BCM" SG_ 205 TotalAxle_Rq_BSM 0;
BA_ "GenSigTimeoutTime_BSM" SG_ 205 TotalAxle_Rq_BSM 0;
BA_ "GenSigTimeoutTime_CADM" SG_ 205 TotalAxle_Rq_BSM 0;
BA_ "GenSigTimeoutTime_DMSM" SG_ 205 TotalAxle_Rq_BSM 0;
BA_ "GenSigTimeoutTime_EVCU2" SG_ 205 TotalAxle_Rq_BSM 0;
BA_ "GenSigTimeoutTime_GNMM" SG_ 205 TotalAxle_Rq_BSM 0;
BA_ "GenSigTimeoutTime_HCP" SG_ 205 TotalAxle_Rq_BSM 0;
BA_ "GenSigTimeoutTime_IPC" SG_ 205 TotalAxle_Rq_BSM 0;
BA_ "GenSigTimeoutTime_RFHM" SG_ 205 TotalAxle_Rq_BSM 0;
BA_ "GenSigTimeoutTime_AGSM" SG_ 205 WED_MODE_RQ 0;
BA_ "GenSigTimeoutTime_BCM" SG_ 205 WED_MODE_RQ 0;
BA_ "GenSigTimeoutTime_BSM" SG_ 205 WED_MODE_RQ 0;
BA_ "GenSigTimeoutTime_CADM" SG_ 205 WED_MODE_RQ 0;
BA_ "GenSigTimeoutTime_DMSM" SG_ 205 WED_MODE_RQ 0;
BA_ "GenSigTimeoutTime_DTCM" SG_ 205 WED_MODE_RQ 0;
BA_ "GenSigTimeoutTime_ECM" SG_ 205 WED_MODE_RQ 0;
BA_ "GenSigTimeoutTime_GNMM" SG_ 205 WED_MODE_RQ 0;
BA_ "GenSigTimeoutTime_HCP" SG_ 205 WED_MODE_RQ 0;
BA_ "GenSigTimeoutTime_IPC" SG_ 205 WED_MODE_RQ 0;
BA_ "GenSigTimeoutTime_RFHM" SG_ 205 WED_MODE_RQ 0;
BA_ "GenSigTimeoutTime_SGW" SG_ 205 WED_MODE_RQ 0;
BA_ "GenSigTimeoutTime_TCM" SG_ 205 WED_MODE_RQ 0;
BA_ "GenSigTimeoutTime_AGSM" SG_ 514 AEB_Type_Brk 0;
BA_ "GenSigTimeoutTime_BSM" SG_ 514 AEB_Type_Brk 0;
BA_ "GenSigTimeoutTime_DMSM" SG_ 514 AEB_Type_Brk 0;
BA_ "GenSigTimeoutTime_DTCM" SG_ 514 AEB_Type_Brk 0;
BA_ "GenSigTimeoutTime_ECM" SG_ 514 AEB_Type_Brk 0;
BA_ "GenSigTimeoutTime_EVCU2" SG_ 514 AEB_Type_Brk 0;
BA_ "GenSigTimeoutTime_GNMM" SG_ 514 AEB_Type_Brk 0;
BA_ "GenSigTimeoutTime_HCP" SG_ 514 AEB_Type_Brk 0;
BA_ "GenSigTimeoutTime_IPC" SG_ 514 AEB_Type_Brk 0;
BA_ "GenSigTimeoutTime_RFHM" SG_ 514 AEB_Type_Brk 0;
BA_ "GenSigTimeoutTime_SGW" SG_ 514 AEB_Type_Brk 0;
BA_ "GenSigTimeoutTime_TCM" SG_ 514 AEB_Type_Brk 0;
BA_ "GenSigTimeoutTime_AGSM" SG_ 514 Brake_OpStat_Prim 0;
BA_ "GenSigTimeoutTime_BCM" SG_ 514 Brake_OpStat_Prim 0;
BA_ "GenSigTimeoutTime_BSM" SG_ 514 Brake_OpStat_Prim 0;
BA_ "GenSigTimeoutTime_DMSM" SG_ 514 Brake_OpStat_Prim 0;
BA_ "GenSigTimeoutTime_DTCM" SG_ 514 Brake_OpStat_Prim 0;
BA_ "GenSigTimeoutTime_ECM" SG_ 514 Brake_OpStat_Prim 0;
BA_ "GenSigTimeoutTime_EVCU2" SG_ 514 Brake_OpStat_Prim 0;
BA_ "GenSigTimeoutTime_GNMM" SG_ 514 Brake_OpStat_Prim 0;
BA_ "GenSigTimeoutTime_HCP" SG_ 514 Brake_OpStat_Prim 0;
BA_ "GenSigTimeoutTime_IPC" SG_ 514 Brake_OpStat_Prim 0;
BA_ "GenSigTimeoutTime_RFHM" SG_ 514 Brake_OpStat_Prim 0;
BA_ "GenSigTimeoutTime_SGW" SG_ 514 Brake_OpStat_Prim 0;
BA_ "GenSigTimeoutTime_TCM" SG_ 514 Brake_OpStat_Prim 0;
BA_ "GenSigTimeoutTime_AGSM" SG_ 514 BrakePdlPosn 0;
BA_ "GenSigTimeoutTime_BSM" SG_ 514 BrakePdlPosn 0;
BA_ "GenSigTimeoutTime_CADM" SG_ 514 BrakePdlPosn 0;
BA_ "GenSigTimeoutTime_DMSM" SG_ 514 BrakePdlPosn 0;
BA_ "GenSigTimeoutTime_DTCM" SG_ 514 BrakePdlPosn 0;
BA_ "GenSigTimeoutTime_GNMM" SG_ 514 BrakePdlPosn 0;
BA_ "GenSigTimeoutTime_HCP" SG_ 514 BrakePdlPosn 0;
BA_ "GenSigTimeoutTime_IPC" SG_ 514 BrakePdlPosn 0;
BA_ "GenSigTimeoutTime_RFHM" SG_ 514 BrakePdlPosn 0;
BA_ "GenSigTimeoutTime_AGSM" SG_ 514 BrkPdl_Flt 0;
BA_ "GenSigTimeoutTime_BSM" SG_ 514 BrkPdl_Flt 0;
BA_ "GenSigTimeoutTime_CADM" SG_ 514 BrkPdl_Flt 0;
BA_ "GenSigTimeoutTime_DMSM" SG_ 514 BrkPdl_Flt 0;
BA_ "GenSigTimeoutTime_GNMM" SG_ 514 BrkPdl_Flt 0;
BA_ "GenSigTimeoutTime_HCP" SG_ 514 BrkPdl_Flt 0;
BA_ "GenSigTimeoutTime_IPC" SG_ 514 BrkPdl_Flt 0;
BA_ "GenSigTimeoutTime_RFHM" SG_ 514 BrkPdl_Flt 0;
BA_ "GenSigTimeoutTime_TCM" SG_ 514 BrkPdl_Flt 0;
BA_ "GenSigStartValue" SG_ 514 BrkPdl_Stat 3;
BA_ "GenSigTimeoutTime_AGSM" SG_ 514 BrkPdl_Stat 0;
BA_ "GenSigTimeoutTime_BSM" SG_ 514 BrkPdl_Stat 0;
BA_ "GenSigTimeoutTime_DMSM" SG_ 514 BrkPdl_Stat 0;
BA_ "GenSigTimeoutTime_GNMM" SG_ 514 BrkPdl_Stat 0;
BA_ "GenSigTimeoutTime_HCP" SG_ 514 BrkPdl_Stat 0;
BA_ "GenSigTimeoutTime_IPC" SG_ 514 BrkPdl_Stat 0;
BA_ "GenSigTimeoutTime_AGSM" SG_ 514 BSM_OpStat 0;
BA_ "GenSigTimeoutTime_BSM" SG_ 514 BSM_OpStat 0;
BA_ "GenSigTimeoutTime_DMSM" SG_ 514 BSM_OpStat 0;
BA_ "GenSigTimeoutTime_DTCM" SG_ 514 BSM_OpStat 0;
BA_ "GenSigTimeoutTime_ECM" SG_ 514 BSM_OpStat 0;
BA_ "GenSigTimeoutTime_EVCU2" SG_ 514 BSM_OpStat 0;
BA_ "GenSigTimeoutTime_GNMM" SG_ 514 BSM_OpStat 0;
BA_ "GenSigTimeoutTime_HCP" SG_ 514 BSM_OpStat 0;
BA_ "GenSigTimeoutTime_IPC" SG_ 514 BSM_OpStat 0;
BA_ "GenSigTimeoutTime_RFHM" SG_ 514 BSM_OpStat 0;
BA_ "GenSigTimeoutTime_SGW" SG_ 514 BSM_OpStat 0;
BA_ "GenSigTimeoutTime_TCM" SG_ 514 BSM_OpStat 0;
BA_ "GenSigTimeoutTime_AGSM" SG_ 514 BSM_ReadyForESS 0;
BA_ "GenSigTimeoutTime_BSM" SG_ 514 BSM_ReadyForESS 0;
BA_ "GenSigTimeoutTime_CADM" SG_ 514 BSM_ReadyForESS 0;
BA_ "GenSigTimeoutTime_DMSM" SG_ 514 BSM_ReadyForESS 0;
BA_ "GenSigTimeoutTime_DTCM" SG_ 514 BSM_ReadyForESS 0;
BA_ "GenSigTimeoutTime_EVCU2" SG_ 514 BSM_ReadyForESS 0;
BA_ "GenSigTimeoutTime_GNMM" SG_ 514 BSM_ReadyForESS 0;
BA_ "GenSigTimeoutTime_HCP" SG_ 514 BSM_ReadyForESS 0;
BA_ "GenSigTimeoutTime_IPC" SG_ 514 BSM_ReadyForESS 0;
BA_ "GenSigTimeoutTime_RFHM" SG_ 514 BSM_ReadyForESS 0;
BA_ "GenSigTimeoutTime_SGW" SG_ 514 BSM_ReadyForESS 0;
BA_ "GenSigTimeoutTime_TCM" SG_ 514 BSM_ReadyForESS 0;
BA_ "GenSigTimeoutTime_AGSM" SG_ 514 CRC_BRAKE7 0;
BA_ "GenSigTimeoutTime_BSM" SG_ 514 CRC_BRAKE7 0;
BA_ "GenSigTimeoutTime_DMSM" SG_ 514 CRC_BRAKE7 0;
BA_ "GenSigTimeoutTime_GNMM" SG_ 514 CRC_BRAKE7 0;
BA_ "GenSigTimeoutTime_IPC" SG_ 514 CRC_BRAKE7 0;
BA_ "GenSigTimeoutTime_RFHM" SG_ 514 CRC_BRAKE7 0;
BA_ "GenSigTimeoutTime_SGW" SG_ 514 CRC_BRAKE7 0;
BA_ "GenSigTimeoutTime_AGSM" SG_ 514 MessageCounter_BRAKE7 0;
BA_ "GenSigTimeoutTime_BSM" SG_ 514 MessageCounter_BRAKE7 0;
BA_ "GenSigTimeoutTime_DMSM" SG_ 514 MessageCounter_BRAKE7 0;
BA_ "GenSigTimeoutTime_GNMM" SG_ 514 MessageCounter_BRAKE7 0;
BA_ "GenSigTimeoutTime_IPC" SG_ 514 MessageCounter_BRAKE7 0;
BA_ "GenSigTimeoutTime_RFHM" SG_ 514 MessageCounter_BRAKE7 0;
BA_ "GenSigTimeoutTime_SGW" SG_ 514 MessageCounter_BRAKE7 0;
BA_ "GenSigTimeoutTime_AGSM" SG_ 514 PAM_Brk_Rq_RspSts 0;
BA_ "GenSigTimeoutTime_BSM" SG_ 514 PAM_Brk_Rq_RspSts 0;
BA_ "GenSigTimeoutTime_CADM" SG_ 514 PAM_Brk_Rq_RspSts 0;
BA_ "GenSigTimeoutTime_DMSM" SG_ 514 PAM_Brk_Rq_RspSts 0;
BA_ "GenSigTimeoutTime_DTCM" SG_ 514 PAM_Brk_Rq_RspSts 0;
BA_ "GenSigTimeoutTime_ECM" SG_ 514 PAM_Brk_Rq_RspSts 0;
BA_ "GenSigTimeoutTime_EVCU2" SG_ 514 PAM_Brk_Rq_RspSts 0;
BA_ "GenSigTimeoutTime_GNMM" SG_ 514 PAM_Brk_Rq_RspSts 0;
BA_ "GenSigTimeoutTime_HCP" SG_ 514 PAM_Brk_Rq_RspSts 0;
BA_ "GenSigTimeoutTime_RFHM" SG_ 514 PAM_Brk_Rq_RspSts 0;
BA_ "GenSigTimeoutTime_SGW" SG_ 514 PAM_Brk_Rq_RspSts 0;
BA_ "GenSigTimeoutTime_TCM" SG_ 514 PAM_Brk_Rq_RspSts 0;
BA_ "GenSigStartValue" SG_ 514 R_DIFF_TRQ_RQ 511;
BA_ "GenSigTimeoutTime_AGSM" SG_ 514 R_DIFF_TRQ_RQ 0;
BA_ "GenSigTimeoutTime_BCM" SG_ 514 R_DIFF_TRQ_RQ 0;
BA_ "GenSigTimeoutTime_BSM" SG_ 514 R_DIFF_TRQ_RQ 0;
BA_ "GenSigTimeoutTime_CADM" SG_ 514 R_DIFF_TRQ_RQ 0;
BA_ "GenSigTimeoutTime_DMSM" SG_ 514 R_DIFF_TRQ_RQ 0;
BA_ "GenSigTimeoutTime_ECM" SG_ 514 R_DIFF_TRQ_RQ 0;
BA_ "GenSigTimeoutTime_GNMM" SG_ 514 R_DIFF_TRQ_RQ 0;
BA_ "GenSigTimeoutTime_HCP" SG_ 514 R_DIFF_TRQ_RQ 0;
BA_ "GenSigTimeoutTime_IPC" SG_ 514 R_DIFF_TRQ_RQ 0;
BA_ "GenSigTimeoutTime_RFHM" SG_ 514 R_DIFF_TRQ_RQ 0;
BA_ "GenSigTimeoutTime_SGW" SG_ 514 R_DIFF_TRQ_RQ 0;
BA_ "GenSigTimeoutTime_TCM" SG_ 514 R_DIFF_TRQ_RQ 0;
BA_ "GenSigTimeoutTime_AGSM" SG_ 514 Rear_Diff_BSM_RQ 0;
BA_ "GenSigTimeoutTime_BSM" SG_ 514 Rear_Diff_BSM_RQ 0;
BA_ "GenSigTimeoutTime_CADM" SG_ 514 Rear_Diff_BSM_RQ 0;
BA_ "GenSigTimeoutTime_DMSM" SG_ 514 Rear_Diff_BSM_RQ 0;
BA_ "GenSigTimeoutTime_ECM" SG_ 514 Rear_Diff_BSM_RQ 0;
BA_ "GenSigTimeoutTime_GNMM" SG_ 514 Rear_Diff_BSM_RQ 0;
BA_ "GenSigTimeoutTime_HCP" SG_ 514 Rear_Diff_BSM_RQ 0;
BA_ "GenSigTimeoutTime_IPC" SG_ 514 Rear_Diff_BSM_RQ 0;
BA_ "GenSigTimeoutTime_RFHM" SG_ 514 Rear_Diff_BSM_RQ 0;
BA_ "GenSigTimeoutTime_SGW" SG_ 514 Rear_Diff_BSM_RQ 0;
BA_ "GenSigTimeoutTime_TCM" SG_ 514 Rear_Diff_BSM_RQ 0;
BA_ "GenSigTimeoutTime_AGSM" SG_ 514 TrlrBrkRq 0;
BA_ "GenSigTimeoutTime_BSM" SG_ 514 TrlrBrkRq 0;
BA_ "GenSigTimeoutTime_CADM" SG_ 514 TrlrBrkRq 0;
BA_ "GenSigTimeoutTime_DMSM" SG_ 514 TrlrBrkRq 0;
BA_ "GenSigTimeoutTime_DTCM" SG_ 514 TrlrBrkRq 0;
BA_ "GenSigTimeoutTime_ECM" SG_ 514 TrlrBrkRq 0;
BA_ "GenSigTimeoutTime_EVCU2" SG_ 514 TrlrBrkRq 0;
BA_ "GenSigTimeoutTime_GNMM" SG_ 514 TrlrBrkRq 0;
BA_ "GenSigTimeoutTime_HCP" SG_ 514 TrlrBrkRq 0;
BA_ "GenSigTimeoutTime_IPC" SG_ 514 TrlrBrkRq 0;
BA_ "GenSigTimeoutTime_RFHM" SG_ 514 TrlrBrkRq 0;
BA_ "GenSigTimeoutTime_SGW" SG_ 514 TrlrBrkRq 0;
BA_ "GenSigTimeoutTime_TCM" SG_ 514 TrlrBrkRq 0;
BA_ "GenSigTimeoutTime_AGSM" SG_ 257 CRC_BRAKE2_1 0;
BA_ "GenSigTimeoutTime_BCM" SG_ 257 CRC_BRAKE2_1 0;
BA_ "GenSigTimeoutTime_BSM" SG_ 257 CRC_BRAKE2_1 0;
BA_ "GenSigTimeoutTime_CADM" SG_ 257 CRC_BRAKE2_1 0;
BA_ "GenSigTimeoutTime_DMSM" SG_ 257 CRC_BRAKE2_1 0;
BA_ "GenSigTimeoutTime_ECM" SG_ 257 CRC_BRAKE2_1 0;
BA_ "GenSigTimeoutTime_EVCU2" SG_ 257 CRC_BRAKE2_1 0;
BA_ "GenSigTimeoutTime_GNMM" SG_ 257 CRC_BRAKE2_1 0;
BA_ "GenSigTimeoutTime_HCP" SG_ 257 CRC_BRAKE2_1 0;
BA_ "GenSigTimeoutTime_IPC" SG_ 257 CRC_BRAKE2_1 0;
BA_ "GenSigTimeoutTime_RFHM" SG_ 257 CRC_BRAKE2_1 0;
BA_ "GenSigTimeoutTime_SGW" SG_ 257 CRC_BRAKE2_1 0;
BA_ "GenSigTimeoutTime_TCM" SG_ 257 CRC_BRAKE2_1 0;
BA_ "GenSigStartValue" SG_ 257 Ft_RrAxleCoupling_TrqRq_B2 254;
BA_ "GenSigTimeoutTime_AGSM" SG_ 257 Ft_RrAxleCoupling_TrqRq_B2 0;
BA_ "GenSigTimeoutTime_BCM" SG_ 257 Ft_RrAxleCoupling_TrqRq_B2 0;
BA_ "GenSigTimeoutTime_BSM" SG_ 257 Ft_RrAxleCoupling_TrqRq_B2 0;
BA_ "GenSigTimeoutTime_CADM" SG_ 257 Ft_RrAxleCoupling_TrqRq_B2 0;
BA_ "GenSigTimeoutTime_DMSM" SG_ 257 Ft_RrAxleCoupling_TrqRq_B2 0;
BA_ "GenSigTimeoutTime_ECM" SG_ 257 Ft_RrAxleCoupling_TrqRq_B2 0;
BA_ "GenSigTimeoutTime_EVCU2" SG_ 257 Ft_RrAxleCoupling_TrqRq_B2 0;
BA_ "GenSigTimeoutTime_GNMM" SG_ 257 Ft_RrAxleCoupling_TrqRq_B2 0;
BA_ "GenSigTimeoutTime_HCP" SG_ 257 Ft_RrAxleCoupling_TrqRq_B2 0;
BA_ "GenSigTimeoutTime_IPC" SG_ 257 Ft_RrAxleCoupling_TrqRq_B2 0;
BA_ "GenSigTimeoutTime_RFHM" SG_ 257 Ft_RrAxleCoupling_TrqRq_B2 0;
BA_ "GenSigTimeoutTime_SGW" SG_ 257 Ft_RrAxleCoupling_TrqRq_B2 0;
BA_ "GenSigTimeoutTime_TCM" SG_ 257 Ft_RrAxleCoupling_TrqRq_B2 0;
BA_ "GenSigTimeoutTime_AGSM" SG_ 257 Ft_RrTrqCoupling_ModeRq_B2 0;
BA_ "GenSigTimeoutTime_BCM" SG_ 257 Ft_RrTrqCoupling_ModeRq_B2 0;
BA_ "GenSigTimeoutTime_BSM" SG_ 257 Ft_RrTrqCoupling_ModeRq_B2 0;
BA_ "GenSigTimeoutTime_CADM" SG_ 257 Ft_RrTrqCoupling_ModeRq_B2 0;
BA_ "GenSigTimeoutTime_DMSM" SG_ 257 Ft_RrTrqCoupling_ModeRq_B2 0;
BA_ "GenSigTimeoutTime_ECM" SG_ 257 Ft_RrTrqCoupling_ModeRq_B2 0;
BA_ "GenSigTimeoutTime_EVCU2" SG_ 257 Ft_RrTrqCoupling_ModeRq_B2 0;
BA_ "GenSigTimeoutTime_GNMM" SG_ 257 Ft_RrTrqCoupling_ModeRq_B2 0;
BA_ "GenSigTimeoutTime_HCP" SG_ 257 Ft_RrTrqCoupling_ModeRq_B2 0;
BA_ "GenSigTimeoutTime_IPC" SG_ 257 Ft_RrTrqCoupling_ModeRq_B2 0;
BA_ "GenSigTimeoutTime_RFHM" SG_ 257 Ft_RrTrqCoupling_ModeRq_B2 0;
BA_ "GenSigTimeoutTime_SGW" SG_ 257 Ft_RrTrqCoupling_ModeRq_B2 0;
BA_ "GenSigTimeoutTime_TCM" SG_ 257 Ft_RrTrqCoupling_ModeRq_B2 0;
BA_ "GenSigTimeoutTime_AGSM" SG_ 257 MessageCounter_BRAKE2_1 0;
BA_ "GenSigTimeoutTime_BCM" SG_ 257 MessageCounter_BRAKE2_1 0;
BA_ "GenSigTimeoutTime_BSM" SG_ 257 MessageCounter_BRAKE2_1 0;
BA_ "GenSigTimeoutTime_CADM" SG_ 257 MessageCounter_BRAKE2_1 0;
BA_ "GenSigTimeoutTime_DMSM" SG_ 257 MessageCounter_BRAKE2_1 0;
BA_ "GenSigTimeoutTime_ECM" SG_ 257 MessageCounter_BRAKE2_1 0;
BA_ "GenSigTimeoutTime_EVCU2" SG_ 257 MessageCounter_BRAKE2_1 0;
BA_ "GenSigTimeoutTime_GNMM" SG_ 257 MessageCounter_BRAKE2_1 0;
BA_ "GenSigTimeoutTime_HCP" SG_ 257 MessageCounter_BRAKE2_1 0;
BA_ "GenSigTimeoutTime_IPC" SG_ 257 MessageCounter_BRAKE2_1 0;
BA_ "GenSigTimeoutTime_RFHM" SG_ 257 MessageCounter_BRAKE2_1 0;
BA_ "GenSigTimeoutTime_SGW" SG_ 257 MessageCounter_BRAKE2_1 0;
BA_ "GenSigTimeoutTime_TCM" SG_ 257 MessageCounter_BRAKE2_1 0;
BA_ "GenSigTimeoutTime_AGSM" SG_ 524 Brake_OpStat_Sec 0;
BA_ "GenSigTimeoutTime_BCM" SG_ 524 Brake_OpStat_Sec 0;
BA_ "GenSigTimeoutTime_BSM" SG_ 524 Brake_OpStat_Sec 0;
BA_ "GenSigTimeoutTime_DMSM" SG_ 524 Brake_OpStat_Sec 0;
BA_ "GenSigTimeoutTime_DTCM" SG_ 524 Brake_OpStat_Sec 0;
BA_ "GenSigTimeoutTime_ECM" SG_ 524 Brake_OpStat_Sec 0;
BA_ "GenSigTimeoutTime_EVCU2" SG_ 524 Brake_OpStat_Sec 0;
BA_ "GenSigTimeoutTime_GNMM" SG_ 524 Brake_OpStat_Sec 0;
BA_ "GenSigTimeoutTime_HCP" SG_ 524 Brake_OpStat_Sec 0;
BA_ "GenSigTimeoutTime_IPC" SG_ 524 Brake_OpStat_Sec 0;
BA_ "GenSigTimeoutTime_RFHM" SG_ 524 Brake_OpStat_Sec 0;
BA_ "GenSigTimeoutTime_SGW" SG_ 524 Brake_OpStat_Sec 0;
BA_ "GenSigTimeoutTime_TCM" SG_ 524 Brake_OpStat_Sec 0;
BA_ "GenSigTimeoutTime_AGSM" SG_ 524 BSM2_OpStat 0;
BA_ "GenSigTimeoutTime_BCM" SG_ 524 BSM2_OpStat 0;
BA_ "GenSigTimeoutTime_DMSM" SG_ 524 BSM2_OpStat 0;
BA_ "GenSigTimeoutTime_DTCM" SG_ 524 BSM2_OpStat 0;
BA_ "GenSigTimeoutTime_ECM" SG_ 524 BSM2_OpStat 0;
BA_ "GenSigTimeoutTime_EVCU2" SG_ 524 BSM2_OpStat 0;
BA_ "GenSigTimeoutTime_GNMM" SG_ 524 BSM2_OpStat 0;
BA_ "GenSigTimeoutTime_HCP" SG_ 524 BSM2_OpStat 0;
BA_ "GenSigTimeoutTime_IPC" SG_ 524 BSM2_OpStat 0;
BA_ "GenSigTimeoutTime_RFHM" SG_ 524 BSM2_OpStat 0;
BA_ "GenSigTimeoutTime_SGW" SG_ 524 BSM2_OpStat 0;
BA_ "GenSigTimeoutTime_TCM" SG_ 524 BSM2_OpStat 0;
BA_ "GenSigTimeoutTime_AGSM" SG_ 524 CRC_BRAKE2_2 0;
BA_ "GenSigTimeoutTime_BCM" SG_ 524 CRC_BRAKE2_2 0;
BA_ "GenSigTimeoutTime_DMSM" SG_ 524 CRC_BRAKE2_2 0;
BA_ "GenSigTimeoutTime_DTCM" SG_ 524 CRC_BRAKE2_2 0;
BA_ "GenSigTimeoutTime_ECM" SG_ 524 CRC_BRAKE2_2 0;
BA_ "GenSigTimeoutTime_EVCU2" SG_ 524 CRC_BRAKE2_2 0;
BA_ "GenSigTimeoutTime_GNMM" SG_ 524 CRC_BRAKE2_2 0;
BA_ "GenSigTimeoutTime_HCP" SG_ 524 CRC_BRAKE2_2 0;
BA_ "GenSigTimeoutTime_IPC" SG_ 524 CRC_BRAKE2_2 0;
BA_ "GenSigTimeoutTime_RFHM" SG_ 524 CRC_BRAKE2_2 0;
BA_ "GenSigTimeoutTime_SGW" SG_ 524 CRC_BRAKE2_2 0;
BA_ "GenSigTimeoutTime_TCM" SG_ 524 CRC_BRAKE2_2 0;
BA_ "GenSigTimeoutTime_AGSM" SG_ 524 MessageCounter_BRAKE2_2 0;
BA_ "GenSigTimeoutTime_BCM" SG_ 524 MessageCounter_BRAKE2_2 0;
BA_ "GenSigTimeoutTime_DMSM" SG_ 524 MessageCounter_BRAKE2_2 0;
BA_ "GenSigTimeoutTime_DTCM" SG_ 524 MessageCounter_BRAKE2_2 0;
BA_ "GenSigTimeoutTime_ECM" SG_ 524 MessageCounter_BRAKE2_2 0;
BA_ "GenSigTimeoutTime_EVCU2" SG_ 524 MessageCounter_BRAKE2_2 0;
BA_ "GenSigTimeoutTime_GNMM" SG_ 524 MessageCounter_BRAKE2_2 0;
BA_ "GenSigTimeoutTime_HCP" SG_ 524 MessageCounter_BRAKE2_2 0;
BA_ "GenSigTimeoutTime_IPC" SG_ 524 MessageCounter_BRAKE2_2 0;
BA_ "GenSigTimeoutTime_RFHM" SG_ 524 MessageCounter_BRAKE2_2 0;
BA_ "GenSigTimeoutTime_SGW" SG_ 524 MessageCounter_BRAKE2_2 0;
BA_ "GenSigTimeoutTime_TCM" SG_ 524 MessageCounter_BRAKE2_2 0;
BA_ "GenSigStartValue" SG_ 524 VehicleStandStillSts_B2 1;
BA_ "GenSigTimeoutTime_AGSM" SG_ 524 VehicleStandStillSts_B2 0;
BA_ "GenSigTimeoutTime_BCM" SG_ 524 VehicleStandStillSts_B2 0;
BA_ "GenSigTimeoutTime_BSM" SG_ 524 VehicleStandStillSts_B2 0;
BA_ "GenSigTimeoutTime_DMSM" SG_ 524 VehicleStandStillSts_B2 0;
BA_ "GenSigTimeoutTime_DTCM" SG_ 524 VehicleStandStillSts_B2 0;
BA_ "GenSigTimeoutTime_ECM" SG_ 524 VehicleStandStillSts_B2 0;
BA_ "GenSigTimeoutTime_EVCU2" SG_ 524 VehicleStandStillSts_B2 0;
BA_ "GenSigTimeoutTime_GNMM" SG_ 524 VehicleStandStillSts_B2 0;
BA_ "GenSigTimeoutTime_HCP" SG_ 524 VehicleStandStillSts_B2 0;
BA_ "GenSigTimeoutTime_IPC" SG_ 524 VehicleStandStillSts_B2 0;
BA_ "GenSigTimeoutTime_RFHM" SG_ 524 VehicleStandStillSts_B2 0;
BA_ "GenSigTimeoutTime_SGW" SG_ 524 VehicleStandStillSts_B2 0;
BA_ "GenSigTimeoutTime_TCM" SG_ 524 VehicleStandStillSts_B2 0;
BA_ "GenSigTimeoutTime_BCM" SG_ 2651930624 Digit_01 0;
BA_ "GenSigTimeoutTime_BCM" SG_ 2651930624 Digit_02 0;
BA_ "GenSigTimeoutTime_BCM" SG_ 2651930624 Digit_03 0;
BA_ "GenSigTimeoutTime_BCM" SG_ 2651930624 Digit_04 0;
BA_ "GenSigTimeoutTime_BCM" SG_ 2651930624 Digit_05 0;
BA_ "GenSigTimeoutTime_BCM" SG_ 2651930624 Digit_06 0;
BA_ "GenSigTimeoutTime_BCM" SG_ 2651930624 Digit_07 0;
BA_ "GenSigTimeoutTime_BCM" SG_ 2651930624 Digit_08 0;
BA_ "GenSigTimeoutTime_BCM" SG_ 2651930624 Digit_09 0;
BA_ "GenSigTimeoutTime_BCM" SG_ 2651930624 Digit_10 0;
BA_ "GenSigTimeoutTime_BCM" SG_ 2651930624 Digit_11 0;
BA_ "GenSigSendType" SG_ 2651930646 Digit_01_AGSM 1;
BA_ "GenSigTimeoutTime_AGSM" SG_ 2651930646 Digit_01_AGSM 0;
BA_ "GenSigTimeoutTime_BSM" SG_ 2651930646 Digit_01_AGSM 0;
BA_ "GenSigTimeoutTime_CADM" SG_ 2651930646 Digit_01_AGSM 0;
BA_ "GenSigTimeoutTime_DMSM" SG_ 2651930646 Digit_01_AGSM 0;
BA_ "GenSigTimeoutTime_DTCM" SG_ 2651930646 Digit_01_AGSM 0;
BA_ "GenSigTimeoutTime_ECM" SG_ 2651930646 Digit_01_AGSM 0;
BA_ "GenSigTimeoutTime_EVCU2" SG_ 2651930646 Digit_01_AGSM 0;
BA_ "GenSigTimeoutTime_GNMM" SG_ 2651930646 Digit_01_AGSM 0;
BA_ "GenSigTimeoutTime_HCP" SG_ 2651930646 Digit_01_AGSM 0;
BA_ "GenSigTimeoutTime_IPC" SG_ 2651930646 Digit_01_AGSM 0;
BA_ "GenSigTimeoutTime_RFHM" SG_ 2651930646 Digit_01_AGSM 0;
BA_ "GenSigTimeoutTime_SGW" SG_ 2651930646 Digit_01_AGSM 0;
BA_ "GenSigTimeoutTime_TCM" SG_ 2651930646 Digit_01_AGSM 0;
BA_ "GenSigTimeoutTime_AGSM" SG_ 2651930646 Digit_02_AGSM 0;
BA_ "GenSigTimeoutTime_BSM" SG_ 2651930646 Digit_02_AGSM 0;
BA_ "GenSigTimeoutTime_CADM" SG_ 2651930646 Digit_02_AGSM 0;
BA_ "GenSigTimeoutTime_DMSM" SG_ 2651930646 Digit_02_AGSM 0;
BA_ "GenSigTimeoutTime_DTCM" SG_ 2651930646 Digit_02_AGSM 0;
BA_ "GenSigTimeoutTime_ECM" SG_ 2651930646 Digit_02_AGSM 0;
BA_ "GenSigTimeoutTime_EVCU2" SG_ 2651930646 Digit_02_AGSM 0;
BA_ "GenSigTimeoutTime_GNMM" SG_ 2651930646 Digit_02_AGSM 0;
BA_ "GenSigTimeoutTime_HCP" SG_ 2651930646 Digit_02_AGSM 0;
BA_ "GenSigTimeoutTime_IPC" SG_ 2651930646 Digit_02_AGSM 0;
BA_ "GenSigTimeoutTime_RFHM" SG_ 2651930646 Digit_02_AGSM 0;
BA_ "GenSigTimeoutTime_SGW" SG_ 2651930646 Digit_02_AGSM 0;
BA_ "GenSigTimeoutTime_TCM" SG_ 2651930646 Digit_02_AGSM 0;
BA_ "GenSigTimeoutTime_AGSM" SG_ 2651930646 Digit_03_AGSM 0;
BA_ "GenSigTimeoutTime_BSM" SG_ 2651930646 Digit_03_AGSM 0;
BA_ "GenSigTimeoutTime_CADM" SG_ 2651930646 Digit_03_AGSM 0;
BA_ "GenSigTimeoutTime_DMSM" SG_ 2651930646 Digit_03_AGSM 0;
BA_ "GenSigTimeoutTime_DTCM" SG_ 2651930646 Digit_03_AGSM 0;
BA_ "GenSigTimeoutTime_ECM" SG_ 2651930646 Digit_03_AGSM 0;
BA_ "GenSigTimeoutTime_EVCU2" SG_ 2651930646 Digit_03_AGSM 0;
BA_ "GenSigTimeoutTime_GNMM" SG_ 2651930646 Digit_03_AGSM 0;
BA_ "GenSigTimeoutTime_HCP" SG_ 2651930646 Digit_03_AGSM 0;
BA_ "GenSigTimeoutTime_IPC" SG_ 2651930646 Digit_03_AGSM 0;
BA_ "GenSigTimeoutTime_RFHM" SG_ 2651930646 Digit_03_AGSM 0;
BA_ "GenSigTimeoutTime_SGW" SG_ 2651930646 Digit_03_AGSM 0;
BA_ "GenSigTimeoutTime_TCM" SG_ 2651930646 Digit_03_AGSM 0;
BA_ "GenSigTimeoutTime_AGSM" SG_ 2651930646 Digit_04_AGSM 0;
BA_ "GenSigTimeoutTime_BSM" SG_ 2651930646 Digit_04_AGSM 0;
BA_ "GenSigTimeoutTime_CADM" SG_ 2651930646 Digit_04_AGSM 0;
BA_ "GenSigTimeoutTime_DMSM" SG_ 2651930646 Digit_04_AGSM 0;
BA_ "GenSigTimeoutTime_DTCM" SG_ 2651930646 Digit_04_AGSM 0;
BA_ "GenSigTimeoutTime_ECM" SG_ 2651930646 Digit_04_AGSM 0;
BA_ "GenSigTimeoutTime_EVCU2" SG_ 2651930646 Digit_04_AGSM 0;
BA_ "GenSigTimeoutTime_GNMM" SG_ 2651930646 Digit_04_AGSM 0;
BA_ "GenSigTimeoutTime_HCP" SG_ 2651930646 Digit_04_AGSM 0;
BA_ "GenSigTimeoutTime_IPC" SG_ 2651930646 Digit_04_AGSM 0;
BA_ "GenSigTimeoutTime_RFHM" SG_ 2651930646 Digit_04_AGSM 0;
BA_ "GenSigTimeoutTime_SGW" SG_ 2651930646 Digit_04_AGSM 0;
BA_ "GenSigTimeoutTime_TCM" SG_ 2651930646 Digit_04_AGSM 0;
BA_ "GenSigTimeoutTime_AGSM" SG_ 2651930646 Digit_05_AGSM 0;
BA_ "GenSigTimeoutTime_BSM" SG_ 2651930646 Digit_05_AGSM 0;
BA_ "GenSigTimeoutTime_CADM" SG_ 2651930646 Digit_05_AGSM 0;
BA_ "GenSigTimeoutTime_DMSM" SG_ 2651930646 Digit_05_AGSM 0;
BA_ "GenSigTimeoutTime_DTCM" SG_ 2651930646 Digit_05_AGSM 0;
BA_ "GenSigTimeoutTime_ECM" SG_ 2651930646 Digit_05_AGSM 0;
BA_ "GenSigTimeoutTime_EVCU2" SG_ 2651930646 Digit_05_AGSM 0;
BA_ "GenSigTimeoutTime_GNMM" SG_ 2651930646 Digit_05_AGSM 0;
BA_ "GenSigTimeoutTime_HCP" SG_ 2651930646 Digit_05_AGSM 0;
BA_ "GenSigTimeoutTime_IPC" SG_ 2651930646 Digit_05_AGSM 0;
BA_ "GenSigTimeoutTime_RFHM" SG_ 2651930646 Digit_05_AGSM 0;
BA_ "GenSigTimeoutTime_SGW" SG_ 2651930646 Digit_05_AGSM 0;
BA_ "GenSigTimeoutTime_TCM" SG_ 2651930646 Digit_05_AGSM 0;
BA_ "GenSigTimeoutTime_AGSM" SG_ 2651930646 Digit_06_AGSM 0;
BA_ "GenSigTimeoutTime_BSM" SG_ 2651930646 Digit_06_AGSM 0;
BA_ "GenSigTimeoutTime_CADM" SG_ 2651930646 Digit_06_AGSM 0;
BA_ "GenSigTimeoutTime_DMSM" SG_ 2651930646 Digit_06_AGSM 0;
BA_ "GenSigTimeoutTime_DTCM" SG_ 2651930646 Digit_06_AGSM 0;
BA_ "GenSigTimeoutTime_ECM" SG_ 2651930646 Digit_06_AGSM 0;
BA_ "GenSigTimeoutTime_EVCU2" SG_ 2651930646 Digit_06_AGSM 0;
BA_ "GenSigTimeoutTime_GNMM" SG_ 2651930646 Digit_06_AGSM 0;
BA_ "GenSigTimeoutTime_HCP" SG_ 2651930646 Digit_06_AGSM 0;
BA_ "GenSigTimeoutTime_IPC" SG_ 2651930646 Digit_06_AGSM 0;
BA_ "GenSigTimeoutTime_RFHM" SG_ 2651930646 Digit_06_AGSM 0;
BA_ "GenSigTimeoutTime_SGW" SG_ 2651930646 Digit_06_AGSM 0;
BA_ "GenSigTimeoutTime_TCM" SG_ 2651930646 Digit_06_AGSM 0;
BA_ "GenSigTimeoutTime_AGSM" SG_ 2651930646 Digit_07_AGSM 0;
BA_ "GenSigTimeoutTime_BSM" SG_ 2651930646 Digit_07_AGSM 0;
BA_ "GenSigTimeoutTime_CADM" SG_ 2651930646 Digit_07_AGSM 0;
BA_ "GenSigTimeoutTime_DMSM" SG_ 2651930646 Digit_07_AGSM 0;
BA_ "GenSigTimeoutTime_DTCM" SG_ 2651930646 Digit_07_AGSM 0;
BA_ "GenSigTimeoutTime_ECM" SG_ 2651930646 Digit_07_AGSM 0;
BA_ "GenSigTimeoutTime_EVCU2" SG_ 2651930646 Digit_07_AGSM 0;
BA_ "GenSigTimeoutTime_GNMM" SG_ 2651930646 Digit_07_AGSM 0;
BA_ "GenSigTimeoutTime_HCP" SG_ 2651930646 Digit_07_AGSM 0;
BA_ "GenSigTimeoutTime_IPC" SG_ 2651930646 Digit_07_AGSM 0;
BA_ "GenSigTimeoutTime_RFHM" SG_ 2651930646 Digit_07_AGSM 0;
BA_ "GenSigTimeoutTime_SGW" SG_ 2651930646 Digit_07_AGSM 0;
BA_ "GenSigTimeoutTime_TCM" SG_ 2651930646 Digit_07_AGSM 0;
BA_ "GenSigTimeoutTime_AGSM" SG_ 2651930646 Digit_08_AGSM 0;
BA_ "GenSigTimeoutTime_BSM" SG_ 2651930646 Digit_08_AGSM 0;
BA_ "GenSigTimeoutTime_CADM" SG_ 2651930646 Digit_08_AGSM 0;
BA_ "GenSigTimeoutTime_DMSM" SG_ 2651930646 Digit_08_AGSM 0;
BA_ "GenSigTimeoutTime_DTCM" SG_ 2651930646 Digit_08_AGSM 0;
BA_ "GenSigTimeoutTime_ECM" SG_ 2651930646 Digit_08_AGSM 0;
BA_ "GenSigTimeoutTime_EVCU2" SG_ 2651930646 Digit_08_AGSM 0;
BA_ "GenSigTimeoutTime_GNMM" SG_ 2651930646 Digit_08_AGSM 0;
BA_ "GenSigTimeoutTime_HCP" SG_ 2651930646 Digit_08_AGSM 0;
BA_ "GenSigTimeoutTime_IPC" SG_ 2651930646 Digit_08_AGSM 0;
BA_ "GenSigTimeoutTime_RFHM" SG_ 2651930646 Digit_08_AGSM 0;
BA_ "GenSigTimeoutTime_SGW" SG_ 2651930646 Digit_08_AGSM 0;
BA_ "GenSigTimeoutTime_TCM" SG_ 2651930646 Digit_08_AGSM 0;
BA_ "GenSigTimeoutTime_AGSM" SG_ 2651930646 Digit_09_AGSM 0;
BA_ "GenSigTimeoutTime_BSM" SG_ 2651930646 Digit_09_AGSM 0;
BA_ "GenSigTimeoutTime_CADM" SG_ 2651930646 Digit_09_AGSM 0;
BA_ "GenSigTimeoutTime_DMSM" SG_ 2651930646 Digit_09_AGSM 0;
BA_ "GenSigTimeoutTime_DTCM" SG_ 2651930646 Digit_09_AGSM 0;
BA_ "GenSigTimeoutTime_ECM" SG_ 2651930646 Digit_09_AGSM 0;
BA_ "GenSigTimeoutTime_EVCU2" SG_ 2651930646 Digit_09_AGSM 0;
BA_ "GenSigTimeoutTime_GNMM" SG_ 2651930646 Digit_09_AGSM 0;
BA_ "GenSigTimeoutTime_HCP" SG_ 2651930646 Digit_09_AGSM 0;
BA_ "GenSigTimeoutTime_IPC" SG_ 2651930646 Digit_09_AGSM 0;
BA_ "GenSigTimeoutTime_RFHM" SG_ 2651930646 Digit_09_AGSM 0;
BA_ "GenSigTimeoutTime_SGW" SG_ 2651930646 Digit_09_AGSM 0;
BA_ "GenSigTimeoutTime_TCM" SG_ 2651930646 Digit_09_AGSM 0;
BA_ "GenSigTimeoutTime_AGSM" SG_ 2651930646 Digit_10_AGSM 0;
BA_ "GenSigTimeoutTime_BSM" SG_ 2651930646 Digit_10_AGSM 0;
BA_ "GenSigTimeoutTime_CADM" SG_ 2651930646 Digit_10_AGSM 0;
BA_ "GenSigTimeoutTime_DMSM" SG_ 2651930646 Digit_10_AGSM 0;
BA_ "GenSigTimeoutTime_DTCM" SG_ 2651930646 Digit_10_AGSM 0;
BA_ "GenSigTimeoutTime_ECM" SG_ 2651930646 Digit_10_AGSM 0;
BA_ "GenSigTimeoutTime_EVCU2" SG_ 2651930646 Digit_10_AGSM 0;
BA_ "GenSigTimeoutTime_GNMM" SG_ 2651930646 Digit_10_AGSM 0;
BA_ "GenSigTimeoutTime_HCP" SG_ 2651930646 Digit_10_AGSM 0;
BA_ "GenSigTimeoutTime_IPC" SG_ 2651930646 Digit_10_AGSM 0;
BA_ "GenSigTimeoutTime_RFHM" SG_ 2651930646 Digit_10_AGSM 0;
BA_ "GenSigTimeoutTime_SGW" SG_ 2651930646 Digit_10_AGSM 0;
BA_ "GenSigTimeoutTime_TCM" SG_ 2651930646 Digit_10_AGSM 0;
BA_ "GenSigTimeoutTime_AGSM" SG_ 2651930646 Digit_11_AGSM 0;
BA_ "GenSigTimeoutTime_BSM" SG_ 2651930646 Digit_11_AGSM 0;
BA_ "GenSigTimeoutTime_CADM" SG_ 2651930646 Digit_11_AGSM 0;
BA_ "GenSigTimeoutTime_DMSM" SG_ 2651930646 Digit_11_AGSM 0;
BA_ "GenSigTimeoutTime_DTCM" SG_ 2651930646 Digit_11_AGSM 0;
BA_ "GenSigTimeoutTime_ECM" SG_ 2651930646 Digit_11_AGSM 0;
BA_ "GenSigTimeoutTime_EVCU2" SG_ 2651930646 Digit_11_AGSM 0;
BA_ "GenSigTimeoutTime_GNMM" SG_ 2651930646 Digit_11_AGSM 0;
BA_ "GenSigTimeoutTime_HCP" SG_ 2651930646 Digit_11_AGSM 0;
BA_ "GenSigTimeoutTime_IPC" SG_ 2651930646 Digit_11_AGSM 0;
BA_ "GenSigTimeoutTime_RFHM" SG_ 2651930646 Digit_11_AGSM 0;
BA_ "GenSigTimeoutTime_SGW" SG_ 2651930646 Digit_11_AGSM 0;
BA_ "GenSigTimeoutTime_TCM" SG_ 2651930646 Digit_11_AGSM 0;
BA_ "GenSigSendType" SG_ 2651930694 Digit_01_BPCM 1;
BA_ "GenSigTimeoutTime_AGSM" SG_ 2651930694 Digit_01_BPCM 0;
BA_ "GenSigTimeoutTime_BSM" SG_ 2651930694 Digit_01_BPCM 0;
BA_ "GenSigTimeoutTime_CADM" SG_ 2651930694 Digit_01_BPCM 0;
BA_ "GenSigTimeoutTime_DMSM" SG_ 2651930694 Digit_01_BPCM 0;
BA_ "GenSigTimeoutTime_DTCM" SG_ 2651930694 Digit_01_BPCM 0;
BA_ "GenSigTimeoutTime_ECM" SG_ 2651930694 Digit_01_BPCM 0;
BA_ "GenSigTimeoutTime_EVCU2" SG_ 2651930694 Digit_01_BPCM 0;
BA_ "GenSigTimeoutTime_GNMM" SG_ 2651930694 Digit_01_BPCM 0;
BA_ "GenSigTimeoutTime_HCP" SG_ 2651930694 Digit_01_BPCM 0;
BA_ "GenSigTimeoutTime_IPC" SG_ 2651930694 Digit_01_BPCM 0;
BA_ "GenSigTimeoutTime_RFHM" SG_ 2651930694 Digit_01_BPCM 0;
BA_ "GenSigTimeoutTime_SGW" SG_ 2651930694 Digit_01_BPCM 0;
BA_ "GenSigTimeoutTime_TCM" SG_ 2651930694 Digit_01_BPCM 0;
BA_ "GenSigTimeoutTime_AGSM" SG_ 2651930694 Digit_02_BPCM 0;
BA_ "GenSigTimeoutTime_BSM" SG_ 2651930694 Digit_02_BPCM 0;
BA_ "GenSigTimeoutTime_CADM" SG_ 2651930694 Digit_02_BPCM 0;
BA_ "GenSigTimeoutTime_DMSM" SG_ 2651930694 Digit_02_BPCM 0;
BA_ "GenSigTimeoutTime_DTCM" SG_ 2651930694 Digit_02_BPCM 0;
BA_ "GenSigTimeoutTime_ECM" SG_ 2651930694 Digit_02_BPCM 0;
BA_ "GenSigTimeoutTime_EVCU2" SG_ 2651930694 Digit_02_BPCM 0;
BA_ "GenSigTimeoutTime_GNMM" SG_ 2651930694 Digit_02_BPCM 0;
BA_ "GenSigTimeoutTime_HCP" SG_ 2651930694 Digit_02_BPCM 0;
BA_ "GenSigTimeoutTime_IPC" SG_ 2651930694 Digit_02_BPCM 0;
BA_ "GenSigTimeoutTime_RFHM" SG_ 2651930694 Digit_02_BPCM 0;
BA_ "GenSigTimeoutTime_SGW" SG_ 2651930694 Digit_02_BPCM 0;
BA_ "GenSigTimeoutTime_TCM" SG_ 2651930694 Digit_02_BPCM 0;
BA_ "GenSigTimeoutTime_AGSM" SG_ 2651930694 Digit_03_BPCM 0;
BA_ "GenSigTimeoutTime_BSM" SG_ 2651930694 Digit_03_BPCM 0;
BA_ "GenSigTimeoutTime_CADM" SG_ 2651930694 Digit_03_BPCM 0;
BA_ "GenSigTimeoutTime_DMSM" SG_ 2651930694 Digit_03_BPCM 0;
BA_ "GenSigTimeoutTime_DTCM" SG_ 2651930694 Digit_03_BPCM 0;
BA_ "GenSigTimeoutTime_ECM" SG_ 2651930694 Digit_03_BPCM 0;
BA_ "GenSigTimeoutTime_EVCU2" SG_ 2651930694 Digit_03_BPCM 0;
BA_ "GenSigTimeoutTime_GNMM" SG_ 2651930694 Digit_03_BPCM 0;
BA_ "GenSigTimeoutTime_HCP" SG_ 2651930694 Digit_03_BPCM 0;
BA_ "GenSigTimeoutTime_IPC" SG_ 2651930694 Digit_03_BPCM 0;
BA_ "GenSigTimeoutTime_RFHM" SG_ 2651930694 Digit_03_BPCM 0;
BA_ "GenSigTimeoutTime_SGW" SG_ 2651930694 Digit_03_BPCM 0;
BA_ "GenSigTimeoutTime_TCM" SG_ 2651930694 Digit_03_BPCM 0;
BA_ "GenSigTimeoutTime_AGSM" SG_ 2651930694 Digit_04_BPCM 0;
BA_ "GenSigTimeoutTime_BSM" SG_ 2651930694 Digit_04_BPCM 0;
BA_ "GenSigTimeoutTime_CADM" SG_ 2651930694 Digit_04_BPCM 0;
BA_ "GenSigTimeoutTime_DMSM" SG_ 2651930694 Digit_04_BPCM 0;
BA_ "GenSigTimeoutTime_DTCM" SG_ 2651930694 Digit_04_BPCM 0;
BA_ "GenSigTimeoutTime_ECM" SG_ 2651930694 Digit_04_BPCM 0;
BA_ "GenSigTimeoutTime_EVCU2" SG_ 2651930694 Digit_04_BPCM 0;
BA_ "GenSigTimeoutTime_GNMM" SG_ 2651930694 Digit_04_BPCM 0;
BA_ "GenSigTimeoutTime_HCP" SG_ 2651930694 Digit_04_BPCM 0;
BA_ "GenSigTimeoutTime_IPC" SG_ 2651930694 Digit_04_BPCM 0;
BA_ "GenSigTimeoutTime_RFHM" SG_ 2651930694 Digit_04_BPCM 0;
BA_ "GenSigTimeoutTime_SGW" SG_ 2651930694 Digit_04_BPCM 0;
BA_ "GenSigTimeoutTime_TCM" SG_ 2651930694 Digit_04_BPCM 0;
BA_ "GenSigTimeoutTime_AGSM" SG_ 2651930694 Digit_05_BPCM 0;
BA_ "GenSigTimeoutTime_BSM" SG_ 2651930694 Digit_05_BPCM 0;
BA_ "GenSigTimeoutTime_CADM" SG_ 2651930694 Digit_05_BPCM 0;
BA_ "GenSigTimeoutTime_DMSM" SG_ 2651930694 Digit_05_BPCM 0;
BA_ "GenSigTimeoutTime_DTCM" SG_ 2651930694 Digit_05_BPCM 0;
BA_ "GenSigTimeoutTime_ECM" SG_ 2651930694 Digit_05_BPCM 0;
BA_ "GenSigTimeoutTime_EVCU2" SG_ 2651930694 Digit_05_BPCM 0;
BA_ "GenSigTimeoutTime_GNMM" SG_ 2651930694 Digit_05_BPCM 0;
BA_ "GenSigTimeoutTime_HCP" SG_ 2651930694 Digit_05_BPCM 0;
BA_ "GenSigTimeoutTime_IPC" SG_ 2651930694 Digit_05_BPCM 0;
BA_ "GenSigTimeoutTime_RFHM" SG_ 2651930694 Digit_05_BPCM 0;
BA_ "GenSigTimeoutTime_SGW" SG_ 2651930694 Digit_05_BPCM 0;
BA_ "GenSigTimeoutTime_TCM" SG_ 2651930694 Digit_05_BPCM 0;
BA_ "GenSigTimeoutTime_AGSM" SG_ 2651930694 Digit_06_BPCM 0;
BA_ "GenSigTimeoutTime_BSM" SG_ 2651930694 Digit_06_BPCM 0;
BA_ "GenSigTimeoutTime_CADM" SG_ 2651930694 Digit_06_BPCM 0;
BA_ "GenSigTimeoutTime_DMSM" SG_ 2651930694 Digit_06_BPCM 0;
BA_ "GenSigTimeoutTime_DTCM" SG_ 2651930694 Digit_06_BPCM 0;
BA_ "GenSigTimeoutTime_ECM" SG_ 2651930694 Digit_06_BPCM 0;
BA_ "GenSigTimeoutTime_EVCU2" SG_ 2651930694 Digit_06_BPCM 0;
BA_ "GenSigTimeoutTime_GNMM" SG_ 2651930694 Digit_06_BPCM 0;
BA_ "GenSigTimeoutTime_HCP" SG_ 2651930694 Digit_06_BPCM 0;
BA_ "GenSigTimeoutTime_IPC" SG_ 2651930694 Digit_06_BPCM 0;
BA_ "GenSigTimeoutTime_RFHM" SG_ 2651930694 Digit_06_BPCM 0;
BA_ "GenSigTimeoutTime_SGW" SG_ 2651930694 Digit_06_BPCM 0;
BA_ "GenSigTimeoutTime_TCM" SG_ 2651930694 Digit_06_BPCM 0;
BA_ "GenSigTimeoutTime_AGSM" SG_ 2651930694 Digit_07_BPCM 0;
BA_ "GenSigTimeoutTime_BSM" SG_ 2651930694 Digit_07_BPCM 0;
BA_ "GenSigTimeoutTime_CADM" SG_ 2651930694 Digit_07_BPCM 0;
BA_ "GenSigTimeoutTime_DMSM" SG_ 2651930694 Digit_07_BPCM 0;
BA_ "GenSigTimeoutTime_DTCM" SG_ 2651930694 Digit_07_BPCM 0;
BA_ "GenSigTimeoutTime_ECM" SG_ 2651930694 Digit_07_BPCM 0;
BA_ "GenSigTimeoutTime_EVCU2" SG_ 2651930694 Digit_07_BPCM 0;
BA_ "GenSigTimeoutTime_GNMM" SG_ 2651930694 Digit_07_BPCM 0;
BA_ "GenSigTimeoutTime_HCP" SG_ 2651930694 Digit_07_BPCM 0;
BA_ "GenSigTimeoutTime_IPC" SG_ 2651930694 Digit_07_BPCM 0;
BA_ "GenSigTimeoutTime_RFHM" SG_ 2651930694 Digit_07_BPCM 0;
BA_ "GenSigTimeoutTime_SGW" SG_ 2651930694 Digit_07_BPCM 0;
BA_ "GenSigTimeoutTime_TCM" SG_ 2651930694 Digit_07_BPCM 0;
BA_ "GenSigTimeoutTime_AGSM" SG_ 2651930694 Digit_08_BPCM 0;
BA_ "GenSigTimeoutTime_BSM" SG_ 2651930694 Digit_08_BPCM 0;
BA_ "GenSigTimeoutTime_CADM" SG_ 2651930694 Digit_08_BPCM 0;
BA_ "GenSigTimeoutTime_DMSM" SG_ 2651930694 Digit_08_BPCM 0;
BA_ "GenSigTimeoutTime_DTCM" SG_ 2651930694 Digit_08_BPCM 0;
BA_ "GenSigTimeoutTime_ECM" SG_ 2651930694 Digit_08_BPCM 0;
BA_ "GenSigTimeoutTime_EVCU2" SG_ 2651930694 Digit_08_BPCM 0;
BA_ "GenSigTimeoutTime_GNMM" SG_ 2651930694 Digit_08_BPCM 0;
BA_ "GenSigTimeoutTime_HCP" SG_ 2651930694 Digit_08_BPCM 0;
BA_ "GenSigTimeoutTime_IPC" SG_ 2651930694 Digit_08_BPCM 0;
BA_ "GenSigTimeoutTime_RFHM" SG_ 2651930694 Digit_08_BPCM 0;
BA_ "GenSigTimeoutTime_SGW" SG_ 2651930694 Digit_08_BPCM 0;
BA_ "GenSigTimeoutTime_TCM" SG_ 2651930694 Digit_08_BPCM 0;
BA_ "GenSigTimeoutTime_AGSM" SG_ 2651930694 Digit_09_BPCM 0;
BA_ "GenSigTimeoutTime_BSM" SG_ 2651930694 Digit_09_BPCM 0;
BA_ "GenSigTimeoutTime_CADM" SG_ 2651930694 Digit_09_BPCM 0;
BA_ "GenSigTimeoutTime_DMSM" SG_ 2651930694 Digit_09_BPCM 0;
BA_ "GenSigTimeoutTime_DTCM" SG_ 2651930694 Digit_09_BPCM 0;
BA_ "GenSigTimeoutTime_ECM" SG_ 2651930694 Digit_09_BPCM 0;
BA_ "GenSigTimeoutTime_EVCU2" SG_ 2651930694 Digit_09_BPCM 0;
BA_ "GenSigTimeoutTime_GNMM" SG_ 2651930694 Digit_09_BPCM 0;
BA_ "GenSigTimeoutTime_HCP" SG_ 2651930694 Digit_09_BPCM 0;
BA_ "GenSigTimeoutTime_IPC" SG_ 2651930694 Digit_09_BPCM 0;
BA_ "GenSigTimeoutTime_RFHM" SG_ 2651930694 Digit_09_BPCM 0;
BA_ "GenSigTimeoutTime_SGW" SG_ 2651930694 Digit_09_BPCM 0;
BA_ "GenSigTimeoutTime_TCM" SG_ 2651930694 Digit_09_BPCM 0;
BA_ "GenSigTimeoutTime_AGSM" SG_ 2651930694 Digit_10_BPCM 0;
BA_ "GenSigTimeoutTime_BSM" SG_ 2651930694 Digit_10_BPCM 0;
BA_ "GenSigTimeoutTime_CADM" SG_ 2651930694 Digit_10_BPCM 0;
BA_ "GenSigTimeoutTime_DMSM" SG_ 2651930694 Digit_10_BPCM 0;
BA_ "GenSigTimeoutTime_DTCM" SG_ 2651930694 Digit_10_BPCM 0;
BA_ "GenSigTimeoutTime_ECM" SG_ 2651930694 Digit_10_BPCM 0;
BA_ "GenSigTimeoutTime_EVCU2" SG_ 2651930694 Digit_10_BPCM 0;
BA_ "GenSigTimeoutTime_GNMM" SG_ 2651930694 Digit_10_BPCM 0;
BA_ "GenSigTimeoutTime_HCP" SG_ 2651930694 Digit_10_BPCM 0;
BA_ "GenSigTimeoutTime_IPC" SG_ 2651930694 Digit_10_BPCM 0;
BA_ "GenSigTimeoutTime_RFHM" SG_ 2651930694 Digit_10_BPCM 0;
BA_ "GenSigTimeoutTime_SGW" SG_ 2651930694 Digit_10_BPCM 0;
BA_ "GenSigTimeoutTime_TCM" SG_ 2651930694 Digit_10_BPCM 0;
BA_ "GenSigTimeoutTime_AGSM" SG_ 2651930694 Digit_11_BPCM 0;
BA_ "GenSigTimeoutTime_BSM" SG_ 2651930694 Digit_11_BPCM 0;
BA_ "GenSigTimeoutTime_CADM" SG_ 2651930694 Digit_11_BPCM 0;
BA_ "GenSigTimeoutTime_DMSM" SG_ 2651930694 Digit_11_BPCM 0;
BA_ "GenSigTimeoutTime_DTCM" SG_ 2651930694 Digit_11_BPCM 0;
BA_ "GenSigTimeoutTime_ECM" SG_ 2651930694 Digit_11_BPCM 0;
BA_ "GenSigTimeoutTime_EVCU2" SG_ 2651930694 Digit_11_BPCM 0;
BA_ "GenSigTimeoutTime_GNMM" SG_ 2651930694 Digit_11_BPCM 0;
BA_ "GenSigTimeoutTime_HCP" SG_ 2651930694 Digit_11_BPCM 0;
BA_ "GenSigTimeoutTime_IPC" SG_ 2651930694 Digit_11_BPCM 0;
BA_ "GenSigTimeoutTime_RFHM" SG_ 2651930694 Digit_11_BPCM 0;
BA_ "GenSigTimeoutTime_SGW" SG_ 2651930694 Digit_11_BPCM 0;
BA_ "GenSigTimeoutTime_TCM" SG_ 2651930694 Digit_11_BPCM 0;
BA_ "GenSigSendType" SG_ 2651930630 Digit_01_BSM 1;
BA_ "GenSigTimeoutTime_AGSM" SG_ 2651930630 Digit_01_BSM 0;
BA_ "GenSigTimeoutTime_BSM" SG_ 2651930630 Digit_01_BSM 0;
BA_ "GenSigTimeoutTime_CADM" SG_ 2651930630 Digit_01_BSM 0;
BA_ "GenSigTimeoutTime_DMSM" SG_ 2651930630 Digit_01_BSM 0;
BA_ "GenSigTimeoutTime_DTCM" SG_ 2651930630 Digit_01_BSM 0;
BA_ "GenSigTimeoutTime_ECM" SG_ 2651930630 Digit_01_BSM 0;
BA_ "GenSigTimeoutTime_EVCU2" SG_ 2651930630 Digit_01_BSM 0;
BA_ "GenSigTimeoutTime_GNMM" SG_ 2651930630 Digit_01_BSM 0;
BA_ "GenSigTimeoutTime_HCP" SG_ 2651930630 Digit_01_BSM 0;
BA_ "GenSigTimeoutTime_IPC" SG_ 2651930630 Digit_01_BSM 0;
BA_ "GenSigTimeoutTime_RFHM" SG_ 2651930630 Digit_01_BSM 0;
BA_ "GenSigTimeoutTime_SGW" SG_ 2651930630 Digit_01_BSM 0;
BA_ "GenSigTimeoutTime_TCM" SG_ 2651930630 Digit_01_BSM 0;
BA_ "GenSigTimeoutTime_AGSM" SG_ 2651930630 Digit_02_BSM 0;
BA_ "GenSigTimeoutTime_BSM" SG_ 2651930630 Digit_02_BSM 0;
BA_ "GenSigTimeoutTime_CADM" SG_ 2651930630 Digit_02_BSM 0;
BA_ "GenSigTimeoutTime_DMSM" SG_ 2651930630 Digit_02_BSM 0;
BA_ "GenSigTimeoutTime_DTCM" SG_ 2651930630 Digit_02_BSM 0;
BA_ "GenSigTimeoutTime_ECM" SG_ 2651930630 Digit_02_BSM 0;
BA_ "GenSigTimeoutTime_EVCU2" SG_ 2651930630 Digit_02_BSM 0;
BA_ "GenSigTimeoutTime_GNMM" SG_ 2651930630 Digit_02_BSM 0;
BA_ "GenSigTimeoutTime_HCP" SG_ 2651930630 Digit_02_BSM 0;
BA_ "GenSigTimeoutTime_IPC" SG_ 2651930630 Digit_02_BSM 0;
BA_ "GenSigTimeoutTime_RFHM" SG_ 2651930630 Digit_02_BSM 0;
BA_ "GenSigTimeoutTime_SGW" SG_ 2651930630 Digit_02_BSM 0;
BA_ "GenSigTimeoutTime_TCM" SG_ 2651930630 Digit_02_BSM 0;
BA_ "GenSigTimeoutTime_AGSM" SG_ 2651930630 Digit_03_BSM 0;
BA_ "GenSigTimeoutTime_BSM" SG_ 2651930630 Digit_03_BSM 0;
BA_ "GenSigTimeoutTime_CADM" SG_ 2651930630 Digit_03_BSM 0;
BA_ "GenSigTimeoutTime_DMSM" SG_ 2651930630 Digit_03_BSM 0;
BA_ "GenSigTimeoutTime_DTCM" SG_ 2651930630 Digit_03_BSM 0;
BA_ "GenSigTimeoutTime_ECM" SG_ 2651930630 Digit_03_BSM 0;
BA_ "GenSigTimeoutTime_EVCU2" SG_ 2651930630 Digit_03_BSM 0;
BA_ "GenSigTimeoutTime_GNMM" SG_ 2651930630 Digit_03_BSM 0;
BA_ "GenSigTimeoutTime_HCP" SG_ 2651930630 Digit_03_BSM 0;
BA_ "GenSigTimeoutTime_IPC" SG_ 2651930630 Digit_03_BSM 0;
BA_ "GenSigTimeoutTime_RFHM" SG_ 2651930630 Digit_03_BSM 0;
BA_ "GenSigTimeoutTime_SGW" SG_ 2651930630 Digit_03_BSM 0;
BA_ "GenSigTimeoutTime_TCM" SG_ 2651930630 Digit_03_BSM 0;
BA_ "GenSigTimeoutTime_AGSM" SG_ 2651930630 Digit_04_BSM 0;
BA_ "GenSigTimeoutTime_BSM" SG_ 2651930630 Digit_04_BSM 0;
BA_ "GenSigTimeoutTime_CADM" SG_ 2651930630 Digit_04_BSM 0;
BA_ "GenSigTimeoutTime_DMSM" SG_ 2651930630 Digit_04_BSM 0;
BA_ "GenSigTimeoutTime_DTCM" SG_ 2651930630 Digit_04_BSM 0;
BA_ "GenSigTimeoutTime_ECM" SG_ 2651930630 Digit_04_BSM 0;
BA_ "GenSigTimeoutTime_EVCU2" SG_ 2651930630 Digit_04_BSM 0;
BA_ "GenSigTimeoutTime_GNMM" SG_ 2651930630 Digit_04_BSM 0;
BA_ "GenSigTimeoutTime_HCP" SG_ 2651930630 Digit_04_BSM 0;
BA_ "GenSigTimeoutTime_IPC" SG_ 2651930630 Digit_04_BSM 0;
BA_ "GenSigTimeoutTime_RFHM" SG_ 2651930630 Digit_04_BSM 0;
BA_ "GenSigTimeoutTime_SGW" SG_ 2651930630 Digit_04_BSM 0;
BA_ "GenSigTimeoutTime_TCM" SG_ 2651930630 Digit_04_BSM 0;
BA_ "GenSigTimeoutTime_AGSM" SG_ 2651930630 Digit_05_BSM 0;
BA_ "GenSigTimeoutTime_BSM" SG_ 2651930630 Digit_05_BSM 0;
BA_ "GenSigTimeoutTime_CADM" SG_ 2651930630 Digit_05_BSM 0;
BA_ "GenSigTimeoutTime_DMSM" SG_ 2651930630 Digit_05_BSM 0;
BA_ "GenSigTimeoutTime_DTCM" SG_ 2651930630 Digit_05_BSM 0;
BA_ "GenSigTimeoutTime_ECM" SG_ 2651930630 Digit_05_BSM 0;
BA_ "GenSigTimeoutTime_EVCU2" SG_ 2651930630 Digit_05_BSM 0;
BA_ "GenSigTimeoutTime_GNMM" SG_ 2651930630 Digit_05_BSM 0;
BA_ "GenSigTimeoutTime_HCP" SG_ 2651930630 Digit_05_BSM 0;
BA_ "GenSigTimeoutTime_IPC" SG_ 2651930630 Digit_05_BSM 0;
BA_ "GenSigTimeoutTime_RFHM" SG_ 2651930630 Digit_05_BSM 0;
BA_ "GenSigTimeoutTime_SGW" SG_ 2651930630 Digit_05_BSM 0;
BA_ "GenSigTimeoutTime_TCM" SG_ 2651930630 Digit_05_BSM 0;
BA_ "GenSigTimeoutTime_AGSM" SG_ 2651930630 Digit_06_BSM 0;
BA_ "GenSigTimeoutTime_BSM" SG_ 2651930630 Digit_06_BSM 0;
BA_ "GenSigTimeoutTime_CADM" SG_ 2651930630 Digit_06_BSM 0;
BA_ "GenSigTimeoutTime_DMSM" SG_ 2651930630 Digit_06_BSM 0;
BA_ "GenSigTimeoutTime_DTCM" SG_ 2651930630 Digit_06_BSM 0;
BA_ "GenSigTimeoutTime_ECM" SG_ 2651930630 Digit_06_BSM 0;
BA_ "GenSigTimeoutTime_EVCU2" SG_ 2651930630 Digit_06_BSM 0;
BA_ "GenSigTimeoutTime_GNMM" SG_ 2651930630 Digit_06_BSM 0;
BA_ "GenSigTimeoutTime_HCP" SG_ 2651930630 Digit_06_BSM 0;
BA_ "GenSigTimeoutTime_IPC" SG_ 2651930630 Digit_06_BSM 0;
BA_ "GenSigTimeoutTime_RFHM" SG_ 2651930630 Digit_06_BSM 0;
BA_ "GenSigTimeoutTime_SGW" SG_ 2651930630 Digit_06_BSM 0;
BA_ "GenSigTimeoutTime_TCM" SG_ 2651930630 Digit_06_BSM 0;
BA_ "GenSigTimeoutTime_AGSM" SG_ 2651930630 Digit_07_BSM 0;
BA_ "GenSigTimeoutTime_BSM" SG_ 2651930630 Digit_07_BSM 0;
BA_ "GenSigTimeoutTime_CADM" SG_ 2651930630 Digit_07_BSM 0;
BA_ "GenSigTimeoutTime_DMSM" SG_ 2651930630 Digit_07_BSM 0;
BA_ "GenSigTimeoutTime_DTCM" SG_ 2651930630 Digit_07_BSM 0;
BA_ "GenSigTimeoutTime_ECM" SG_ 2651930630 Digit_07_BSM 0;
BA_ "GenSigTimeoutTime_EVCU2" SG_ 2651930630 Digit_07_BSM 0;
BA_ "GenSigTimeoutTime_GNMM" SG_ 2651930630 Digit_07_BSM 0;
BA_ "GenSigTimeoutTime_HCP" SG_ 2651930630 Digit_07_BSM 0;
BA_ "GenSigTimeoutTime_IPC" SG_ 2651930630 Digit_07_BSM 0;
BA_ "GenSigTimeoutTime_RFHM" SG_ 2651930630 Digit_07_BSM 0;
BA_ "GenSigTimeoutTime_SGW" SG_ 2651930630 Digit_07_BSM 0;
BA_ "GenSigTimeoutTime_TCM" SG_ 2651930630 Digit_07_BSM 0;
BA_ "GenSigTimeoutTime_AGSM" SG_ 2651930630 Digit_08_BSM 0;
BA_ "GenSigTimeoutTime_BSM" SG_ 2651930630 Digit_08_BSM 0;
BA_ "GenSigTimeoutTime_CADM" SG_ 2651930630 Digit_08_BSM 0;
BA_ "GenSigTimeoutTime_DMSM" SG_ 2651930630 Digit_08_BSM 0;
BA_ "GenSigTimeoutTime_DTCM" SG_ 2651930630 Digit_08_BSM 0;
BA_ "GenSigTimeoutTime_ECM" SG_ 2651930630 Digit_08_BSM 0;
BA_ "GenSigTimeoutTime_EVCU2" SG_ 2651930630 Digit_08_BSM 0;
BA_ "GenSigTimeoutTime_GNMM" SG_ 2651930630 Digit_08_BSM 0;
BA_ "GenSigTimeoutTime_HCP" SG_ 2651930630 Digit_08_BSM 0;
BA_ "GenSigTimeoutTime_IPC" SG_ 2651930630 Digit_08_BSM 0;
BA_ "GenSigTimeoutTime_RFHM" SG_ 2651930630 Digit_08_BSM 0;
BA_ "GenSigTimeoutTime_SGW" SG_ 2651930630 Digit_08_BSM 0;
BA_ "GenSigTimeoutTime_TCM" SG_ 2651930630 Digit_08_BSM 0;
BA_ "GenSigTimeoutTime_AGSM" SG_ 2651930630 Digit_09_BSM 0;
BA_ "GenSigTimeoutTime_BSM" SG_ 2651930630 Digit_09_BSM 0;
BA_ "GenSigTimeoutTime_CADM" SG_ 2651930630 Digit_09_BSM 0;
BA_ "GenSigTimeoutTime_DMSM" SG_ 2651930630 Digit_09_BSM 0;
BA_ "GenSigTimeoutTime_DTCM" SG_ 2651930630 Digit_09_BSM 0;
BA_ "GenSigTimeoutTime_ECM" SG_ 2651930630 Digit_09_BSM 0;
BA_ "GenSigTimeoutTime_EVCU2" SG_ 2651930630 Digit_09_BSM 0;
BA_ "GenSigTimeoutTime_GNMM" SG_ 2651930630 Digit_09_BSM 0;
BA_ "GenSigTimeoutTime_HCP" SG_ 2651930630 Digit_09_BSM 0;
BA_ "GenSigTimeoutTime_IPC" SG_ 2651930630 Digit_09_BSM 0;
BA_ "GenSigTimeoutTime_RFHM" SG_ 2651930630 Digit_09_BSM 0;
BA_ "GenSigTimeoutTime_SGW" SG_ 2651930630 Digit_09_BSM 0;
BA_ "GenSigTimeoutTime_TCM" SG_ 2651930630 Digit_09_BSM 0;
BA_ "GenSigTimeoutTime_AGSM" SG_ 2651930630 Digit_10_BSM 0;
BA_ "GenSigTimeoutTime_BSM" SG_ 2651930630 Digit_10_BSM 0;
BA_ "GenSigTimeoutTime_CADM" SG_ 2651930630 Digit_10_BSM 0;
BA_ "GenSigTimeoutTime_DMSM" SG_ 2651930630 Digit_10_BSM 0;
BA_ "GenSigTimeoutTime_DTCM" SG_ 2651930630 Digit_10_BSM 0;
BA_ "GenSigTimeoutTime_ECM" SG_ 2651930630 Digit_10_BSM 0;
BA_ "GenSigTimeoutTime_EVCU2" SG_ 2651930630 Digit_10_BSM 0;
BA_ "GenSigTimeoutTime_GNMM" SG_ 2651930630 Digit_10_BSM 0;
BA_ "GenSigTimeoutTime_HCP" SG_ 2651930630 Digit_10_BSM 0;
BA_ "GenSigTimeoutTime_IPC" SG_ 2651930630 Digit_10_BSM 0;
BA_ "GenSigTimeoutTime_RFHM" SG_ 2651930630 Digit_10_BSM 0;
BA_ "GenSigTimeoutTime_SGW" SG_ 2651930630 Digit_10_BSM 0;
BA_ "GenSigTimeoutTime_TCM" SG_ 2651930630 Digit_10_BSM 0;
BA_ "GenSigTimeoutTime_AGSM" SG_ 2651930630 Digit_11_BSM 0;
BA_ "GenSigTimeoutTime_BSM" SG_ 2651930630 Digit_11_BSM 0;
BA_ "GenSigTimeoutTime_CADM" SG_ 2651930630 Digit_11_BSM 0;
BA_ "GenSigTimeoutTime_DMSM" SG_ 2651930630 Digit_11_BSM 0;
BA_ "GenSigTimeoutTime_DTCM" SG_ 2651930630 Digit_11_BSM 0;
BA_ "GenSigTimeoutTime_ECM" SG_ 2651930630 Digit_11_BSM 0;
BA_ "GenSigTimeoutTime_EVCU2" SG_ 2651930630 Digit_11_BSM 0;
BA_ "GenSigTimeoutTime_GNMM" SG_ 2651930630 Digit_11_BSM 0;
BA_ "GenSigTimeoutTime_HCP" SG_ 2651930630 Digit_11_BSM 0;
BA_ "GenSigTimeoutTime_IPC" SG_ 2651930630 Digit_11_BSM 0;
BA_ "GenSigTimeoutTime_RFHM" SG_ 2651930630 Digit_11_BSM 0;
BA_ "GenSigTimeoutTime_SGW" SG_ 2651930630 Digit_11_BSM 0;
BA_ "GenSigTimeoutTime_TCM" SG_ 2651930630 Digit_11_BSM 0;
BA_ "GenSigSendType" SG_ 2651930765 Digit_01_CADM 1;
BA_ "GenSigTimeoutTime_AGSM" SG_ 2651930765 Digit_01_CADM 0;
BA_ "GenSigTimeoutTime_BSM" SG_ 2651930765 Digit_01_CADM 0;
BA_ "GenSigTimeoutTime_CADM" SG_ 2651930765 Digit_01_CADM 0;
BA_ "GenSigTimeoutTime_DMSM" SG_ 2651930765 Digit_01_CADM 0;
BA_ "GenSigTimeoutTime_DTCM" SG_ 2651930765 Digit_01_CADM 0;
BA_ "GenSigTimeoutTime_ECM" SG_ 2651930765 Digit_01_CADM 0;
BA_ "GenSigTimeoutTime_EVCU2" SG_ 2651930765 Digit_01_CADM 0;
BA_ "GenSigTimeoutTime_GNMM" SG_ 2651930765 Digit_01_CADM 0;
BA_ "GenSigTimeoutTime_HCP" SG_ 2651930765 Digit_01_CADM 0;
BA_ "GenSigTimeoutTime_IPC" SG_ 2651930765 Digit_01_CADM 0;
BA_ "GenSigTimeoutTime_RFHM" SG_ 2651930765 Digit_01_CADM 0;
BA_ "GenSigTimeoutTime_SGW" SG_ 2651930765 Digit_01_CADM 0;
BA_ "GenSigTimeoutTime_TCM" SG_ 2651930765 Digit_01_CADM 0;
BA_ "GenSigTimeoutTime_AGSM" SG_ 2651930765 Digit_02_CADM 0;
BA_ "GenSigTimeoutTime_BSM" SG_ 2651930765 Digit_02_CADM 0;
BA_ "GenSigTimeoutTime_CADM" SG_ 2651930765 Digit_02_CADM 0;
BA_ "GenSigTimeoutTime_DMSM" SG_ 2651930765 Digit_02_CADM 0;
BA_ "GenSigTimeoutTime_DTCM" SG_ 2651930765 Digit_02_CADM 0;
BA_ "GenSigTimeoutTime_ECM" SG_ 2651930765 Digit_02_CADM 0;
BA_ "GenSigTimeoutTime_EVCU2" SG_ 2651930765 Digit_02_CADM 0;
BA_ "GenSigTimeoutTime_GNMM" SG_ 2651930765 Digit_02_CADM 0;
BA_ "GenSigTimeoutTime_HCP" SG_ 2651930765 Digit_02_CADM 0;
BA_ "GenSigTimeoutTime_IPC" SG_ 2651930765 Digit_02_CADM 0;
BA_ "GenSigTimeoutTime_RFHM" SG_ 2651930765 Digit_02_CADM 0;
BA_ "GenSigTimeoutTime_SGW" SG_ 2651930765 Digit_02_CADM 0;
BA_ "GenSigTimeoutTime_TCM" SG_ 2651930765 Digit_02_CADM 0;
BA_ "GenSigTimeoutTime_AGSM" SG_ 2651930765 Digit_03_CADM 0;
BA_ "GenSigTimeoutTime_BSM" SG_ 2651930765 Digit_03_CADM 0;
BA_ "GenSigTimeoutTime_CADM" SG_ 2651930765 Digit_03_CADM 0;
BA_ "GenSigTimeoutTime_DMSM" SG_ 2651930765 Digit_03_CADM 0;
BA_ "GenSigTimeoutTime_DTCM" SG_ 2651930765 Digit_03_CADM 0;
BA_ "GenSigTimeoutTime_ECM" SG_ 2651930765 Digit_03_CADM 0;
BA_ "GenSigTimeoutTime_EVCU2" SG_ 2651930765 Digit_03_CADM 0;
BA_ "GenSigTimeoutTime_GNMM" SG_ 2651930765 Digit_03_CADM 0;
BA_ "GenSigTimeoutTime_HCP" SG_ 2651930765 Digit_03_CADM 0;
BA_ "GenSigTimeoutTime_IPC" SG_ 2651930765 Digit_03_CADM 0;
BA_ "GenSigTimeoutTime_RFHM" SG_ 2651930765 Digit_03_CADM 0;
BA_ "GenSigTimeoutTime_SGW" SG_ 2651930765 Digit_03_CADM 0;
BA_ "GenSigTimeoutTime_TCM" SG_ 2651930765 Digit_03_CADM 0;
BA_ "GenSigTimeoutTime_AGSM" SG_ 2651930765 Digit_04_CADM 0;
BA_ "GenSigTimeoutTime_BSM" SG_ 2651930765 Digit_04_CADM 0;
BA_ "GenSigTimeoutTime_CADM" SG_ 2651930765 Digit_04_CADM 0;
BA_ "GenSigTimeoutTime_DMSM" SG_ 2651930765 Digit_04_CADM 0;
BA_ "GenSigTimeoutTime_DTCM" SG_ 2651930765 Digit_04_CADM 0;
BA_ "GenSigTimeoutTime_ECM" SG_ 2651930765 Digit_04_CADM 0;
BA_ "GenSigTimeoutTime_EVCU2" SG_ 2651930765 Digit_04_CADM 0;
BA_ "GenSigTimeoutTime_GNMM" SG_ 2651930765 Digit_04_CADM 0;
BA_ "GenSigTimeoutTime_HCP" SG_ 2651930765 Digit_04_CADM 0;
BA_ "GenSigTimeoutTime_IPC" SG_ 2651930765 Digit_04_CADM 0;
BA_ "GenSigTimeoutTime_RFHM" SG_ 2651930765 Digit_04_CADM 0;
BA_ "GenSigTimeoutTime_SGW" SG_ 2651930765 Digit_04_CADM 0;
BA_ "GenSigTimeoutTime_TCM" SG_ 2651930765 Digit_04_CADM 0;
BA_ "GenSigTimeoutTime_AGSM" SG_ 2651930765 Digit_05_CADM 0;
BA_ "GenSigTimeoutTime_BSM" SG_ 2651930765 Digit_05_CADM 0;
BA_ "GenSigTimeoutTime_CADM" SG_ 2651930765 Digit_05_CADM 0;
BA_ "GenSigTimeoutTime_DMSM" SG_ 2651930765 Digit_05_CADM 0;
BA_ "GenSigTimeoutTime_DTCM" SG_ 2651930765 Digit_05_CADM 0;
BA_ "GenSigTimeoutTime_ECM" SG_ 2651930765 Digit_05_CADM 0;
BA_ "GenSigTimeoutTime_EVCU2" SG_ 2651930765 Digit_05_CADM 0;
BA_ "GenSigTimeoutTime_GNMM" SG_ 2651930765 Digit_05_CADM 0;
BA_ "GenSigTimeoutTime_HCP" SG_ 2651930765 Digit_05_CADM 0;
BA_ "GenSigTimeoutTime_IPC" SG_ 2651930765 Digit_05_CADM 0;
BA_ "GenSigTimeoutTime_RFHM" SG_ 2651930765 Digit_05_CADM 0;
BA_ "GenSigTimeoutTime_SGW" SG_ 2651930765 Digit_05_CADM 0;
BA_ "GenSigTimeoutTime_TCM" SG_ 2651930765 Digit_05_CADM 0;
BA_ "GenSigTimeoutTime_AGSM" SG_ 2651930765 Digit_06_CADM 0;
BA_ "GenSigTimeoutTime_BSM" SG_ 2651930765 Digit_06_CADM 0;
BA_ "GenSigTimeoutTime_CADM" SG_ 2651930765 Digit_06_CADM 0;
BA_ "GenSigTimeoutTime_DMSM" SG_ 2651930765 Digit_06_CADM 0;
BA_ "GenSigTimeoutTime_DTCM" SG_ 2651930765 Digit_06_CADM 0;
BA_ "GenSigTimeoutTime_ECM" SG_ 2651930765 Digit_06_CADM 0;
BA_ "GenSigTimeoutTime_EVCU2" SG_ 2651930765 Digit_06_CADM 0;
BA_ "GenSigTimeoutTime_GNMM" SG_ 2651930765 Digit_06_CADM 0;
BA_ "GenSigTimeoutTime_HCP" SG_ 2651930765 Digit_06_CADM 0;
BA_ "GenSigTimeoutTime_IPC" SG_ 2651930765 Digit_06_CADM 0;
BA_ "GenSigTimeoutTime_RFHM" SG_ 2651930765 Digit_06_CADM 0;
BA_ "GenSigTimeoutTime_SGW" SG_ 2651930765 Digit_06_CADM 0;
BA_ "GenSigTimeoutTime_TCM" SG_ 2651930765 Digit_06_CADM 0;
BA_ "GenSigTimeoutTime_AGSM" SG_ 2651930765 Digit_07_CADM 0;
BA_ "GenSigTimeoutTime_BSM" SG_ 2651930765 Digit_07_CADM 0;
BA_ "GenSigTimeoutTime_CADM" SG_ 2651930765 Digit_07_CADM 0;
BA_ "GenSigTimeoutTime_DMSM" SG_ 2651930765 Digit_07_CADM 0;
BA_ "GenSigTimeoutTime_DTCM" SG_ 2651930765 Digit_07_CADM 0;
BA_ "GenSigTimeoutTime_ECM" SG_ 2651930765 Digit_07_CADM 0;
BA_ "GenSigTimeoutTime_EVCU2" SG_ 2651930765 Digit_07_CADM 0;
BA_ "GenSigTimeoutTime_GNMM" SG_ 2651930765 Digit_07_CADM 0;
BA_ "GenSigTimeoutTime_HCP" SG_ 2651930765 Digit_07_CADM 0;
BA_ "GenSigTimeoutTime_IPC" SG_ 2651930765 Digit_07_CADM 0;
BA_ "GenSigTimeoutTime_RFHM" SG_ 2651930765 Digit_07_CADM 0;
BA_ "GenSigTimeoutTime_SGW" SG_ 2651930765 Digit_07_CADM 0;
BA_ "GenSigTimeoutTime_TCM" SG_ 2651930765 Digit_07_CADM 0;
BA_ "GenSigTimeoutTime_AGSM" SG_ 2651930765 Digit_08_CADM 0;
BA_ "GenSigTimeoutTime_BSM" SG_ 2651930765 Digit_08_CADM 0;
BA_ "GenSigTimeoutTime_CADM" SG_ 2651930765 Digit_08_CADM 0;
BA_ "GenSigTimeoutTime_DMSM" SG_ 2651930765 Digit_08_CADM 0;
BA_ "GenSigTimeoutTime_DTCM" SG_ 2651930765 Digit_08_CADM 0;
BA_ "GenSigTimeoutTime_ECM" SG_ 2651930765 Digit_08_CADM 0;
BA_ "GenSigTimeoutTime_EVCU2" SG_ 2651930765 Digit_08_CADM 0;
BA_ "GenSigTimeoutTime_GNMM" SG_ 2651930765 Digit_08_CADM 0;
BA_ "GenSigTimeoutTime_HCP" SG_ 2651930765 Digit_08_CADM 0;
BA_ "GenSigTimeoutTime_IPC" SG_ 2651930765 Digit_08_CADM 0;
BA_ "GenSigTimeoutTime_RFHM" SG_ 2651930765 Digit_08_CADM 0;
BA_ "GenSigTimeoutTime_SGW" SG_ 2651930765 Digit_08_CADM 0;
BA_ "GenSigTimeoutTime_TCM" SG_ 2651930765 Digit_08_CADM 0;
BA_ "GenSigTimeoutTime_AGSM" SG_ 2651930765 Digit_09_CADM 0;
BA_ "GenSigTimeoutTime_BSM" SG_ 2651930765 Digit_09_CADM 0;
BA_ "GenSigTimeoutTime_CADM" SG_ 2651930765 Digit_09_CADM 0;
BA_ "GenSigTimeoutTime_DMSM" SG_ 2651930765 Digit_09_CADM 0;
BA_ "GenSigTimeoutTime_DTCM" SG_ 2651930765 Digit_09_CADM 0;
BA_ "GenSigTimeoutTime_ECM" SG_ 2651930765 Digit_09_CADM 0;
BA_ "GenSigTimeoutTime_EVCU2" SG_ 2651930765 Digit_09_CADM 0;
BA_ "GenSigTimeoutTime_GNMM" SG_ 2651930765 Digit_09_CADM 0;
BA_ "GenSigTimeoutTime_HCP" SG_ 2651930765 Digit_09_CADM 0;
BA_ "GenSigTimeoutTime_IPC" SG_ 2651930765 Digit_09_CADM 0;
BA_ "GenSigTimeoutTime_RFHM" SG_ 2651930765 Digit_09_CADM 0;
BA_ "GenSigTimeoutTime_SGW" SG_ 2651930765 Digit_09_CADM 0;
BA_ "GenSigTimeoutTime_TCM" SG_ 2651930765 Digit_09_CADM 0;
BA_ "GenSigTimeoutTime_AGSM" SG_ 2651930765 Digit_10_CADM 0;
BA_ "GenSigTimeoutTime_BSM" SG_ 2651930765 Digit_10_CADM 0;
BA_ "GenSigTimeoutTime_CADM" SG_ 2651930765 Digit_10_CADM 0;
BA_ "GenSigTimeoutTime_DMSM" SG_ 2651930765 Digit_10_CADM 0;
BA_ "GenSigTimeoutTime_DTCM" SG_ 2651930765 Digit_10_CADM 0;
BA_ "GenSigTimeoutTime_ECM" SG_ 2651930765 Digit_10_CADM 0;
BA_ "GenSigTimeoutTime_EVCU2" SG_ 2651930765 Digit_10_CADM 0;
BA_ "GenSigTimeoutTime_GNMM" SG_ 2651930765 Digit_10_CADM 0;
BA_ "GenSigTimeoutTime_HCP" SG_ 2651930765 Digit_10_CADM 0;
BA_ "GenSigTimeoutTime_IPC" SG_ 2651930765 Digit_10_CADM 0;
BA_ "GenSigTimeoutTime_RFHM" SG_ 2651930765 Digit_10_CADM 0;
BA_ "GenSigTimeoutTime_SGW" SG_ 2651930765 Digit_10_CADM 0;
BA_ "GenSigTimeoutTime_TCM" SG_ 2651930765 Digit_10_CADM 0;
BA_ "GenSigTimeoutTime_AGSM" SG_ 2651930765 Digit_11_CADM 0;
BA_ "GenSigTimeoutTime_BSM" SG_ 2651930765 Digit_11_CADM 0;
BA_ "GenSigTimeoutTime_CADM" SG_ 2651930765 Digit_11_CADM 0;
BA_ "GenSigTimeoutTime_DMSM" SG_ 2651930765 Digit_11_CADM 0;
BA_ "GenSigTimeoutTime_DTCM" SG_ 2651930765 Digit_11_CADM 0;
BA_ "GenSigTimeoutTime_ECM" SG_ 2651930765 Digit_11_CADM 0;
BA_ "GenSigTimeoutTime_EVCU2" SG_ 2651930765 Digit_11_CADM 0;
BA_ "GenSigTimeoutTime_GNMM" SG_ 2651930765 Digit_11_CADM 0;
BA_ "GenSigTimeoutTime_HCP" SG_ 2651930765 Digit_11_CADM 0;
BA_ "GenSigTimeoutTime_IPC" SG_ 2651930765 Digit_11_CADM 0;
BA_ "GenSigTimeoutTime_RFHM" SG_ 2651930765 Digit_11_CADM 0;
BA_ "GenSigTimeoutTime_SGW" SG_ 2651930765 Digit_11_CADM 0;
BA_ "GenSigTimeoutTime_TCM" SG_ 2651930765 Digit_11_CADM 0;
BA_ "GenSigSendType" SG_ 2651930776 Digit_01_DMSM 1;
BA_ "GenSigTimeoutTime_AGSM" SG_ 2651930776 Digit_01_DMSM 0;
BA_ "GenSigTimeoutTime_BSM" SG_ 2651930776 Digit_01_DMSM 0;
BA_ "GenSigTimeoutTime_CADM" SG_ 2651930776 Digit_01_DMSM 0;
BA_ "GenSigTimeoutTime_DMSM" SG_ 2651930776 Digit_01_DMSM 0;
BA_ "GenSigTimeoutTime_DTCM" SG_ 2651930776 Digit_01_DMSM 0;
BA_ "GenSigTimeoutTime_ECM" SG_ 2651930776 Digit_01_DMSM 0;
BA_ "GenSigTimeoutTime_EVCU2" SG_ 2651930776 Digit_01_DMSM 0;
BA_ "GenSigTimeoutTime_GNMM" SG_ 2651930776 Digit_01_DMSM 0;
BA_ "GenSigTimeoutTime_HCP" SG_ 2651930776 Digit_01_DMSM 0;
BA_ "GenSigTimeoutTime_IPC" SG_ 2651930776 Digit_01_DMSM 0;
BA_ "GenSigTimeoutTime_RFHM" SG_ 2651930776 Digit_01_DMSM 0;
BA_ "GenSigTimeoutTime_SGW" SG_ 2651930776 Digit_01_DMSM 0;
BA_ "GenSigTimeoutTime_TCM" SG_ 2651930776 Digit_01_DMSM 0;
BA_ "GenSigTimeoutTime_AGSM" SG_ 2651930776 Digit_02_DMSM 0;
BA_ "GenSigTimeoutTime_BSM" SG_ 2651930776 Digit_02_DMSM 0;
BA_ "GenSigTimeoutTime_CADM" SG_ 2651930776 Digit_02_DMSM 0;
BA_ "GenSigTimeoutTime_DMSM" SG_ 2651930776 Digit_02_DMSM 0;
BA_ "GenSigTimeoutTime_DTCM" SG_ 2651930776 Digit_02_DMSM 0;
BA_ "GenSigTimeoutTime_ECM" SG_ 2651930776 Digit_02_DMSM 0;
BA_ "GenSigTimeoutTime_EVCU2" SG_ 2651930776 Digit_02_DMSM 0;
BA_ "GenSigTimeoutTime_GNMM" SG_ 2651930776 Digit_02_DMSM 0;
BA_ "GenSigTimeoutTime_HCP" SG_ 2651930776 Digit_02_DMSM 0;
BA_ "GenSigTimeoutTime_IPC" SG_ 2651930776 Digit_02_DMSM 0;
BA_ "GenSigTimeoutTime_RFHM" SG_ 2651930776 Digit_02_DMSM 0;
BA_ "GenSigTimeoutTime_SGW" SG_ 2651930776 Digit_02_DMSM 0;
BA_ "GenSigTimeoutTime_TCM" SG_ 2651930776 Digit_02_DMSM 0;
BA_ "GenSigTimeoutTime_AGSM" SG_ 2651930776 Digit_03_DMSM 0;
BA_ "GenSigTimeoutTime_BSM" SG_ 2651930776 Digit_03_DMSM 0;
BA_ "GenSigTimeoutTime_CADM" SG_ 2651930776 Digit_03_DMSM 0;
BA_ "GenSigTimeoutTime_DMSM" SG_ 2651930776 Digit_03_DMSM 0;
BA_ "GenSigTimeoutTime_DTCM" SG_ 2651930776 Digit_03_DMSM 0;
BA_ "GenSigTimeoutTime_ECM" SG_ 2651930776 Digit_03_DMSM 0;
BA_ "GenSigTimeoutTime_EVCU2" SG_ 2651930776 Digit_03_DMSM 0;
BA_ "GenSigTimeoutTime_GNMM" SG_ 2651930776 Digit_03_DMSM 0;
BA_ "GenSigTimeoutTime_HCP" SG_ 2651930776 Digit_03_DMSM 0;
BA_ "GenSigTimeoutTime_IPC" SG_ 2651930776 Digit_03_DMSM 0;
BA_ "GenSigTimeoutTime_RFHM" SG_ 2651930776 Digit_03_DMSM 0;
BA_ "GenSigTimeoutTime_SGW" SG_ 2651930776 Digit_03_DMSM 0;
BA_ "GenSigTimeoutTime_TCM" SG_ 2651930776 Digit_03_DMSM 0;
BA_ "GenSigTimeoutTime_AGSM" SG_ 2651930776 Digit_04_DMSM 0;
BA_ "GenSigTimeoutTime_BSM" SG_ 2651930776 Digit_04_DMSM 0;
BA_ "GenSigTimeoutTime_CADM" SG_ 2651930776 Digit_04_DMSM 0;
BA_ "GenSigTimeoutTime_DMSM" SG_ 2651930776 Digit_04_DMSM 0;
BA_ "GenSigTimeoutTime_DTCM" SG_ 2651930776 Digit_04_DMSM 0;
BA_ "GenSigTimeoutTime_ECM" SG_ 2651930776 Digit_04_DMSM 0;
BA_ "GenSigTimeoutTime_EVCU2" SG_ 2651930776 Digit_04_DMSM 0;
BA_ "GenSigTimeoutTime_GNMM" SG_ 2651930776 Digit_04_DMSM 0;
BA_ "GenSigTimeoutTime_HCP" SG_ 2651930776 Digit_04_DMSM 0;
BA_ "GenSigTimeoutTime_IPC" SG_ 2651930776 Digit_04_DMSM 0;
BA_ "GenSigTimeoutTime_RFHM" SG_ 2651930776 Digit_04_DMSM 0;
BA_ "GenSigTimeoutTime_SGW" SG_ 2651930776 Digit_04_DMSM 0;
BA_ "GenSigTimeoutTime_TCM" SG_ 2651930776 Digit_04_DMSM 0;
BA_ "GenSigTimeoutTime_AGSM" SG_ 2651930776 Digit_05_DMSM 0;
BA_ "GenSigTimeoutTime_BSM" SG_ 2651930776 Digit_05_DMSM 0;
BA_ "GenSigTimeoutTime_CADM" SG_ 2651930776 Digit_05_DMSM 0;
BA_ "GenSigTimeoutTime_DMSM" SG_ 2651930776 Digit_05_DMSM 0;
BA_ "GenSigTimeoutTime_DTCM" SG_ 2651930776 Digit_05_DMSM 0;
BA_ "GenSigTimeoutTime_ECM" SG_ 2651930776 Digit_05_DMSM 0;
BA_ "GenSigTimeoutTime_EVCU2" SG_ 2651930776 Digit_05_DMSM 0;
BA_ "GenSigTimeoutTime_GNMM" SG_ 2651930776 Digit_05_DMSM 0;
BA_ "GenSigTimeoutTime_HCP" SG_ 2651930776 Digit_05_DMSM 0;
BA_ "GenSigTimeoutTime_IPC" SG_ 2651930776 Digit_05_DMSM 0;
BA_ "GenSigTimeoutTime_RFHM" SG_ 2651930776 Digit_05_DMSM 0;
BA_ "GenSigTimeoutTime_SGW" SG_ 2651930776 Digit_05_DMSM 0;
BA_ "GenSigTimeoutTime_TCM" SG_ 2651930776 Digit_05_DMSM 0;
BA_ "GenSigTimeoutTime_AGSM" SG_ 2651930776 Digit_06_DMSM 0;
BA_ "GenSigTimeoutTime_BSM" SG_ 2651930776 Digit_06_DMSM 0;
BA_ "GenSigTimeoutTime_CADM" SG_ 2651930776 Digit_06_DMSM 0;
BA_ "GenSigTimeoutTime_DMSM" SG_ 2651930776 Digit_06_DMSM 0;
BA_ "GenSigTimeoutTime_DTCM" SG_ 2651930776 Digit_06_DMSM 0;
BA_ "GenSigTimeoutTime_ECM" SG_ 2651930776 Digit_06_DMSM 0;
BA_ "GenSigTimeoutTime_EVCU2" SG_ 2651930776 Digit_06_DMSM 0;
BA_ "GenSigTimeoutTime_GNMM" SG_ 2651930776 Digit_06_DMSM 0;
BA_ "GenSigTimeoutTime_HCP" SG_ 2651930776 Digit_06_DMSM 0;
BA_ "GenSigTimeoutTime_IPC" SG_ 2651930776 Digit_06_DMSM 0;
BA_ "GenSigTimeoutTime_RFHM" SG_ 2651930776 Digit_06_DMSM 0;
BA_ "GenSigTimeoutTime_SGW" SG_ 2651930776 Digit_06_DMSM 0;
BA_ "GenSigTimeoutTime_TCM" SG_ 2651930776 Digit_06_DMSM 0;
BA_ "GenSigTimeoutTime_AGSM" SG_ 2651930776 Digit_07_DMSM 0;
BA_ "GenSigTimeoutTime_BSM" SG_ 2651930776 Digit_07_DMSM 0;
BA_ "GenSigTimeoutTime_CADM" SG_ 2651930776 Digit_07_DMSM 0;
BA_ "GenSigTimeoutTime_DMSM" SG_ 2651930776 Digit_07_DMSM 0;
BA_ "GenSigTimeoutTime_DTCM" SG_ 2651930776 Digit_07_DMSM 0;
BA_ "GenSigTimeoutTime_ECM" SG_ 2651930776 Digit_07_DMSM 0;
BA_ "GenSigTimeoutTime_EVCU2" SG_ 2651930776 Digit_07_DMSM 0;
BA_ "GenSigTimeoutTime_GNMM" SG_ 2651930776 Digit_07_DMSM 0;
BA_ "GenSigTimeoutTime_HCP" SG_ 2651930776 Digit_07_DMSM 0;
BA_ "GenSigTimeoutTime_IPC" SG_ 2651930776 Digit_07_DMSM 0;
BA_ "GenSigTimeoutTime_RFHM" SG_ 2651930776 Digit_07_DMSM 0;
BA_ "GenSigTimeoutTime_SGW" SG_ 2651930776 Digit_07_DMSM 0;
BA_ "GenSigTimeoutTime_TCM" SG_ 2651930776 Digit_07_DMSM 0;
BA_ "GenSigTimeoutTime_AGSM" SG_ 2651930776 Digit_08_DMSM 0;
BA_ "GenSigTimeoutTime_BSM" SG_ 2651930776 Digit_08_DMSM 0;
BA_ "GenSigTimeoutTime_CADM" SG_ 2651930776 Digit_08_DMSM 0;
BA_ "GenSigTimeoutTime_DMSM" SG_ 2651930776 Digit_08_DMSM 0;
BA_ "GenSigTimeoutTime_DTCM" SG_ 2651930776 Digit_08_DMSM 0;
BA_ "GenSigTimeoutTime_ECM" SG_ 2651930776 Digit_08_DMSM 0;
BA_ "GenSigTimeoutTime_EVCU2" SG_ 2651930776 Digit_08_DMSM 0;
BA_ "GenSigTimeoutTime_GNMM" SG_ 2651930776 Digit_08_DMSM 0;
BA_ "GenSigTimeoutTime_HCP" SG_ 2651930776 Digit_08_DMSM 0;
BA_ "GenSigTimeoutTime_IPC" SG_ 2651930776 Digit_08_DMSM 0;
BA_ "GenSigTimeoutTime_RFHM" SG_ 2651930776 Digit_08_DMSM 0;
BA_ "GenSigTimeoutTime_SGW" SG_ 2651930776 Digit_08_DMSM 0;
BA_ "GenSigTimeoutTime_TCM" SG_ 2651930776 Digit_08_DMSM 0;
BA_ "GenSigTimeoutTime_AGSM" SG_ 2651930776 Digit_09_DMSM 0;
BA_ "GenSigTimeoutTime_BSM" SG_ 2651930776 Digit_09_DMSM 0;
BA_ "GenSigTimeoutTime_CADM" SG_ 2651930776 Digit_09_DMSM 0;
BA_ "GenSigTimeoutTime_DMSM" SG_ 2651930776 Digit_09_DMSM 0;
BA_ "GenSigTimeoutTime_DTCM" SG_ 2651930776 Digit_09_DMSM 0;
BA_ "GenSigTimeoutTime_ECM" SG_ 2651930776 Digit_09_DMSM 0;
BA_ "GenSigTimeoutTime_EVCU2" SG_ 2651930776 Digit_09_DMSM 0;
BA_ "GenSigTimeoutTime_GNMM" SG_ 2651930776 Digit_09_DMSM 0;
BA_ "GenSigTimeoutTime_HCP" SG_ 2651930776 Digit_09_DMSM 0;
BA_ "GenSigTimeoutTime_IPC" SG_ 2651930776 Digit_09_DMSM 0;
BA_ "GenSigTimeoutTime_RFHM" SG_ 2651930776 Digit_09_DMSM 0;
BA_ "GenSigTimeoutTime_SGW" SG_ 2651930776 Digit_09_DMSM 0;
BA_ "GenSigTimeoutTime_TCM" SG_ 2651930776 Digit_09_DMSM 0;
BA_ "GenSigTimeoutTime_AGSM" SG_ 2651930776 Digit_10_DMSM 0;
BA_ "GenSigTimeoutTime_BSM" SG_ 2651930776 Digit_10_DMSM 0;
BA_ "GenSigTimeoutTime_CADM" SG_ 2651930776 Digit_10_DMSM 0;
BA_ "GenSigTimeoutTime_DMSM" SG_ 2651930776 Digit_10_DMSM 0;
BA_ "GenSigTimeoutTime_DTCM" SG_ 2651930776 Digit_10_DMSM 0;
BA_ "GenSigTimeoutTime_ECM" SG_ 2651930776 Digit_10_DMSM 0;
BA_ "GenSigTimeoutTime_EVCU2" SG_ 2651930776 Digit_10_DMSM 0;
BA_ "GenSigTimeoutTime_GNMM" SG_ 2651930776 Digit_10_DMSM 0;
BA_ "GenSigTimeoutTime_HCP" SG_ 2651930776 Digit_10_DMSM 0;
BA_ "GenSigTimeoutTime_IPC" SG_ 2651930776 Digit_10_DMSM 0;
BA_ "GenSigTimeoutTime_RFHM" SG_ 2651930776 Digit_10_DMSM 0;
BA_ "GenSigTimeoutTime_SGW" SG_ 2651930776 Digit_10_DMSM 0;
BA_ "GenSigTimeoutTime_TCM" SG_ 2651930776 Digit_10_DMSM 0;
BA_ "GenSigTimeoutTime_AGSM" SG_ 2651930776 Digit_11_DMSM 0;
BA_ "GenSigTimeoutTime_BSM" SG_ 2651930776 Digit_11_DMSM 0;
BA_ "GenSigTimeoutTime_CADM" SG_ 2651930776 Digit_11_DMSM 0;
BA_ "GenSigTimeoutTime_DMSM" SG_ 2651930776 Digit_11_DMSM 0;
BA_ "GenSigTimeoutTime_DTCM" SG_ 2651930776 Digit_11_DMSM 0;
BA_ "GenSigTimeoutTime_ECM" SG_ 2651930776 Digit_11_DMSM 0;
BA_ "GenSigTimeoutTime_EVCU2" SG_ 2651930776 Digit_11_DMSM 0;
BA_ "GenSigTimeoutTime_GNMM" SG_ 2651930776 Digit_11_DMSM 0;
BA_ "GenSigTimeoutTime_HCP" SG_ 2651930776 Digit_11_DMSM 0;
BA_ "GenSigTimeoutTime_IPC" SG_ 2651930776 Digit_11_DMSM 0;
BA_ "GenSigTimeoutTime_RFHM" SG_ 2651930776 Digit_11_DMSM 0;
BA_ "GenSigTimeoutTime_SGW" SG_ 2651930776 Digit_11_DMSM 0;
BA_ "GenSigTimeoutTime_TCM" SG_ 2651930776 Digit_11_DMSM 0;
BA_ "GenSigSendType" SG_ 2651930691 Digit_01_DTCM 1;
BA_ "GenSigTimeoutTime_AGSM" SG_ 2651930691 Digit_01_DTCM 0;
BA_ "GenSigTimeoutTime_BSM" SG_ 2651930691 Digit_01_DTCM 0;
BA_ "GenSigTimeoutTime_CADM" SG_ 2651930691 Digit_01_DTCM 0;
BA_ "GenSigTimeoutTime_DMSM" SG_ 2651930691 Digit_01_DTCM 0;
BA_ "GenSigTimeoutTime_DTCM" SG_ 2651930691 Digit_01_DTCM 0;
BA_ "GenSigTimeoutTime_ECM" SG_ 2651930691 Digit_01_DTCM 0;
BA_ "GenSigTimeoutTime_EVCU2" SG_ 2651930691 Digit_01_DTCM 0;
BA_ "GenSigTimeoutTime_GNMM" SG_ 2651930691 Digit_01_DTCM 0;
BA_ "GenSigTimeoutTime_HCP" SG_ 2651930691 Digit_01_DTCM 0;
BA_ "GenSigTimeoutTime_IPC" SG_ 2651930691 Digit_01_DTCM 0;
BA_ "GenSigTimeoutTime_RFHM" SG_ 2651930691 Digit_01_DTCM 0;
BA_ "GenSigTimeoutTime_SGW" SG_ 2651930691 Digit_01_DTCM 0;
BA_ "GenSigTimeoutTime_TCM" SG_ 2651930691 Digit_01_DTCM 0;
BA_ "GenSigTimeoutTime_AGSM" SG_ 2651930691 Digit_02_DTCM 0;
BA_ "GenSigTimeoutTime_BSM" SG_ 2651930691 Digit_02_DTCM 0;
BA_ "GenSigTimeoutTime_CADM" SG_ 2651930691 Digit_02_DTCM 0;
BA_ "GenSigTimeoutTime_DMSM" SG_ 2651930691 Digit_02_DTCM 0;
BA_ "GenSigTimeoutTime_DTCM" SG_ 2651930691 Digit_02_DTCM 0;
BA_ "GenSigTimeoutTime_ECM" SG_ 2651930691 Digit_02_DTCM 0;
BA_ "GenSigTimeoutTime_EVCU2" SG_ 2651930691 Digit_02_DTCM 0;
BA_ "GenSigTimeoutTime_GNMM" SG_ 2651930691 Digit_02_DTCM 0;
BA_ "GenSigTimeoutTime_HCP" SG_ 2651930691 Digit_02_DTCM 0;
BA_ "GenSigTimeoutTime_IPC" SG_ 2651930691 Digit_02_DTCM 0;
BA_ "GenSigTimeoutTime_RFHM" SG_ 2651930691 Digit_02_DTCM 0;
BA_ "GenSigTimeoutTime_SGW" SG_ 2651930691 Digit_02_DTCM 0;
BA_ "GenSigTimeoutTime_TCM" SG_ 2651930691 Digit_02_DTCM 0;
BA_ "GenSigTimeoutTime_AGSM" SG_ 2651930691 Digit_03_DTCM 0;
BA_ "GenSigTimeoutTime_BSM" SG_ 2651930691 Digit_03_DTCM 0;
BA_ "GenSigTimeoutTime_CADM" SG_ 2651930691 Digit_03_DTCM 0;
BA_ "GenSigTimeoutTime_DMSM" SG_ 2651930691 Digit_03_DTCM 0;
BA_ "GenSigTimeoutTime_DTCM" SG_ 2651930691 Digit_03_DTCM 0;
BA_ "GenSigTimeoutTime_ECM" SG_ 2651930691 Digit_03_DTCM 0;
BA_ "GenSigTimeoutTime_EVCU2" SG_ 2651930691 Digit_03_DTCM 0;
BA_ "GenSigTimeoutTime_GNMM" SG_ 2651930691 Digit_03_DTCM 0;
BA_ "GenSigTimeoutTime_HCP" SG_ 2651930691 Digit_03_DTCM 0;
BA_ "GenSigTimeoutTime_IPC" SG_ 2651930691 Digit_03_DTCM 0;
BA_ "GenSigTimeoutTime_RFHM" SG_ 2651930691 Digit_03_DTCM 0;
BA_ "GenSigTimeoutTime_SGW" SG_ 2651930691 Digit_03_DTCM 0;
BA_ "GenSigTimeoutTime_TCM" SG_ 2651930691 Digit_03_DTCM 0;
BA_ "GenSigTimeoutTime_AGSM" SG_ 2651930691 Digit_04_DTCM 0;
BA_ "GenSigTimeoutTime_BSM" SG_ 2651930691 Digit_04_DTCM 0;
BA_ "GenSigTimeoutTime_CADM" SG_ 2651930691 Digit_04_DTCM 0;
BA_ "GenSigTimeoutTime_DMSM" SG_ 2651930691 Digit_04_DTCM 0;
BA_ "GenSigTimeoutTime_DTCM" SG_ 2651930691 Digit_04_DTCM 0;
BA_ "GenSigTimeoutTime_ECM" SG_ 2651930691 Digit_04_DTCM 0;
BA_ "GenSigTimeoutTime_EVCU2" SG_ 2651930691 Digit_04_DTCM 0;
BA_ "GenSigTimeoutTime_GNMM" SG_ 2651930691 Digit_04_DTCM 0;
BA_ "GenSigTimeoutTime_HCP" SG_ 2651930691 Digit_04_DTCM 0;
BA_ "GenSigTimeoutTime_IPC" SG_ 2651930691 Digit_04_DTCM 0;
BA_ "GenSigTimeoutTime_RFHM" SG_ 2651930691 Digit_04_DTCM 0;
BA_ "GenSigTimeoutTime_SGW" SG_ 2651930691 Digit_04_DTCM 0;
BA_ "GenSigTimeoutTime_TCM" SG_ 2651930691 Digit_04_DTCM 0;
BA_ "GenSigTimeoutTime_AGSM" SG_ 2651930691 Digit_05_DTCM 0;
BA_ "GenSigTimeoutTime_BSM" SG_ 2651930691 Digit_05_DTCM 0;
BA_ "GenSigTimeoutTime_CADM" SG_ 2651930691 Digit_05_DTCM 0;
BA_ "GenSigTimeoutTime_DMSM" SG_ 2651930691 Digit_05_DTCM 0;
BA_ "GenSigTimeoutTime_DTCM" SG_ 2651930691 Digit_05_DTCM 0;
BA_ "GenSigTimeoutTime_ECM" SG_ 2651930691 Digit_05_DTCM 0;
BA_ "GenSigTimeoutTime_EVCU2" SG_ 2651930691 Digit_05_DTCM 0;
BA_ "GenSigTimeoutTime_GNMM" SG_ 2651930691 Digit_05_DTCM 0;
BA_ "GenSigTimeoutTime_HCP" SG_ 2651930691 Digit_05_DTCM 0;
BA_ "GenSigTimeoutTime_IPC" SG_ 2651930691 Digit_05_DTCM 0;
BA_ "GenSigTimeoutTime_RFHM" SG_ 2651930691 Digit_05_DTCM 0;
BA_ "GenSigTimeoutTime_SGW" SG_ 2651930691 Digit_05_DTCM 0;
BA_ "GenSigTimeoutTime_TCM" SG_ 2651930691 Digit_05_DTCM 0;
BA_ "GenSigTimeoutTime_AGSM" SG_ 2651930691 Digit_06_DTCM 0;
BA_ "GenSigTimeoutTime_BSM" SG_ 2651930691 Digit_06_DTCM 0;
BA_ "GenSigTimeoutTime_CADM" SG_ 2651930691 Digit_06_DTCM 0;
BA_ "GenSigTimeoutTime_DMSM" SG_ 2651930691 Digit_06_DTCM 0;
BA_ "GenSigTimeoutTime_DTCM" SG_ 2651930691 Digit_06_DTCM 0;
BA_ "GenSigTimeoutTime_ECM" SG_ 2651930691 Digit_06_DTCM 0;
BA_ "GenSigTimeoutTime_EVCU2" SG_ 2651930691 Digit_06_DTCM 0;
BA_ "GenSigTimeoutTime_GNMM" SG_ 2651930691 Digit_06_DTCM 0;
BA_ "GenSigTimeoutTime_HCP" SG_ 2651930691 Digit_06_DTCM 0;
BA_ "GenSigTimeoutTime_IPC" SG_ 2651930691 Digit_06_DTCM 0;
BA_ "GenSigTimeoutTime_RFHM" SG_ 2651930691 Digit_06_DTCM 0;
BA_ "GenSigTimeoutTime_SGW" SG_ 2651930691 Digit_06_DTCM 0;
BA_ "GenSigTimeoutTime_TCM" SG_ 2651930691 Digit_06_DTCM 0;
BA_ "GenSigTimeoutTime_AGSM" SG_ 2651930691 Digit_07_DTCM 0;
BA_ "GenSigTimeoutTime_BSM" SG_ 2651930691 Digit_07_DTCM 0;
BA_ "GenSigTimeoutTime_CADM" SG_ 2651930691 Digit_07_DTCM 0;
BA_ "GenSigTimeoutTime_DMSM" SG_ 2651930691 Digit_07_DTCM 0;
BA_ "GenSigTimeoutTime_DTCM" SG_ 2651930691 Digit_07_DTCM 0;
BA_ "GenSigTimeoutTime_ECM" SG_ 2651930691 Digit_07_DTCM 0;
BA_ "GenSigTimeoutTime_EVCU2" SG_ 2651930691 Digit_07_DTCM 0;
BA_ "GenSigTimeoutTime_GNMM" SG_ 2651930691 Digit_07_DTCM 0;
BA_ "GenSigTimeoutTime_HCP" SG_ 2651930691 Digit_07_DTCM 0;
BA_ "GenSigTimeoutTime_IPC" SG_ 2651930691 Digit_07_DTCM 0;
BA_ "GenSigTimeoutTime_RFHM" SG_ 2651930691 Digit_07_DTCM 0;
BA_ "GenSigTimeoutTime_SGW" SG_ 2651930691 Digit_07_DTCM 0;
BA_ "GenSigTimeoutTime_TCM" SG_ 2651930691 Digit_07_DTCM 0;
BA_ "GenSigTimeoutTime_AGSM" SG_ 2651930691 Digit_08_DTCM 0;
BA_ "GenSigTimeoutTime_BSM" SG_ 2651930691 Digit_08_DTCM 0;
BA_ "GenSigTimeoutTime_CADM" SG_ 2651930691 Digit_08_DTCM 0;
BA_ "GenSigTimeoutTime_DMSM" SG_ 2651930691 Digit_08_DTCM 0;
BA_ "GenSigTimeoutTime_DTCM" SG_ 2651930691 Digit_08_DTCM 0;
BA_ "GenSigTimeoutTime_ECM" SG_ 2651930691 Digit_08_DTCM 0;
BA_ "GenSigTimeoutTime_EVCU2" SG_ 2651930691 Digit_08_DTCM 0;
BA_ "GenSigTimeoutTime_GNMM" SG_ 2651930691 Digit_08_DTCM 0;
BA_ "GenSigTimeoutTime_HCP" SG_ 2651930691 Digit_08_DTCM 0;
BA_ "GenSigTimeoutTime_IPC" SG_ 2651930691 Digit_08_DTCM 0;
BA_ "GenSigTimeoutTime_RFHM" SG_ 2651930691 Digit_08_DTCM 0;
BA_ "GenSigTimeoutTime_SGW" SG_ 2651930691 Digit_08_DTCM 0;
BA_ "GenSigTimeoutTime_TCM" SG_ 2651930691 Digit_08_DTCM 0;
BA_ "GenSigTimeoutTime_AGSM" SG_ 2651930691 Digit_09_DTCM 0;
BA_ "GenSigTimeoutTime_BSM" SG_ 2651930691 Digit_09_DTCM 0;
BA_ "GenSigTimeoutTime_CADM" SG_ 2651930691 Digit_09_DTCM 0;
BA_ "GenSigTimeoutTime_DMSM" SG_ 2651930691 Digit_09_DTCM 0;
BA_ "GenSigTimeoutTime_DTCM" SG_ 2651930691 Digit_09_DTCM 0;
BA_ "GenSigTimeoutTime_ECM" SG_ 2651930691 Digit_09_DTCM 0;
BA_ "GenSigTimeoutTime_EVCU2" SG_ 2651930691 Digit_09_DTCM 0;
BA_ "GenSigTimeoutTime_GNMM" SG_ 2651930691 Digit_09_DTCM 0;
BA_ "GenSigTimeoutTime_HCP" SG_ 2651930691 Digit_09_DTCM 0;
BA_ "GenSigTimeoutTime_IPC" SG_ 2651930691 Digit_09_DTCM 0;
BA_ "GenSigTimeoutTime_RFHM" SG_ 2651930691 Digit_09_DTCM 0;
BA_ "GenSigTimeoutTime_SGW" SG_ 2651930691 Digit_09_DTCM 0;
BA_ "GenSigTimeoutTime_TCM" SG_ 2651930691 Digit_09_DTCM 0;
BA_ "GenSigTimeoutTime_AGSM" SG_ 2651930691 Digit_10_DTCM 0;
BA_ "GenSigTimeoutTime_BSM" SG_ 2651930691 Digit_10_DTCM 0;
BA_ "GenSigTimeoutTime_CADM" SG_ 2651930691 Digit_10_DTCM 0;
BA_ "GenSigTimeoutTime_DMSM" SG_ 2651930691 Digit_10_DTCM 0;
BA_ "GenSigTimeoutTime_DTCM" SG_ 2651930691 Digit_10_DTCM 0;
BA_ "GenSigTimeoutTime_ECM" SG_ 2651930691 Digit_10_DTCM 0;
BA_ "GenSigTimeoutTime_EVCU2" SG_ 2651930691 Digit_10_DTCM 0;
BA_ "GenSigTimeoutTime_GNMM" SG_ 2651930691 Digit_10_DTCM 0;
BA_ "GenSigTimeoutTime_HCP" SG_ 2651930691 Digit_10_DTCM 0;
BA_ "GenSigTimeoutTime_IPC" SG_ 2651930691 Digit_10_DTCM 0;
BA_ "GenSigTimeoutTime_RFHM" SG_ 2651930691 Digit_10_DTCM 0;
BA_ "GenSigTimeoutTime_SGW" SG_ 2651930691 Digit_10_DTCM 0;
BA_ "GenSigTimeoutTime_TCM" SG_ 2651930691 Digit_10_DTCM 0;
BA_ "GenSigTimeoutTime_AGSM" SG_ 2651930691 Digit_11_DTCM 0;
BA_ "GenSigTimeoutTime_BSM" SG_ 2651930691 Digit_11_DTCM 0;
BA_ "GenSigTimeoutTime_CADM" SG_ 2651930691 Digit_11_DTCM 0;
BA_ "GenSigTimeoutTime_DMSM" SG_ 2651930691 Digit_11_DTCM 0;
BA_ "GenSigTimeoutTime_DTCM" SG_ 2651930691 Digit_11_DTCM 0;
BA_ "GenSigTimeoutTime_ECM" SG_ 2651930691 Digit_11_DTCM 0;
BA_ "GenSigTimeoutTime_EVCU2" SG_ 2651930691 Digit_11_DTCM 0;
BA_ "GenSigTimeoutTime_GNMM" SG_ 2651930691 Digit_11_DTCM 0;
BA_ "GenSigTimeoutTime_HCP" SG_ 2651930691 Digit_11_DTCM 0;
BA_ "GenSigTimeoutTime_IPC" SG_ 2651930691 Digit_11_DTCM 0;
BA_ "GenSigTimeoutTime_RFHM" SG_ 2651930691 Digit_11_DTCM 0;
BA_ "GenSigTimeoutTime_SGW" SG_ 2651930691 Digit_11_DTCM 0;
BA_ "GenSigTimeoutTime_TCM" SG_ 2651930691 Digit_11_DTCM 0;
BA_ "GenSigSendType" SG_ 2651930625 Digit_01_ECM 1;
BA_ "GenSigTimeoutTime_AGSM" SG_ 2651930625 Digit_01_ECM 0;
BA_ "GenSigTimeoutTime_BSM" SG_ 2651930625 Digit_01_ECM 0;
BA_ "GenSigTimeoutTime_CADM" SG_ 2651930625 Digit_01_ECM 0;
BA_ "GenSigTimeoutTime_DMSM" SG_ 2651930625 Digit_01_ECM 0;
BA_ "GenSigTimeoutTime_DTCM" SG_ 2651930625 Digit_01_ECM 0;
BA_ "GenSigTimeoutTime_ECM" SG_ 2651930625 Digit_01_ECM 0;
BA_ "GenSigTimeoutTime_EVCU2" SG_ 2651930625 Digit_01_ECM 0;
BA_ "GenSigTimeoutTime_GNMM" SG_ 2651930625 Digit_01_ECM 0;
BA_ "GenSigTimeoutTime_HCP" SG_ 2651930625 Digit_01_ECM 0;
BA_ "GenSigTimeoutTime_IPC" SG_ 2651930625 Digit_01_ECM 0;
BA_ "GenSigTimeoutTime_RFHM" SG_ 2651930625 Digit_01_ECM 0;
BA_ "GenSigTimeoutTime_SGW" SG_ 2651930625 Digit_01_ECM 0;
BA_ "GenSigTimeoutTime_TCM" SG_ 2651930625 Digit_01_ECM 0;
BA_ "GenSigTimeoutTime_AGSM" SG_ 2651930625 Digit_02_ECM 0;
BA_ "GenSigTimeoutTime_BSM" SG_ 2651930625 Digit_02_ECM 0;
BA_ "GenSigTimeoutTime_CADM" SG_ 2651930625 Digit_02_ECM 0;
BA_ "GenSigTimeoutTime_DMSM" SG_ 2651930625 Digit_02_ECM 0;
BA_ "GenSigTimeoutTime_DTCM" SG_ 2651930625 Digit_02_ECM 0;
BA_ "GenSigTimeoutTime_ECM" SG_ 2651930625 Digit_02_ECM 0;
BA_ "GenSigTimeoutTime_EVCU2" SG_ 2651930625 Digit_02_ECM 0;
BA_ "GenSigTimeoutTime_GNMM" SG_ 2651930625 Digit_02_ECM 0;
BA_ "GenSigTimeoutTime_HCP" SG_ 2651930625 Digit_02_ECM 0;
BA_ "GenSigTimeoutTime_IPC" SG_ 2651930625 Digit_02_ECM 0;
BA_ "GenSigTimeoutTime_RFHM" SG_ 2651930625 Digit_02_ECM 0;
BA_ "GenSigTimeoutTime_SGW" SG_ 2651930625 Digit_02_ECM 0;
BA_ "GenSigTimeoutTime_TCM" SG_ 2651930625 Digit_02_ECM 0;
BA_ "GenSigTimeoutTime_AGSM" SG_ 2651930625 Digit_03_ECM 0;
BA_ "GenSigTimeoutTime_BSM" SG_ 2651930625 Digit_03_ECM 0;
BA_ "GenSigTimeoutTime_CADM" SG_ 2651930625 Digit_03_ECM 0;
BA_ "GenSigTimeoutTime_DMSM" SG_ 2651930625 Digit_03_ECM 0;
BA_ "GenSigTimeoutTime_DTCM" SG_ 2651930625 Digit_03_ECM 0;
BA_ "GenSigTimeoutTime_ECM" SG_ 2651930625 Digit_03_ECM 0;
BA_ "GenSigTimeoutTime_EVCU2" SG_ 2651930625 Digit_03_ECM 0;
BA_ "GenSigTimeoutTime_GNMM" SG_ 2651930625 Digit_03_ECM 0;
BA_ "GenSigTimeoutTime_HCP" SG_ 2651930625 Digit_03_ECM 0;
BA_ "GenSigTimeoutTime_IPC" SG_ 2651930625 Digit_03_ECM 0;
BA_ "GenSigTimeoutTime_RFHM" SG_ 2651930625 Digit_03_ECM 0;
BA_ "GenSigTimeoutTime_SGW" SG_ 2651930625 Digit_03_ECM 0;
BA_ "GenSigTimeoutTime_TCM" SG_ 2651930625 Digit_03_ECM 0;
BA_ "GenSigTimeoutTime_AGSM" SG_ 2651930625 Digit_04_ECM 0;
BA_ "GenSigTimeoutTime_BSM" SG_ 2651930625 Digit_04_ECM 0;
BA_ "GenSigTimeoutTime_CADM" SG_ 2651930625 Digit_04_ECM 0;
BA_ "GenSigTimeoutTime_DMSM" SG_ 2651930625 Digit_04_ECM 0;
BA_ "GenSigTimeoutTime_DTCM" SG_ 2651930625 Digit_04_ECM 0;
BA_ "GenSigTimeoutTime_ECM" SG_ 2651930625 Digit_04_ECM 0;
BA_ "GenSigTimeoutTime_EVCU2" SG_ 2651930625 Digit_04_ECM 0;
BA_ "GenSigTimeoutTime_GNMM" SG_ 2651930625 Digit_04_ECM 0;
BA_ "GenSigTimeoutTime_HCP" SG_ 2651930625 Digit_04_ECM 0;
BA_ "GenSigTimeoutTime_IPC" SG_ 2651930625 Digit_04_ECM 0;
BA_ "GenSigTimeoutTime_RFHM" SG_ 2651930625 Digit_04_ECM 0;
BA_ "GenSigTimeoutTime_SGW" SG_ 2651930625 Digit_04_ECM 0;
BA_ "GenSigTimeoutTime_TCM" SG_ 2651930625 Digit_04_ECM 0;
BA_ "GenSigTimeoutTime_AGSM" SG_ 2651930625 Digit_05_ECM 0;
BA_ "GenSigTimeoutTime_BSM" SG_ 2651930625 Digit_05_ECM 0;
BA_ "GenSigTimeoutTime_CADM" SG_ 2651930625 Digit_05_ECM 0;
BA_ "GenSigTimeoutTime_DMSM" SG_ 2651930625 Digit_05_ECM 0;
BA_ "GenSigTimeoutTime_DTCM" SG_ 2651930625 Digit_05_ECM 0;
BA_ "GenSigTimeoutTime_ECM" SG_ 2651930625 Digit_05_ECM 0;
BA_ "GenSigTimeoutTime_EVCU2" SG_ 2651930625 Digit_05_ECM 0;
BA_ "GenSigTimeoutTime_GNMM" SG_ 2651930625 Digit_05_ECM 0;
BA_ "GenSigTimeoutTime_HCP" SG_ 2651930625 Digit_05_ECM 0;
BA_ "GenSigTimeoutTime_IPC" SG_ 2651930625 Digit_05_ECM 0;
BA_ "GenSigTimeoutTime_RFHM" SG_ 2651930625 Digit_05_ECM 0;
BA_ "GenSigTimeoutTime_SGW" SG_ 2651930625 Digit_05_ECM 0;
BA_ "GenSigTimeoutTime_TCM" SG_ 2651930625 Digit_05_ECM 0;
BA_ "GenSigTimeoutTime_AGSM" SG_ 2651930625 Digit_06_ECM 0;
BA_ "GenSigTimeoutTime_BSM" SG_ 2651930625 Digit_06_ECM 0;
BA_ "GenSigTimeoutTime_CADM" SG_ 2651930625 Digit_06_ECM 0;
BA_ "GenSigTimeoutTime_DMSM" SG_ 2651930625 Digit_06_ECM 0;
BA_ "GenSigTimeoutTime_DTCM" SG_ 2651930625 Digit_06_ECM 0;
BA_ "GenSigTimeoutTime_ECM" SG_ 2651930625 Digit_06_ECM 0;
BA_ "GenSigTimeoutTime_EVCU2" SG_ 2651930625 Digit_06_ECM 0;
BA_ "GenSigTimeoutTime_GNMM" SG_ 2651930625 Digit_06_ECM 0;
BA_ "GenSigTimeoutTime_HCP" SG_ 2651930625 Digit_06_ECM 0;
BA_ "GenSigTimeoutTime_IPC" SG_ 2651930625 Digit_06_ECM 0;
BA_ "GenSigTimeoutTime_RFHM" SG_ 2651930625 Digit_06_ECM 0;
BA_ "GenSigTimeoutTime_SGW" SG_ 2651930625 Digit_06_ECM 0;
BA_ "GenSigTimeoutTime_TCM" SG_ 2651930625 Digit_06_ECM 0;
BA_ "GenSigTimeoutTime_AGSM" SG_ 2651930625 Digit_07_ECM 0;
BA_ "GenSigTimeoutTime_BSM" SG_ 2651930625 Digit_07_ECM 0;
BA_ "GenSigTimeoutTime_CADM" SG_ 2651930625 Digit_07_ECM 0;
BA_ "GenSigTimeoutTime_DMSM" SG_ 2651930625 Digit_07_ECM 0;
BA_ "GenSigTimeoutTime_DTCM" SG_ 2651930625 Digit_07_ECM 0;
BA_ "GenSigTimeoutTime_ECM" SG_ 2651930625 Digit_07_ECM 0;
BA_ "GenSigTimeoutTime_EVCU2" SG_ 2651930625 Digit_07_ECM 0;
BA_ "GenSigTimeoutTime_GNMM" SG_ 2651930625 Digit_07_ECM 0;
BA_ "GenSigTimeoutTime_HCP" SG_ 2651930625 Digit_07_ECM 0;
BA_ "GenSigTimeoutTime_IPC" SG_ 2651930625 Digit_07_ECM 0;
BA_ "GenSigTimeoutTime_RFHM" SG_ 2651930625 Digit_07_ECM 0;
BA_ "GenSigTimeoutTime_SGW" SG_ 2651930625 Digit_07_ECM 0;
BA_ "GenSigTimeoutTime_TCM" SG_ 2651930625 Digit_07_ECM 0;
BA_ "GenSigTimeoutTime_AGSM" SG_ 2651930625 Digit_08_ECM 0;
BA_ "GenSigTimeoutTime_BSM" SG_ 2651930625 Digit_08_ECM 0;
BA_ "GenSigTimeoutTime_CADM" SG_ 2651930625 Digit_08_ECM 0;
BA_ "GenSigTimeoutTime_DMSM" SG_ 2651930625 Digit_08_ECM 0;
BA_ "GenSigTimeoutTime_DTCM" SG_ 2651930625 Digit_08_ECM 0;
BA_ "GenSigTimeoutTime_ECM" SG_ 2651930625 Digit_08_ECM 0;
BA_ "GenSigTimeoutTime_EVCU2" SG_ 2651930625 Digit_08_ECM 0;
BA_ "GenSigTimeoutTime_GNMM" SG_ 2651930625 Digit_08_ECM 0;
BA_ "GenSigTimeoutTime_HCP" SG_ 2651930625 Digit_08_ECM 0;
BA_ "GenSigTimeoutTime_IPC" SG_ 2651930625 Digit_08_ECM 0;
BA_ "GenSigTimeoutTime_RFHM" SG_ 2651930625 Digit_08_ECM 0;
BA_ "GenSigTimeoutTime_SGW" SG_ 2651930625 Digit_08_ECM 0;
BA_ "GenSigTimeoutTime_TCM" SG_ 2651930625 Digit_08_ECM 0;
BA_ "GenSigTimeoutTime_AGSM" SG_ 2651930625 Digit_09_ECM 0;
BA_ "GenSigTimeoutTime_BSM" SG_ 2651930625 Digit_09_ECM 0;
BA_ "GenSigTimeoutTime_CADM" SG_ 2651930625 Digit_09_ECM 0;
BA_ "GenSigTimeoutTime_DMSM" SG_ 2651930625 Digit_09_ECM 0;
BA_ "GenSigTimeoutTime_DTCM" SG_ 2651930625 Digit_09_ECM 0;
BA_ "GenSigTimeoutTime_ECM" SG_ 2651930625 Digit_09_ECM 0;
BA_ "GenSigTimeoutTime_EVCU2" SG_ 2651930625 Digit_09_ECM 0;
BA_ "GenSigTimeoutTime_GNMM" SG_ 2651930625 Digit_09_ECM 0;
BA_ "GenSigTimeoutTime_HCP" SG_ 2651930625 Digit_09_ECM 0;
BA_ "GenSigTimeoutTime_IPC" SG_ 2651930625 Digit_09_ECM 0;
BA_ "GenSigTimeoutTime_RFHM" SG_ 2651930625 Digit_09_ECM 0;
BA_ "GenSigTimeoutTime_SGW" SG_ 2651930625 Digit_09_ECM 0;
BA_ "GenSigTimeoutTime_TCM" SG_ 2651930625 Digit_09_ECM 0;
BA_ "GenSigTimeoutTime_AGSM" SG_ 2651930625 Digit_10_ECM 0;
BA_ "GenSigTimeoutTime_BSM" SG_ 2651930625 Digit_10_ECM 0;
BA_ "GenSigTimeoutTime_CADM" SG_ 2651930625 Digit_10_ECM 0;
BA_ "GenSigTimeoutTime_DMSM" SG_ 2651930625 Digit_10_ECM 0;
BA_ "GenSigTimeoutTime_DTCM" SG_ 2651930625 Digit_10_ECM 0;
BA_ "GenSigTimeoutTime_ECM" SG_ 2651930625 Digit_10_ECM 0;
BA_ "GenSigTimeoutTime_EVCU2" SG_ 2651930625 Digit_10_ECM 0;
BA_ "GenSigTimeoutTime_GNMM" SG_ 2651930625 Digit_10_ECM 0;
BA_ "GenSigTimeoutTime_HCP" SG_ 2651930625 Digit_10_ECM 0;
BA_ "GenSigTimeoutTime_IPC" SG_ 2651930625 Digit_10_ECM 0;
BA_ "GenSigTimeoutTime_RFHM" SG_ 2651930625 Digit_10_ECM 0;
BA_ "GenSigTimeoutTime_SGW" SG_ 2651930625 Digit_10_ECM 0;
BA_ "GenSigTimeoutTime_TCM" SG_ 2651930625 Digit_10_ECM 0;
BA_ "GenSigTimeoutTime_AGSM" SG_ 2651930625 Digit_11_ECM 0;
BA_ "GenSigTimeoutTime_BSM" SG_ 2651930625 Digit_11_ECM 0;
BA_ "GenSigTimeoutTime_CADM" SG_ 2651930625 Digit_11_ECM 0;
BA_ "GenSigTimeoutTime_DMSM" SG_ 2651930625 Digit_11_ECM 0;
BA_ "GenSigTimeoutTime_DTCM" SG_ 2651930625 Digit_11_ECM 0;
BA_ "GenSigTimeoutTime_ECM" SG_ 2651930625 Digit_11_ECM 0;
BA_ "GenSigTimeoutTime_EVCU2" SG_ 2651930625 Digit_11_ECM 0;
BA_ "GenSigTimeoutTime_GNMM" SG_ 2651930625 Digit_11_ECM 0;
BA_ "GenSigTimeoutTime_HCP" SG_ 2651930625 Digit_11_ECM 0;
BA_ "GenSigTimeoutTime_IPC" SG_ 2651930625 Digit_11_ECM 0;
BA_ "GenSigTimeoutTime_RFHM" SG_ 2651930625 Digit_11_ECM 0;
BA_ "GenSigTimeoutTime_SGW" SG_ 2651930625 Digit_11_ECM 0;
BA_ "GenSigTimeoutTime_TCM" SG_ 2651930625 Digit_11_ECM 0;
VAL_ 258 ABSActive 0 "Not_active" 1 "Active";
VAL_ 258 AHH_Ready_Status 0 "Not_Ready" 1 "AHH_Ready to hold" 2 "HH_Active" 3 "EPB_Ready_to_hold" 5 "Hyd_Releasing_EPB_Not_Avail" 7 "SNA";
VAL_ 258 Brake_MaxRegen_Ready 0 "Not_Ready" 1 "Ready";
VAL_ 258 BrakeBoostPressure 2047 "SNA";
VAL_ 258 BrakeBoostStat 0 "INIT_Bst" 1 "Normal_Bst" 2 "Limited_Bst" 3 "Shutdown_Bst" 4 "MOCO" 5 "Half_Sys_Bst" 6 "No_Bst" 15 "SNA";
VAL_ 258 BrakeInterventionSts 0 "No_active_brake_intervention" 1 "Active_brake_intervention";
VAL_ 258 BrakePedalPressure 2047 "SNA";
VAL_ 258 Brk_Stat 0 "IDLE" 1 "BRAKING" 2 "NDEF2" 3 "SNA";
VAL_ 258 BSM_ESASystemSts 0 "Not_Enabled" 1 "Pending" 2 "Pre_Active" 3 "Active" 4 "Locked" 5 "Temporarily_Not_Avail" 6 "Permanently_Not_Avail" 7 "SNA";
VAL_ 258 ESCActive 0 "Not_active" 1 "Active";
VAL_ 258 ESP_Sys_Stat 0 "ABSERR_DIAG" 1 "NORM" 2 "HALF" 3 "ABGAS";
VAL_ 258 HBAActive 0 "Not_Active" 1 "Active";
VAL_ 258 HillHolderActive 0 "Not_Active" 1 "Active";
VAL_ 258 ImpendingSkid 0 "Impending_skid_false" 1 "Impending_skid_true";
VAL_ 258 InternalError_BSM 0 "No_int_processing_error_detected" 1 "Int_processing_error_detected";
VAL_ 258 LatAcceleration_BSM 4095 "SNA";
VAL_ 258 LatAccelerationFailSts_BSM 0 "Fail_Not_Present" 1 "Fail_Present";
VAL_ 258 LongAcceleration_BSM 4095 "SNA";
VAL_ 258 LongAccelerationFailSts_BSM 0 "Fail_Not_Present" 1 "Fail_Present";
VAL_ 258 MuSplit 0 "MuSplitOFF" 1 "MuSplitON" 3 "SNA";
VAL_ 258 OverSteering 63 "SNA";
VAL_ 258 ParkingGearShiftReq_BSM 0 "Idle" 1 "P" 2 "R" 3 "N" 4 "D" 7 "SNA";
VAL_ 258 PrefillActive 0 "Not_Active" 1 "Active";
VAL_ 258 Slope 255 "SNA";
VAL_ 258 UnderSteering 63 "SNA";
VAL_ 258 VehicleSpeedVSOSig 8191 "SNA";
VAL_ 258 WheelRPM_FL 65535 "SNA";
VAL_ 258 WheelRPM_FR 65535 "SNA";
VAL_ 258 YawRate_BSM 4095 "SNA";
VAL_ 258 YawRateFailSts_BSM 0 "Fail_Not_Present" 1 "Fail_Present";
VAL_ 259 LatAccelerationOffset_BSM 255 "SNA";
VAL_ 259 LHF_FastPulseCounter 255 "SNA";
VAL_ 259 LHF_Spin 0 "Stand_Still" 1 "Forward" 2 "Backward" 3 "SNA";
VAL_ 259 LHF_WheelSensorFailSts 0 "Fail_Not_Present" 1 "Fail_Present";
VAL_ 259 LHFWheelSpeed 8191 "SNA";
VAL_ 259 LHR_FastPulseCounter 255 "SNA";
VAL_ 259 LHR_Spin 0 "Stand_Still" 1 "Forward" 2 "Backward" 3 "SNA";
VAL_ 259 LHR_WheelSensorFailSts 0 "Fail_Not_Present" 1 "Fail_Present";
VAL_ 259 LHRWheelSpeed 8191 "SNA";
VAL_ 259 LongAccelerationOffset_BSM 255 "SNA";
VAL_ 259 LwsAngleOffset_BSM 1023 "SNA";
VAL_ 259 RHF_FastPulseCounter 255 "SNA";
VAL_ 259 RHF_Spin 0 "Stand_Still" 1 "Forward" 2 "Backward" 3 "SNA";
VAL_ 259 RHF_WheelSensorFailSts 0 "Fail_Not_Present" 1 "Fail_Present";
VAL_ 259 RHFWheelSpeed 8191 "SNA";
VAL_ 259 RHR_FastPulseCounter 255 "SNA";
VAL_ 259 RHR_Spin 0 "Stand_Still" 1 "Forward" 2 "Backward" 3 "SNA";
VAL_ 259 RHR_WheelSensorFailSts 0 "Fail_Not_Present" 1 "Fail_Present";
VAL_ 259 RHRWheelSpeed 8191 "SNA";
VAL_ 609 ASRActive 0 "Not_active" 1 "Active";
VAL_ 609 BSM_LnchAbrtSts 0 "NOT" 1 "AwE" 2 "AwA" 3 "SNA";
VAL_ 609 BSM_LnchCtrl_SftBtn_SelectSts 0 "False" 1 "True";
VAL_ 609 BSM_LnchMode 0 "LAUNCH_OFF" 1 "LAUNCH_ON" 2 "LAUNCH_ACT" 3 "CNC" 4 "LAUNCH_ACT_RPM_PHASE" 7 "SNA";
VAL_ 609 ClampForce 0 "Initialization" 511 "SNA";
VAL_ 609 CODE_CLR_BSM 0 "Do_Nothing" 1 "Set_Incomplete";
VAL_ 609 EPB_HMI_Management 0 "No_Ind" 1 "Ind1" 2 "Ind2" 3 "Ind3" 4 "Ind4" 5 "Ind5" 6 "Ind6" 7 "Ind7" 8 "Ind8" 9 "Ind9" 10 "Ind10" 11 "Ind11" 12 "Ind12" 13 "Ind13" 14 "Ind14" 15 "Ind15" 16 "Ind16" 17 "Ind17" 18 "Ind18" 19 "Ind19" 20 "Ind20" 21 "Ind21" 22 "Ind22" 23 "Ind23" 24 "Ind24" 25 "Ind25" 26 "Ind26" 27 "Ind27" 28 "Ind28" 29 "Ind29" 30 "Ind30" 31 "Ind31";
VAL_ 609 EPBAutoAppSts 0 "AutoApply_Disable" 1 "AutoApply_Enable";
VAL_ 609 EPBMaintenanceSts 0 "Maintenance_Disabled" 1 "Maintenance_Enabled";
VAL_ 609 EPBSts 0 "Released" 1 "Applied" 2 "DynamicBrkESC" 3 "DynamicBrkEPB" 4 "Emergency_Braking" 5 "Applying" 6 "Maintenance_Mode" 7 "Assembly_Check" 8 "Inspection_Mode" 9 "Re_Clamping" 10 "Adjuste_Mode" 11 "Releasing" 12 "Fault_EPB_Released" 13 "Fault_EPB_Applied" 14 "Fault_Present" 15 "SNA";
VAL_ 609 EPBSwitchPosition 0 "No request" 1 "Release request" 2 "Apply request" 3 "Error";
VAL_ 609 EPBWarningLampReq 0 "OFF" 1 "CONT" 2 "BLINK" 3 "SNA";
VAL_ 609 ESC_OFF_Hrd_Sft_Button_sts 0 "STREET" 1 "SPORT" 2 "TRACK" 3 "OFF" 4 "SNOW" 5 "OFFROAD" 6 "DRAG" 7 "SNA";
VAL_ 609 LnchCtrl_DisPopupSts 0 "None" 1 "Press_Brake_to_Launch" 2 "Apply_Throttle_to_Launch" 3 "Vehicle_Not_At_Standstill_to_Launch" 4 "Vehicle_Not_On_Level_Ground_to_Launch" 5 "Straighten_Steering_Wheel_to_Launch" 6 "Shift to_Drive_for_Launch" 7 "Release_Brake_to_Launch" 8 "Launch_Control_Unavailable_New_Vehicle" 9 "Launch_Control_Unavailable_in_Valet_mode" 10 "Launch_Control_Unavailable_in_Neutral" 11 "Launch_Control_Unavailable_in_4LOW" 12 "Launch_Control_Unavailable_Vehicle_Speed_Too_High" 13 "Launch_Control_Unavailable_Engine_Off" 14 "Launch_Control_Unavailable_Brake_System_Fault" 15 "SNA";
VAL_ 609 MIL_OnRq_BSM 0 "False" 1 "True";
VAL_ 609 MSRActive 0 "Not_Active" 1 "Active";
VAL_ 609 RedLampReq 0 "Off" 1 "Fixed" 2 "Blinking" 3 "SNA";
VAL_ 609 REPRGD_PFC_CLR_BSM 0 "Do_Nothing" 1 "Set_Incomplete";
VAL_ 609 TravelDistance 255 "SNA";
VAL_ 1155 ABSFailSts 0 "Fail_Not_Present" 1 "Fail_Present";
VAL_ 1155 ACCEngaged 0 "Not_Engaged" 1 "Engaged";
VAL_ 1155 BSM_THA_Brk_Resp 0 "Off" 1 "Active" 2 "Brakes Overheated" 3 "SNA";
VAL_ 1155 BSMSysSts 0 "Normal mode" 1 "Diagnosis mode" 2 "Alternative mode" 3 "SNA";
VAL_ 1155 CMMIntervention 0 "No_intervention" 1 "Intervention";
VAL_ 1155 EBDFailSts 0 "Fail_Not_Present" 1 "Fail_Present";
VAL_ 1155 ERMActive 0 "Not_Active" 1 "Active";
VAL_ 1155 ESCFailSts 0 "Fail_Not_Present" 1 "Fail_Present";
VAL_ 1155 ESCIntervention 0 "No_intervention" 1 "Intervention_blinking_lamp";
VAL_ 1155 Function2Sts 0 "Not_Active" 1 "Active";
VAL_ 1155 FunctionFailSts 0 "Fail_Not_Present" 1 "Fail_Present";
VAL_ 1155 FunctionIntervention 0 "No_intervention" 1 "Intervention_blinking_lamp";
VAL_ 1155 FunctionSts 0 "Not_Active" 1 "Active";
VAL_ 1155 HDCUserFdBck 0 "On" 1 "Off" 2 "Blink" 3 "SNA";
VAL_ 1155 HillHolderFailSts 0 "Fail_Not_Present" 1 "Fail_Present";
VAL_ 1155 LnchCtrl_UserFdBck 0 "OFF" 1 "CONT" 2 "BLINK" 3 "SNA";
VAL_ 1155 RollsModeAct 0 "Not_active" 1 "Active";
VAL_ 1155 TSCActive 0 "Not_Active" 1 "Active";
VAL_ 205 Cmnd_TotBrkFrict_AxleTorq 32767 "SNA";
VAL_ 205 DriverReq_AxleTrq_Enabled_BSM 0 "No_Req" 1 "ACC_NCC" 2 "SSC" 3 "PPPA" 4 "RRCC" 15 "SNA";
VAL_ 205 DriverRequested_AxleTrq_BSM 65535 "SNA";
VAL_ 205 DrvrIntd_TotalBrk_AxleTorq 32767 "SNA";
VAL_ 205 FrontAxle_Max_Rq_BSM 0 "Not_Active" 1 "Active";
VAL_ 205 FrontAxle_Min_Rq_BSM 0 "Not_Active" 1 "Active";
VAL_ 205 FrontAxle_Rq_BSM 65535 "SNA";
VAL_ 205 OPD_Hold_Status 0 "Inactive" 1 "Holding" 2 "Ready_to_Release" 3 "SNA";
VAL_ 205 RearAxle_Max_Rq_BSM 0 "Not_Active" 1 "Active";
VAL_ 205 RearAxle_Min_Rq_BSM 0 "Not_Active" 1 "Active";
VAL_ 205 RearAxle_Rq_BSM 65535 "SNA";
VAL_ 205 Regen_AxleTorque_Req 32767 "SNA";
VAL_ 205 TotalAxle_Max_Rq_BSM 0 "Not_Active" 1 "Active";
VAL_ 205 TotalAxle_Min_Rq_BSM 0 "Not_Active" 1 "Active";
VAL_ 205 TotalAxle_Rq_BSM 65535 "SNA";
VAL_ 205 WED_MODE_RQ 0 "FREE" 1 "HOLD" 2 "OPEN" 3 "SNA";
VAL_ 514 AEB_Type_Brk 0 "NONE" 1 "ACC" 2 "CMS" 3 "CMS_XTD" 4 "ABA" 5 "LSCM" 6 "PEB" 7 "ICA_L" 8 "ICA_R" 9 "HAS_MRM" 10 "RRCC" 11 "L3" 15 "SNA";
VAL_ 514 Brake_OpStat_Prim 0 "Inactive" 1 "FullService" 2 "FailOperational" 3 "FailDegraded" 4 "Emergency" 5 "No_Function";
VAL_ 514 BrakePdlPosn 255 "SNA";
VAL_ 514 BrkPdl_Flt 0 "NOT FAULTED" 1 "FAULTED";
VAL_ 514 BrkPdl_Stat 0 "UPSTOP" 1 "PSD" 2 "NDEF2" 3 "SNA";
VAL_ 514 BSM_OpStat 0 "Inactive" 1 "FullService" 2 "FailOperational" 3 "FailDegraded" 4 "Emergency" 5 "No_Function";
VAL_ 514 BSM_ReadyForESS 0 "Not_Ready" 1 "Ready" 2 "Active" 3 "SNA";
VAL_ 514 PAM_Brk_Rq_RspSts 0 "Not_Active" 1 "Active" 2 "Faulted_Condition" 3 "SNA";
VAL_ 514 R_DIFF_TRQ_RQ 511 "SNA";
VAL_ 514 Rear_Diff_BSM_RQ 0 "FREE" 1 "HOLD" 2 "OPEN" 3 "SNA";
VAL_ 514 TrlrBrkRq 63 "SNA";
VAL_ 257 Ft_RrAxleCoupling_TrqRq_B2 255 "SNA";
VAL_ 257 Ft_RrTrqCoupling_ModeRq_B2 0 "FREE" 1 "HOLD" 2 "OPEN" 3 "SNA";
VAL_ 524 Brake_OpStat_Sec 0 "Inactive" 1 "FullService" 2 "FailOperational" 3 "FailDegraded" 4 "Emergency" 5 "No_Function";
VAL_ 524 BSM2_OpStat 0 "Inactive" 1 "FullService" 2 "FailOperational" 3 "FailDegraded" 4 "Emergency" 5 "No_Function";
VAL_ 524 VehicleStandStillSts_B2 0 "True" 1 "False" 3 "SNA";
